[part 15 of 23: packages /Cluster to /NmConfig]
AUTOSAR XML (schema 4-3-0)
package /Cluster  (continued)
  7 x lin cluster, all with baudrate=19200, protocol-name=LIN, protocol-version=2.0:  (continued)
    Klima_LIN5
      lin physical channel CHNL: comm-connectors=CN_Klima_LIN5
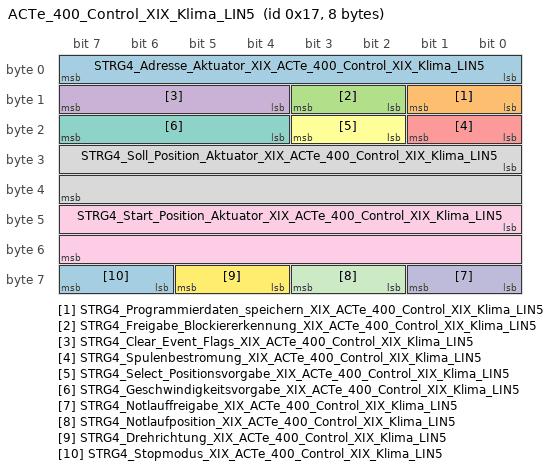
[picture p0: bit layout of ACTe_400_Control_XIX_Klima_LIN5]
        frame ACTe_400_Control_XIX_Klima_LIN5: id 0x17, from Klima, frame-length=8, lin-checksum=ENHANCED
          pdu ACTe_400_Control_XIX_Klima_LIN5: length=8, unused-bit-pattern=0
            signal STRG4_Adresse_Aktuator_XIX_ACTe_400_Control_XIX_Klima_LIN5: start 0, 8 bit, little-endian, data-type-policy=OVERRIDE, i-signal-type=PRIMITIVE, base-type=BT_STRG4_Adresse_Aktuator, invalid-value=Invalid_STRG4_Adresse_Aktuator_XIX_ACTe_400_Control_XIX_Klima_LIN5:255, compu {phys=raw for raw 0..254, 127=Cx7f_Broadcast (CM_STRG4_Adresse_Aktuator_Cx7f_Broadcast), 255=Cxff_Fehler (CM_STRG4_Adresse_Aktuator_Cxff_Fehler); unit Unit_None}, range phys 0..254 Unit_None, raw 0..255, unit=Unit_None, transfer-property=PENDING  # Zielempfängerauswahl, Steuerungsbotschaft für Aktuatoren
            signal STRG4_Programmierdaten_speichern_XIX_ACTe_400_Control_XIX_Klima_LIN5: start 8, 2 bit, little-endian, data-type-policy=OVERRIDE, i-signal-type=PRIMITIVE, init-value=0, base-type=BT_STRG4_Programmierdaten_speichern, invalid-value=Invalid_STRG4_Programmierdaten_speichern_XIX_ACTe_400_Control_XIX_Klima_LIN5:3, compu {0=Cx0_Programmierdaten_nicht_speichern (CM_STRG4_Programmierdaten_speichern_Cx0_Programmierdaten_nicht_speichern), 1=Cx1_Programmierdaten_speichern (CM_STRG4_Programmierdaten_speichern_Cx1_Programmierdaten_speichern), 2=Cx2_reserviert (CM_STRG4_Programmierdaten_speichern_Cx2_reserviert), 3=Cx3_Fehler (CM_STRG4_Programmierdaten_speichern_Cx3_Fehler)}, range raw 0..3, transfer-property=PENDING  # Speicherung der Programmierdaten
            signal STRG4_Freigabe_Blockiererkennung_XIX_ACTe_400_Control_XIX_Klima_LIN5: start 10, 2 bit, little-endian, data-type-policy=OVERRIDE, i-signal-type=PRIMITIVE, base-type=BT_STRG4_Freigabe_Blockiererkennung, invalid-value=Invalid_STRG4_Freigabe_Blockiererkennung_XIX_ACTe_400_Control_XIX_Klima_LIN5:3, compu {0=Cx0_Blockiererkennung_aus (CM_STRG4_Freigabe_Blockiererkennung_Cx0_Blockiererkennung_aus), 1=Cx1_Blockiererkennung_ein (CM_STRG4_Freigabe_Blockiererkennung_Cx1_Blockiererkennung_ein), 2=Cx2_reserviert (CM_STRG4_Freigabe_Blockiererkennung_Cx2_reserviert), 3=Cx3_Fehler (CM_STRG4_Freigabe_Blockiererkennung_Cx3_Fehler)}, range raw 0..3, transfer-property=PENDING  # Das Master-SG gibt eine aktive oder inaktive Blockiererkennung vor
            signal STRG4_Clear_Event_Flags_XIX_ACTe_400_Control_XIX_Klima_LIN5: start 12, 4 bit, little-endian, data-type-policy=OVERRIDE, i-signal-type=PRIMITIVE, init-value=0, base-type=BT_STRG4_Clear_Event_Flags, invalid-value=Invalid_STRG4_Clear_Event_Flags_XIX_ACTe_400_Control_XIX_Klima_LIN5:15, compu {0=Cx0_Event_Flags_nicht_zuruecksetzen (CM_STRG4_Clear_Event_Flags_Cx0_Event_Flags_nicht_zuruecksetzen), 2=Cx2_Clear_Notlauf_aufgetreten (CM_STRG4_Clear_Event_Flags_Cx2_Clear_Notlauf_aufgetreten), 4=Cx4_Clear_Blockierung_aufgetreten (CM_STRG4_Clear_Event_Flags_Cx4_Clear_Blockierung_aufgetreten), 6=Cx6_Clear_Notlauf_und_Blockierung (CM_STRG4_Clear_Event_Flags_Cx6_Clear_Notlauf_und_Blockierung), 8=Cx8_Clear_Reset (CM_STRG4_Clear_Event_Flags_Cx8_Clear_Reset), 10=Cxa_Clear_Notlauf_und_Reset (CM_STRG4_Clear_Event_Flags_Cxa_Clear_Notlauf_und_Reset), 12=Cxc_Clear_Blockierung_und_Reset (CM_STRG4_Clear_Event_Flags_Cxc_Clear_Blockierung_und_Reset), 14=Cxe_Clear_Notlauf_und_Block_u_Reset (CM_STRG4_Clear_Event_Flags_Cxe_Clear_Notlauf_und_Block_u_Reset), 15=Cxf_Fehler (CM_STRG4_Clear_Event_Flags_Cxf_Fehler)}, range raw 0..15, transfer-property=PENDING  # Das Steuergerät löscht die Event-Flags
            signal STRG4_Spulenbestromung_XIX_ACTe_400_Control_XIX_Klima_LIN5: start 16, 2 bit, little-endian, data-type-policy=OVERRIDE, i-signal-type=PRIMITIVE, base-type=BT_STRG4_Spulenbestromung, invalid-value=Invalid_STRG4_Spulenbestromung_XIX_ACTe_400_Control_XIX_Klima_LIN5:3, compu {0=Cx0_Motorspulen_unbestromt (CM_STRG4_Spulenbestromung_Cx0_Motorspulen_unbestromt), 1=Cx1_Motorspulen_bestromt (CM_STRG4_Spulenbestromung_Cx1_Motorspulen_bestromt), 2=Cx2_reserviert (CM_STRG4_Spulenbestromung_Cx2_reserviert), 3=Cx3_Fehler (CM_STRG4_Spulenbestromung_Cx3_Fehler)}, range raw 0..3, transfer-property=PENDING  # Spulenbestromungszustandsvorgabe, Steuerungsbotschaft für Aktuatoren
            signal STRG4_Select_Positionsvorgabe_XIX_ACTe_400_Control_XIX_Klima_LIN5: start 18, 2 bit, little-endian, data-type-policy=OVERRIDE, i-signal-type=PRIMITIVE, init-value=2, base-type=BT_STRG4_Select_Positionsvorgabe, invalid-value=Invalid_STRG4_Select_Positionsvorgabe_XIX_ACTe_400_Control_XIX_Klima_LIN5:3, compu {0=Cx0_Soll_Position_gueltig (CM_STRG4_Select_Positionsvorgabe_Cx0_Soll_Position_gueltig), 1=Cx1_Start_Position_gueltig (CM_STRG4_Select_Positionsvorgabe_Cx1_Start_Position_gueltig), 2=Cx2_keine_Positionsvorgabe_gueltig (CM_STRG4_Select_Positionsvorgabe_Cx2_keine_Positionsvorgabe_gueltig), 3=Cx3_Fehler (CM_STRG4_Select_Positionsvorgabe_Cx3_Fehler)}, range raw 0..3, transfer-property=PENDING  # Vorgabe der Gültigkeit der Positionsvorgaben, Steuerungsbotschaft für Aktuatoren
            signal STRG4_Geschwindigkeitsvorgabe_XIX_ACTe_400_Control_XIX_Klima_LIN5: start 20, 4 bit, little-endian, data-type-policy=OVERRIDE, i-signal-type=PRIMITIVE, base-type=BT_STRG4_Geschwindigkeitsvorgabe, invalid-value=Invalid_STRG4_Geschwindigkeitsvorgabe_XIX_ACTe_400_Control_XIX_Klima_LIN5:15, compu {0=Cx0_reserviert (CM_STRG4_Geschwindigkeitsvorgabe_Cx0_reserviert), 1=Cx1_Geschwindigkeitsstufe_1 (CM_STRG4_Geschwindigkeitsvorgabe_Cx1_Geschwindigkeitsstufe_1), 2=Cx2_Geschwindigkeitsstufe_2 (CM_STRG4_Geschwindigkeitsvorgabe_Cx2_Geschwindigkeitsstufe_2), 3=Cx3_Geschwindigkeitsstufe_3 (CM_STRG4_Geschwindigkeitsvorgabe_Cx3_Geschwindigkeitsstufe_3), 4=Cx4_Geschwindigkeitsstufe_4 (CM_STRG4_Geschwindigkeitsvorgabe_Cx4_Geschwindigkeitsstufe_4), 5=Cx5_Autospeed (CM_STRG4_Geschwindigkeitsvorgabe_Cx5_Autospeed), 15=Cxf_Fehler (CM_STRG4_Geschwindigkeitsvorgabe_Cxf_Fehler)}, range raw 0..15, transfer-property=PENDING  # Vorgabe der Geschwindigkeit, Steuerungsbotschaft für Aktuatoren
            signal STRG4_Soll_Position_Aktuator_XIX_ACTe_400_Control_XIX_Klima_LIN5: start 24, 16 bit, little-endian, data-type-policy=OVERRIDE, i-signal-type=PRIMITIVE, base-type=BT_STRG4_Soll_Position_Aktuator, invalid-value=Invalid_STRG4_Soll_Position_Aktuator_XIX_ACTe_400_Control_XIX_Klima_LIN5:65535, compu {phys=raw for raw 0..65534, 65535=Cxffff_Fehler (CM_STRG4_Soll_Position_Aktuator_Cxffff_Fehler); unit Unit_None}, range phys 0..65534 Unit_None, raw 0..65535, unit=Unit_None, transfer-property=PENDING  # Vorgabe der Sollposition, Steuerungsbotschaft für die Aktuatoren
            signal STRG4_Start_Position_Aktuator_XIX_ACTe_400_Control_XIX_Klima_LIN5: start 40, 16 bit, little-endian, data-type-policy=OVERRIDE, i-signal-type=PRIMITIVE, base-type=BT_STRG4_Start_Position_Aktuator, invalid-value=Invalid_STRG4_Start_Position_Aktuator_XIX_ACTe_400_Control_XIX_Klima_LIN5:65535, compu {phys=raw for raw 0..65534, 65535=Cxffff_Fehler (CM_STRG4_Start_Position_Aktuator_Cxffff_Fehler); unit Unit_None}, range phys 0..65534 Unit_None, raw 0..65535, unit=Unit_None, transfer-property=PENDING  # Vorgabe der Startposition
            signal STRG4_Notlauffreigabe_XIX_ACTe_400_Control_XIX_Klima_LIN5: start 56, 2 bit, little-endian, data-type-policy=OVERRIDE, i-signal-type=PRIMITIVE, base-type=BT_STRG4_Notlauffreigabe, invalid-value=Invalid_STRG4_Notlauffreigabe_XIX_ACTe_400_Control_XIX_Klima_LIN5:3, compu {0=Cx0_Notlauf_aus (CM_STRG4_Notlauffreigabe_Cx0_Notlauf_aus), 1=Cx1_Notlauf_ein (CM_STRG4_Notlauffreigabe_Cx1_Notlauf_ein), 2=Cx2_reserviert (CM_STRG4_Notlauffreigabe_Cx2_reserviert), 3=Cx3_Fehler (CM_STRG4_Notlauffreigabe_Cx3_Fehler)}, range raw 0..3, transfer-property=PENDING  # Freigabe der Notlaufeigenschaft, Steuerungsbotschaft für Aktuatoren
            signal STRG4_Notlaufposition_XIX_ACTe_400_Control_XIX_Klima_LIN5: start 58, 2 bit, little-endian, data-type-policy=OVERRIDE, i-signal-type=PRIMITIVE, base-type=BT_STRG4_Notlaufposition, invalid-value=Invalid_STRG4_Notlaufposition_XIX_ACTe_400_Control_XIX_Klima_LIN5:3, compu {0=Cx0_unterer_Anschlag (CM_STRG4_Notlaufposition_Cx0_unterer_Anschlag), 1=Cx1_oberer_Anschlag (CM_STRG4_Notlaufposition_Cx1_oberer_Anschlag), 2=Cx2_reserviert (CM_STRG4_Notlaufposition_Cx2_reserviert), 3=Cx3_Fehler (CM_STRG4_Notlaufposition_Cx3_Fehler)}, range raw 0..3, transfer-property=PENDING  # Positionsvorgabe, welche bei aktiven Notlauf angelaufen wird
            signal STRG4_Drehrichtung_XIX_ACTe_400_Control_XIX_Klima_LIN5: start 60, 2 bit, little-endian, data-type-policy=OVERRIDE, i-signal-type=PRIMITIVE, base-type=BT_STRG4_Drehrichtung, invalid-value=Invalid_STRG4_Drehrichtung_XIX_ACTe_400_Control_XIX_Klima_LIN5:3, compu {0=Cx0_Bewegung_in_Richtung_CW (CM_STRG4_Drehrichtung_Cx0_Bewegung_in_Richtung_CW), 1=Cx1_Bewegung_in_Richtung_CCW (CM_STRG4_Drehrichtung_Cx1_Bewegung_in_Richtung_CCW), 2=Cx2_reserviert (CM_STRG4_Drehrichtung_Cx2_reserviert), 3=Cx3_Fehler (CM_STRG4_Drehrichtung_Cx3_Fehler)}, range raw 0..3, transfer-property=PENDING  # Vorgabe der Drehrichtung
            signal STRG4_Stopmodus_XIX_ACTe_400_Control_XIX_Klima_LIN5: start 62, 2 bit, little-endian, data-type-policy=OVERRIDE, i-signal-type=PRIMITIVE, base-type=BT_STRG4_Stopmodus, invalid-value=Invalid_STRG4_Stopmodus_XIX_ACTe_400_Control_XIX_Klima_LIN5:3, compu {0=Cx0_normal_mode (CM_STRG4_Stopmodus_Cx0_normal_mode), 1=Cx1_stop_mode (CM_STRG4_Stopmodus_Cx1_stop_mode), 2=Cx2_reserviert (CM_STRG4_Stopmodus_Cx2_reserviert), 3=Cx3_Fehler (CM_STRG4_Stopmodus_Cx3_Fehler)}, range raw 0..3, transfer-property=PENDING  # Vorgabe des StopModus
        frame ACTs_401_Status_XIX_Klima_LIN5: id 0x18, to Klima, frame-length=8, lin-checksum=ENHANCED
          pdu ACTs_401_Status_XIX_Klima_LIN5: length=8, unused-bit-pattern=0
            signal ACT401_ResponseError_XIX_ACTs_401_Status_XIX_Klima_LIN5: start 0, 1 bit, little-endian, data-type-policy=OVERRIDE, i-signal-type=PRIMITIVE, init-value=0, base-type=BT_ACT401_ResponseError, invalid-value=Invalid_ACT401_ResponseError_XIX_ACTs_401_Status_XIX_Klima_LIN5:1, compu {0=Cx0_normal (CM_ACT401_ResponseError_Cx0_normal), 1=Cx1_Fehler (CM_ACT401_ResponseError_Cx1_Fehler)}, range raw 0..1, transfer-property=PENDING, to Klima(timeout 3.5 s)  # siehe LIN2.0-Specification (Darf nicht über ein Fehlergueltigkeitsbit abgesichtert werden!)
            signal ACT401_Uebertemperatur_XIX_ACTs_401_Status_XIX_Klima_LIN5: start 2, 2 bit, little-endian, data-type-policy=OVERRIDE, i-signal-type=PRIMITIVE, init-value=0, base-type=BT_ACT401_Uebertemperatur, invalid-value=Invalid_ACT401_Uebertemperatur_XIX_ACTs_401_Status_XIX_Klima_LIN5:3, compu {0=Cx0_keine_Uebertemperatur (CM_ACT401_Uebertemperatur_Cx0_keine_Uebertemperatur), 1=Cx1_Uebertemperatur (CM_ACT401_Uebertemperatur_Cx1_Uebertemperatur), 2=Cx2_reserviert (CM_ACT401_Uebertemperatur_Cx2_reserviert), 3=Cx3_Fehler (CM_ACT401_Uebertemperatur_Cx3_Fehler)}, range raw 0..3, transfer-property=PENDING, to Klima(timeout 3.5 s)  # Anzeige einer Übertemperatur im Stellmotoren-ASIC
            signal ACT401_Elektr_Defekt_XIX_ACTs_401_Status_XIX_Klima_LIN5: start 4, 2 bit, little-endian, data-type-policy=OVERRIDE, i-signal-type=PRIMITIVE, init-value=0, base-type=BT_ACT401_Elektr_Defekt, invalid-value=Invalid_ACT401_Elektr_Defekt_XIX_ACTs_401_Status_XIX_Klima_LIN5:3, compu {0=Cx0_kein_Fehler (CM_ACT401_Elektr_Defekt_Cx0_kein_Fehler), 1=Cx1_Elektrischer_Fehler_vorhanden (CM_ACT401_Elektr_Defekt_Cx1_Elektrischer_Fehler_vorhanden), 2=Cx2_Permanent_elekt_Fehler_vorhanden (CM_ACT401_Elektr_Defekt_Cx2_Permanent_elekt_Fehler_vorhanden), 3=Cx3_Fehler (CM_ACT401_Elektr_Defekt_Cx3_Fehler)}, range raw 0..3, transfer-property=PENDING, to Klima(timeout 3.5 s)  # Anzeige für einen elektrischen Fehler oder einen permanent el. Fehler im Stellmotor
            signal ACT401_Versorgungsspannung_XIX_ACTs_401_Status_XIX_Klima_LIN5: start 6, 2 bit, little-endian, data-type-policy=OVERRIDE, i-signal-type=PRIMITIVE, init-value=0, base-type=BT_ACT401_Versorgungsspannung, invalid-value=Invalid_ACT401_Versorgungsspannung_XIX_ACTs_401_Status_XIX_Klima_LIN5:3, compu {0=Cx0_Spannung_im_zulaessigen_Bereich (CM_ACT401_Versorgungsspannung_Cx0_Spannung_im_zulaessigen_Bereich), 1=Cx1_Unterspannung (CM_ACT401_Versorgungsspannung_Cx1_Unterspannung), 2=Cx2_Ueberspanung (CM_ACT401_Versorgungsspannung_Cx2_Ueberspanung), 3=Cx3_Fehler (CM_ACT401_Versorgungsspannung_Cx3_Fehler)}, range raw 0..3, transfer-property=PENDING, to Klima(timeout 3.5 s)  # Versorgungsspannung des Aktuators
            signal ACT401_Notlauf_aufgetreten_XIX_ACTs_401_Status_XIX_Klima_LIN5: start 8, 2 bit, little-endian, data-type-policy=OVERRIDE, i-signal-type=PRIMITIVE, init-value=0, base-type=BT_ACT401_Notlauf_aufgetreten, invalid-value=Invalid_ACT401_Notlauf_aufgetreten_XIX_ACTs_401_Status_XIX_Klima_LIN5:3, compu {0=Cx0_kein_Notlauf_aufgetreten (CM_ACT401_Notlauf_aufgetreten_Cx0_kein_Notlauf_aufgetreten), 1=Cx1_Notlauf_aufgetreten (CM_ACT401_Notlauf_aufgetreten_Cx1_Notlauf_aufgetreten), 2=Cx2_reserviert (CM_ACT401_Notlauf_aufgetreten_Cx2_reserviert), 3=Cx3_Fehler (CM_ACT401_Notlauf_aufgetreten_Cx3_Fehler)}, range raw 0..3, transfer-property=PENDING, to Klima(timeout 3.5 s)  # Anzeige eines aufgetretenen Notlaufs seit dem letzten Reset oder "Clear Notlauf aufgetreten"
            signal ACT401_Freigabe_Blockiererkennung_XIX_ACTs_401_Status_XIX_Klima_LIN5: start 10, 2 bit, little-endian, data-type-policy=OVERRIDE, i-signal-type=PRIMITIVE, init-value=0, base-type=BT_ACT401_Freigabe_Blockiererkennung, invalid-value=Invalid_ACT401_Freigabe_Blockiererkennung_XIX_ACTs_401_Status_XIX_Klima_LIN5:3, compu {0=Cx0_Blockiererkennung_aus (CM_ACT401_Freigabe_Blockiererkennung_Cx0_Blockiererkennung_aus), 1=Cx1_Blockiererkennung_ein (CM_ACT401_Freigabe_Blockiererkennung_Cx1_Blockiererkennung_ein), 2=Cx2_reserviert (CM_ACT401_Freigabe_Blockiererkennung_Cx2_reserviert), 3=Cx3_Fehler (CM_ACT401_Freigabe_Blockiererkennung_Cx3_Fehler)}, range raw 0..3, transfer-property=PENDING, to Klima(timeout 3.5 s)  # Aktivierung der Blockiererkennung im Aktuator
            signal ACT401_Blockierung_aufgetreten_XIX_ACTs_401_Status_XIX_Klima_LIN5: start 12, 2 bit, little-endian, data-type-policy=OVERRIDE, i-signal-type=PRIMITIVE, init-value=0, base-type=BT_ACT401_Blockierung_aufgetreten, invalid-value=Invalid_ACT401_Blockierung_aufgetreten_XIX_ACTs_401_Status_XIX_Klima_LIN5:3, compu {0=Cx0_keine_Blockierung (CM_ACT401_Blockierung_aufgetreten_Cx0_keine_Blockierung), 1=Cx1_Blockierung_erkannt (CM_ACT401_Blockierung_aufgetreten_Cx1_Blockierung_erkannt), 2=Cx2_reserviert (CM_ACT401_Blockierung_aufgetreten_Cx2_reserviert), 3=Cx3_Fehler (CM_ACT401_Blockierung_aufgetreten_Cx3_Fehler)}, range raw 0..3, transfer-property=PENDING, to Klima(timeout 3.5 s)  # Anzeige einer aufgetretenen Blockierung seit dem letzten Reset oder "Clear Blockierung aufgetreten"
            signal ACT401_Reset_XIX_ACTs_401_Status_XIX_Klima_LIN5: start 14, 2 bit, little-endian, data-type-policy=OVERRIDE, i-signal-type=PRIMITIVE, init-value=0, base-type=BT_ACT401_Reset, invalid-value=Invalid_ACT401_Reset_XIX_ACTs_401_Status_XIX_Klima_LIN5:3, compu {0=Cx0_kein_Reset (CM_ACT401_Reset_Cx0_kein_Reset), 1=Cx1_Reset_durchgefuehrt (CM_ACT401_Reset_Cx1_Reset_durchgefuehrt), 2=Cx2_reserviert (CM_ACT401_Reset_Cx2_reserviert), 3=Cx3_Fehler (CM_ACT401_Reset_Cx3_Fehler)}, range raw 0..3, transfer-property=PENDING, to Klima(timeout 3.5 s)  # Anzeige eines aufgetretenen Reset seit dem letzten ¿Clear Reset"
            signal ACT401_Spulenbestromung_XIX_ACTs_401_Status_XIX_Klima_LIN5: start 16, 2 bit, little-endian, data-type-policy=OVERRIDE, i-signal-type=PRIMITIVE, init-value=0, base-type=BT_ACT401_Spulenbestromung, invalid-value=Invalid_ACT401_Spulenbestromung_XIX_ACTs_401_Status_XIX_Klima_LIN5:3, compu {0=Cx0_Motorspulen_unbestromt (CM_ACT401_Spulenbestromung_Cx0_Motorspulen_unbestromt), 1=Cx1_Motorspulen_bestromt (CM_ACT401_Spulenbestromung_Cx1_Motorspulen_bestromt), 2=Cx2_reserviert (CM_ACT401_Spulenbestromung_Cx2_reserviert), 3=Cx3_Fehler (CM_ACT401_Spulenbestromung_Cx3_Fehler)}, range raw 0..3, transfer-property=PENDING, to Klima(timeout 3.5 s)  # Spulenbestromung im Haltezustand des Aktuators
            signal ACT401_Positionsvorgabe_Status_XIX_ACTs_401_Status_XIX_Klima_LIN5: start 18, 2 bit, little-endian, data-type-policy=OVERRIDE, i-signal-type=PRIMITIVE, init-value=0, base-type=BT_ACT401_Positionsvorgabe_Status, invalid-value=Invalid_ACT401_Positionsvorgabe_Status_XIX_ACTs_401_Status_XIX_Klima_LIN5:3, compu {0=Cx0_Soll_Position_gueltig (CM_ACT401_Positionsvorgabe_Status_Cx0_Soll_Position_gueltig), 1=Cx1_Start_Position_gueltig (CM_ACT401_Positionsvorgabe_Status_Cx1_Start_Position_gueltig), 2=Cx2_keine_Positionsvorgabe_gueltig (CM_ACT401_Positionsvorgabe_Status_Cx2_keine_Positionsvorgabe_gueltig), 3=Cx3_Fehler (CM_ACT401_Positionsvorgabe_Status_Cx3_Fehler)}, range raw 0..3, transfer-property=PENDING, to Klima(timeout 3.5 s)  # Position des Aktuators
            signal ACT401_Geschwindigkeitsstatus_XIX_ACTs_401_Status_XIX_Klima_LIN5: start 20, 4 bit, little-endian, data-type-policy=OVERRIDE, i-signal-type=PRIMITIVE, init-value=0, base-type=BT_ACT401_Geschwindigkeitsstatus, invalid-value=Invalid_ACT401_Geschwindigkeitsstatus_XIX_ACTs_401_Status_XIX_Klima_LIN5:15, compu {0=Cx0_Motor_steht (CM_ACT401_Geschwindigkeitsstatus_Cx0_Motor_steht), 1=Cx1_Geschwindigkeitsstufe_1 (CM_ACT401_Geschwindigkeitsstatus_Cx1_Geschwindigkeitsstufe_1), 2=Cx2_Geschwindigkeitsstufe_2 (CM_ACT401_Geschwindigkeitsstatus_Cx2_Geschwindigkeitsstufe_2), 3=Cx3_Geschwindigkeitsstufe_3 (CM_ACT401_Geschwindigkeitsstatus_Cx3_Geschwindigkeitsstufe_3), 4=Cx4_Geschwindigkeitsstufe_4 (CM_ACT401_Geschwindigkeitsstatus_Cx4_Geschwindigkeitsstufe_4), 5=Cx5_Autospeed (CM_ACT401_Geschwindigkeitsstatus_Cx5_Autospeed), 15=Cxf_Fehler (CM_ACT401_Geschwindigkeitsstatus_Cxf_Fehler)}, range raw 0..15, transfer-property=PENDING, to Klima(timeout 3.5 s)  # Geschwindigkeitsstufe mit der die aktuelle Verfahrbewegung durchgeführt wird
            signal ACT401_Ist_Position_Aktuator_XIX_ACTs_401_Status_XIX_Klima_LIN5: start 24, 16 bit, little-endian, data-type-policy=OVERRIDE, i-signal-type=PRIMITIVE, init-value=32767, base-type=BT_ACT401_Ist_Position_Aktuator, invalid-value=Invalid_ACT401_Ist_Position_Aktuator_XIX_ACTs_401_Status_XIX_Klima_LIN5:65535, compu {phys=raw for raw 0..65534, 32767=Cx7fff_Init (CM_ACT401_Ist_Position_Aktuator_Cx7fff_Init), 65535=Cxffff_Fehler (CM_ACT401_Ist_Position_Aktuator_Cxffff_Fehler); unit Unit_None}, range phys 0..65534 Unit_None, raw 0..65535, unit=Unit_None, transfer-property=PENDING, to Klima(timeout 3.5 s)  # IST-Position des Aktuators
            signal ACT401_Verfahrrichtung_XIX_ACTs_401_Status_XIX_Klima_LIN5: start 40, 2 bit, little-endian, data-type-policy=OVERRIDE, i-signal-type=PRIMITIVE, init-value=2, base-type=BT_ACT401_Verfahrrichtung, invalid-value=Invalid_ACT401_Verfahrrichtung_XIX_ACTs_401_Status_XIX_Klima_LIN5:3, compu {0=Cx0_Richtung_kl_Schrittpositionen (CM_ACT401_Verfahrrichtung_Cx0_Richtung_kl_Schrittpositionen), 1=Cx1_Richtung_gr_Schrittpositionen (CM_ACT401_Verfahrrichtung_Cx1_Richtung_gr_Schrittpositionen), 2=Cx2_Init (CM_ACT401_Verfahrrichtung_Cx2_Init), 3=Cx3_Fehler (CM_ACT401_Verfahrrichtung_Cx3_Fehler)}, range raw 0..3, transfer-property=PENDING, to Klima(timeout 3.5 s)  # Verfahrrichtung der aktuellen oder zuletzt stattgefundenen Bewegung des Aktuators
            signal ACT401_Selbsthaltemoment_XIX_ACTs_401_Status_XIX_Klima_LIN5: start 42, 2 bit, little-endian, data-type-policy=OVERRIDE, i-signal-type=PRIMITIVE, init-value=0, base-type=BT_ACT401_Selbsthaltemoment, invalid-value=Invalid_ACT401_Selbsthaltemoment_XIX_ACTs_401_Status_XIX_Klima_LIN5:3, compu {0=Cx0_ohne_Selbsthaltemoment (CM_ACT401_Selbsthaltemoment_Cx0_ohne_Selbsthaltemoment), 1=Cx1_mit_Selbsthaltemoment (CM_ACT401_Selbsthaltemoment_Cx1_mit_Selbsthaltemoment), 2=Cx2_reserviert (CM_ACT401_Selbsthaltemoment_Cx2_reserviert), 3=Cx3_Fehler (CM_ACT401_Selbsthaltemoment_Cx3_Fehler)}, range raw 0..3, transfer-property=PENDING, to Klima(timeout 3.5 s)  # Das Signal gibt an ob ein selbsthemmendes Getriebe verbaut ist oder die SHB eingeschaltet ist
            signal ACT401_Sonderfunktionen_XIX_ACTs_401_Status_XIX_Klima_LIN5: start 44, 2 bit, little-endian, data-type-policy=OVERRIDE, i-signal-type=PRIMITIVE, init-value=0, base-type=BT_ACT401_Sonderfunktionen, invalid-value=Invalid_ACT401_Sonderfunktionen_XIX_ACTs_401_Status_XIX_Klima_LIN5:3, compu {0=Cx0_Keine_Sonderfunktion_aktiv (CM_ACT401_Sonderfunktionen_Cx0_Keine_Sonderfunktion_aktiv), 1=Cx1_Sonderfunktion1_aktiv (CM_ACT401_Sonderfunktionen_Cx1_Sonderfunktion1_aktiv), 2=Cx2_Sonderfunktion2_aktiv (CM_ACT401_Sonderfunktionen_Cx2_Sonderfunktion2_aktiv), 3=Cx3_Fehler (CM_ACT401_Sonderfunktionen_Cx3_Fehler)}, range raw 0..3, transfer-property=PENDING, to Klima(timeout 3.5 s)  # Funktionen des Aktuators
            signal ACT401_Variante_XIX_ACTs_401_Status_XIX_Klima_LIN5: start 46, 2 bit, little-endian, data-type-policy=OVERRIDE, i-signal-type=PRIMITIVE, init-value=0, base-type=BT_ACT401_Variante, compu {0=Cx0_Variante_1 (CM_ACT401_Variante_Cx0_Variante_1), 1=Cx1_Variante_2 (CM_ACT401_Variante_Cx1_Variante_2), 2=Cx2_Variante_3 (CM_ACT401_Variante_Cx2_Variante_3), 3=Cx3_Fehler_oder_nicht_umgesetzt (CM_ACT401_Variante_Cx3_Fehler_oder_nicht_umgesetzt)}, range raw 0..3, transfer-property=PENDING, to Klima(timeout 3.5 s)  # Das Signal gibt an welche Variante des Stellmotors verbaut ist
            signal ACT401_Adresse_Aktuator_XIX_ACTs_401_Status_XIX_Klima_LIN5: start 48, 8 bit, little-endian, data-type-policy=OVERRIDE, i-signal-type=PRIMITIVE, init-value=255, base-type=BT_ACT401_Adresse_Aktuator, compu {255=Cxff_Init (CM_ACT401_Adresse_Aktuator_Cxff_Init)}, range raw 255, transfer-property=PENDING, to Klima(timeout 3.5 s)  # Adresse Aktuator
            signal ACT401_Notlauffreigabe_XIX_ACTs_401_Status_XIX_Klima_LIN5: start 56, 2 bit, little-endian, data-type-policy=OVERRIDE, i-signal-type=PRIMITIVE, init-value=0, base-type=BT_ACT401_Notlauffreigabe, invalid-value=Invalid_ACT401_Notlauffreigabe_XIX_ACTs_401_Status_XIX_Klima_LIN5:3, compu {0=Cx0_Notlauf_aus (CM_ACT401_Notlauffreigabe_Cx0_Notlauf_aus), 1=Cx1_Notlauf_ein (CM_ACT401_Notlauffreigabe_Cx1_Notlauf_ein), 2=Cx2_reserviert (CM_ACT401_Notlauffreigabe_Cx2_reserviert), 3=Cx3_Fehler (CM_ACT401_Notlauffreigabe_Cx3_Fehler)}, range raw 0..3, transfer-property=PENDING, to Klima(timeout 3.5 s)  # Freigabe der Notlauffunktion des Aktuators
            signal ACT401_Notlaufposition_XIX_ACTs_401_Status_XIX_Klima_LIN5: start 58, 2 bit, little-endian, data-type-policy=OVERRIDE, i-signal-type=PRIMITIVE, init-value=0, base-type=BT_ACT401_Notlaufposition, invalid-value=Invalid_ACT401_Notlaufposition_XIX_ACTs_401_Status_XIX_Klima_LIN5:3, compu {0=Cx0_unterer_Anschlag (CM_ACT401_Notlaufposition_Cx0_unterer_Anschlag), 1=Cx1_oberer_Anschlag (CM_ACT401_Notlaufposition_Cx1_oberer_Anschlag), 2=Cx2_reserviert (CM_ACT401_Notlaufposition_Cx2_reserviert), 3=Cx3_Fehler (CM_ACT401_Notlaufposition_Cx3_Fehler)}, range raw 0..3, transfer-property=PENDING, to Klima(timeout 3.5 s)  # Positionsvorgabe des Aktuators
            signal ACT401_Drehrichtung_XIX_ACTs_401_Status_XIX_Klima_LIN5: start 60, 2 bit, little-endian, data-type-policy=OVERRIDE, i-signal-type=PRIMITIVE, init-value=0, base-type=BT_ACT401_Drehrichtung, invalid-value=Invalid_ACT401_Drehrichtung_XIX_ACTs_401_Status_XIX_Klima_LIN5:3, compu {0=Cx0_Bewegung_in_Richtung_CW (CM_ACT401_Drehrichtung_Cx0_Bewegung_in_Richtung_CW), 1=Cx1_Bewegung_in_Richtung_CCW (CM_ACT401_Drehrichtung_Cx1_Bewegung_in_Richtung_CCW), 2=Cx2_reserviert (CM_ACT401_Drehrichtung_Cx2_reserviert), 3=Cx3_Fehler (CM_ACT401_Drehrichtung_Cx3_Fehler)}, range raw 0..3, transfer-property=PENDING, to Klima(timeout 3.5 s)  # Drehrichtung des Aktuators
            signal ACT401_Stopmodus_XIX_ACTs_401_Status_XIX_Klima_LIN5: start 62, 2 bit, little-endian, data-type-policy=OVERRIDE, i-signal-type=PRIMITIVE, init-value=0, base-type=BT_ACT401_Stopmodus, invalid-value=Invalid_ACT401_Stopmodus_XIX_ACTs_401_Status_XIX_Klima_LIN5:3, compu {0=Cx0_Normal_Mode (CM_ACT401_Stopmodus_Cx0_Normal_Mode), 1=Cx1_Stop_Mode (CM_ACT401_Stopmodus_Cx1_Stop_Mode), 2=Cx2_reserviert (CM_ACT401_Stopmodus_Cx2_reserviert), 3=Cx3_Fehler (CM_ACT401_Stopmodus_Cx3_Fehler)}, range raw 0..3, transfer-property=PENDING, to Klima(timeout 3.5 s)  # Modus des Aktuators
        frame ACTs_402_Status_XIX_Klima_LIN5: id 0x19, to Klima, frame-length=8, lin-checksum=ENHANCED
          pdu ACTs_402_Status_XIX_Klima_LIN5: length=8, unused-bit-pattern=0
            signal ACT402_ResponseError_XIX_ACTs_402_Status_XIX_Klima_LIN5: start 0, 1 bit, little-endian, data-type-policy=OVERRIDE, i-signal-type=PRIMITIVE, init-value=0, base-type=BT_ACT402_ResponseError, invalid-value=Invalid_ACT402_ResponseError_XIX_ACTs_402_Status_XIX_Klima_LIN5:1, compu {0=Cx0_normal (CM_ACT402_ResponseError_Cx0_normal), 1=Cx1_Fehler (CM_ACT402_ResponseError_Cx1_Fehler)}, range raw 0..1, transfer-property=PENDING, to Klima(timeout 3.5 s)  # siehe LIN2.0-Specification (Darf nicht über ein Fehlergueltigkeitsbit abgesichtert werden!)
            signal ACT402_Uebertemperatur_XIX_ACTs_402_Status_XIX_Klima_LIN5: start 2, 2 bit, little-endian, data-type-policy=OVERRIDE, i-signal-type=PRIMITIVE, init-value=0, base-type=BT_ACT402_Uebertemperatur, invalid-value=Invalid_ACT402_Uebertemperatur_XIX_ACTs_402_Status_XIX_Klima_LIN5:3, compu {0=Cx0_keine_Uebertemperatur (CM_ACT402_Uebertemperatur_Cx0_keine_Uebertemperatur), 1=Cx1_Uebertemperatur (CM_ACT402_Uebertemperatur_Cx1_Uebertemperatur), 2=Cx2_reserviert (CM_ACT402_Uebertemperatur_Cx2_reserviert), 3=Cx3_Fehler (CM_ACT402_Uebertemperatur_Cx3_Fehler)}, range raw 0..3, transfer-property=PENDING, to Klima(timeout 3.5 s)  # Anzeige einer Übertemperatur im Stellmotoren-ASIC
            signal ACT402_Elektr_Defekt_XIX_ACTs_402_Status_XIX_Klima_LIN5: start 4, 2 bit, little-endian, data-type-policy=OVERRIDE, i-signal-type=PRIMITIVE, init-value=0, base-type=BT_ACT402_Elektr_Defekt, invalid-value=Invalid_ACT402_Elektr_Defekt_XIX_ACTs_402_Status_XIX_Klima_LIN5:3, compu {0=Cx0_kein_Fehler (CM_ACT402_Elektr_Defekt_Cx0_kein_Fehler), 1=Cx1_Elektrischer_Fehler_vorhanden (CM_ACT402_Elektr_Defekt_Cx1_Elektrischer_Fehler_vorhanden), 2=Cx2_Permanent_elekt_Fehler_vorhanden (CM_ACT402_Elektr_Defekt_Cx2_Permanent_elekt_Fehler_vorhanden), 3=Cx3_Fehler (CM_ACT402_Elektr_Defekt_Cx3_Fehler)}, range raw 0..3, transfer-property=PENDING, to Klima(timeout 3.5 s)  # Anzeige für einen elektrischen Fehler oder einen permanent el. Fehler im Stellmotor
            signal ACT402_Versorgungsspannung_XIX_ACTs_402_Status_XIX_Klima_LIN5: start 6, 2 bit, little-endian, data-type-policy=OVERRIDE, i-signal-type=PRIMITIVE, init-value=0, base-type=BT_ACT402_Versorgungsspannung, invalid-value=Invalid_ACT402_Versorgungsspannung_XIX_ACTs_402_Status_XIX_Klima_LIN5:3, compu {0=Cx0_Spannung_im_zulaessigen_Bereich (CM_ACT402_Versorgungsspannung_Cx0_Spannung_im_zulaessigen_Bereich), 1=Cx1_Unterspannung (CM_ACT402_Versorgungsspannung_Cx1_Unterspannung), 2=Cx2_Ueberspanung (CM_ACT402_Versorgungsspannung_Cx2_Ueberspanung), 3=Cx3_Fehler (CM_ACT402_Versorgungsspannung_Cx3_Fehler)}, range raw 0..3, transfer-property=PENDING, to Klima(timeout 3.5 s)  # Versorgungsspannung des Aktuators
            signal ACT402_Notlauf_aufgetreten_XIX_ACTs_402_Status_XIX_Klima_LIN5: start 8, 2 bit, little-endian, data-type-policy=OVERRIDE, i-signal-type=PRIMITIVE, init-value=0, base-type=BT_ACT402_Notlauf_aufgetreten, invalid-value=Invalid_ACT402_Notlauf_aufgetreten_XIX_ACTs_402_Status_XIX_Klima_LIN5:3, compu {0=Cx0_kein_Notlauf_aufgetreten (CM_ACT402_Notlauf_aufgetreten_Cx0_kein_Notlauf_aufgetreten), 1=Cx1_Notlauf_aufgetreten (CM_ACT402_Notlauf_aufgetreten_Cx1_Notlauf_aufgetreten), 2=Cx2_reserviert (CM_ACT402_Notlauf_aufgetreten_Cx2_reserviert), 3=Cx3_Fehler (CM_ACT402_Notlauf_aufgetreten_Cx3_Fehler)}, range raw 0..3, transfer-property=PENDING, to Klima(timeout 3.5 s)  # Anzeige eines aufgetretenen Notlaufs seit dem letzten Reset oder "Clear Notlauf aufgetreten"
            signal ACT402_Freigabe_Blockiererkennung_XIX_ACTs_402_Status_XIX_Klima_LIN5: start 10, 2 bit, little-endian, data-type-policy=OVERRIDE, i-signal-type=PRIMITIVE, init-value=0, base-type=BT_ACT402_Freigabe_Blockiererkennung, invalid-value=Invalid_ACT402_Freigabe_Blockiererkennung_XIX_ACTs_402_Status_XIX_Klima_LIN5:3, compu {0=Cx0_Blockiererkennung_aus (CM_ACT402_Freigabe_Blockiererkennung_Cx0_Blockiererkennung_aus), 1=Cx1_Blockiererkennung_ein (CM_ACT402_Freigabe_Blockiererkennung_Cx1_Blockiererkennung_ein), 2=Cx2_reserviert (CM_ACT402_Freigabe_Blockiererkennung_Cx2_reserviert), 3=Cx3_Fehler (CM_ACT402_Freigabe_Blockiererkennung_Cx3_Fehler)}, range raw 0..3, transfer-property=PENDING, to Klima(timeout 3.5 s)  # Aktivierung der Blockiererkennung im Aktuator
            signal ACT402_Blockierung_aufgetreten_XIX_ACTs_402_Status_XIX_Klima_LIN5: start 12, 2 bit, little-endian, data-type-policy=OVERRIDE, i-signal-type=PRIMITIVE, init-value=0, base-type=BT_ACT402_Blockierung_aufgetreten, invalid-value=Invalid_ACT402_Blockierung_aufgetreten_XIX_ACTs_402_Status_XIX_Klima_LIN5:3, compu {0=Cx0_keine_Blockierung (CM_ACT402_Blockierung_aufgetreten_Cx0_keine_Blockierung), 1=Cx1_Blockierung_erkannt (CM_ACT402_Blockierung_aufgetreten_Cx1_Blockierung_erkannt), 2=Cx2_reserviert (CM_ACT402_Blockierung_aufgetreten_Cx2_reserviert), 3=Cx3_Fehler (CM_ACT402_Blockierung_aufgetreten_Cx3_Fehler)}, range raw 0..3, transfer-property=PENDING, to Klima(timeout 3.5 s)  # Anzeige einer aufgetretenen Blockierung seit dem letzten Reset oder "Clear Blockierung aufgetreten"
            signal ACT402_Reset_XIX_ACTs_402_Status_XIX_Klima_LIN5: start 14, 2 bit, little-endian, data-type-policy=OVERRIDE, i-signal-type=PRIMITIVE, init-value=0, base-type=BT_ACT402_Reset, invalid-value=Invalid_ACT402_Reset_XIX_ACTs_402_Status_XIX_Klima_LIN5:3, compu {0=Cx0_kein_Reset (CM_ACT402_Reset_Cx0_kein_Reset), 1=Cx1_Reset_durchgefuehrt (CM_ACT402_Reset_Cx1_Reset_durchgefuehrt), 2=Cx2_reserviert (CM_ACT402_Reset_Cx2_reserviert), 3=Cx3_Fehler (CM_ACT402_Reset_Cx3_Fehler)}, range raw 0..3, transfer-property=PENDING, to Klima(timeout 3.5 s)  # Anzeige eines aufgetretenen Reset seit dem letzten ¿Clear Reset"
            signal ACT402_Spulenbestromung_XIX_ACTs_402_Status_XIX_Klima_LIN5: start 16, 2 bit, little-endian, data-type-policy=OVERRIDE, i-signal-type=PRIMITIVE, init-value=0, base-type=BT_ACT402_Spulenbestromung, invalid-value=Invalid_ACT402_Spulenbestromung_XIX_ACTs_402_Status_XIX_Klima_LIN5:3, compu {0=Cx0_Motorspulen_unbestromt (CM_ACT402_Spulenbestromung_Cx0_Motorspulen_unbestromt), 1=Cx1_Motorspulen_bestromt (CM_ACT402_Spulenbestromung_Cx1_Motorspulen_bestromt), 2=Cx2_reserviert (CM_ACT402_Spulenbestromung_Cx2_reserviert), 3=Cx3_Fehler (CM_ACT402_Spulenbestromung_Cx3_Fehler)}, range raw 0..3, transfer-property=PENDING, to Klima(timeout 3.5 s)  # Spulenbestromung im Haltezustand des Aktuators
            signal ACT402_Positionsvorgabe_Status_XIX_ACTs_402_Status_XIX_Klima_LIN5: start 18, 2 bit, little-endian, data-type-policy=OVERRIDE, i-signal-type=PRIMITIVE, init-value=0, base-type=BT_ACT402_Positionsvorgabe_Status, invalid-value=Invalid_ACT402_Positionsvorgabe_Status_XIX_ACTs_402_Status_XIX_Klima_LIN5:3, compu {0=Cx0_Soll_Position_gueltig (CM_ACT402_Positionsvorgabe_Status_Cx0_Soll_Position_gueltig), 1=Cx1_Start_Position_gueltig (CM_ACT402_Positionsvorgabe_Status_Cx1_Start_Position_gueltig), 2=Cx2_keine_Positionsvorgabe_gueltig (CM_ACT402_Positionsvorgabe_Status_Cx2_keine_Positionsvorgabe_gueltig), 3=Cx3_Fehler (CM_ACT402_Positionsvorgabe_Status_Cx3_Fehler)}, range raw 0..3, transfer-property=PENDING, to Klima(timeout 3.5 s)  # Position des Aktuators
            signal ACT402_Geschwindigkeitsstatus_XIX_ACTs_402_Status_XIX_Klima_LIN5: start 20, 4 bit, little-endian, data-type-policy=OVERRIDE, i-signal-type=PRIMITIVE, init-value=0, base-type=BT_ACT402_Geschwindigkeitsstatus, invalid-value=Invalid_ACT402_Geschwindigkeitsstatus_XIX_ACTs_402_Status_XIX_Klima_LIN5:15, compu {0=Cx0_Motor_steht (CM_ACT402_Geschwindigkeitsstatus_Cx0_Motor_steht), 1=Cx1_Geschwindigkeitsstufe_1 (CM_ACT402_Geschwindigkeitsstatus_Cx1_Geschwindigkeitsstufe_1), 2=Cx2_Geschwindigkeitsstufe_2 (CM_ACT402_Geschwindigkeitsstatus_Cx2_Geschwindigkeitsstufe_2), 3=Cx3_Geschwindigkeitsstufe_3 (CM_ACT402_Geschwindigkeitsstatus_Cx3_Geschwindigkeitsstufe_3), 4=Cx4_Geschwindigkeitsstufe_4 (CM_ACT402_Geschwindigkeitsstatus_Cx4_Geschwindigkeitsstufe_4), 5=Cx5_Autospeed (CM_ACT402_Geschwindigkeitsstatus_Cx5_Autospeed), 15=Cxf_Fehler (CM_ACT402_Geschwindigkeitsstatus_Cxf_Fehler)}, range raw 0..15, transfer-property=PENDING, to Klima(timeout 3.5 s)  # Geschwindigkeitsstufe mit der die aktuelle Verfahrbewegung durchgeführt wird
            signal ACT402_Ist_Position_Aktuator_XIX_ACTs_402_Status_XIX_Klima_LIN5: start 24, 16 bit, little-endian, data-type-policy=OVERRIDE, i-signal-type=PRIMITIVE, init-value=32767, base-type=BT_ACT402_Ist_Position_Aktuator, invalid-value=Invalid_ACT402_Ist_Position_Aktuator_XIX_ACTs_402_Status_XIX_Klima_LIN5:65535, compu {phys=raw for raw 0..65534, 32767=Cx7fff_Init (CM_ACT402_Ist_Position_Aktuator_Cx7fff_Init), 65535=Cxffff_Fehler (CM_ACT402_Ist_Position_Aktuator_Cxffff_Fehler); unit Unit_None}, range phys 0..65534 Unit_None, raw 0..65535, unit=Unit_None, transfer-property=PENDING, to Klima(timeout 3.5 s)  # IST-Position des Aktuators
            signal ACT402_Verfahrrichtung_XIX_ACTs_402_Status_XIX_Klima_LIN5: start 40, 2 bit, little-endian, data-type-policy=OVERRIDE, i-signal-type=PRIMITIVE, init-value=2, base-type=BT_ACT402_Verfahrrichtung, invalid-value=Invalid_ACT402_Verfahrrichtung_XIX_ACTs_402_Status_XIX_Klima_LIN5:3, compu {0=Cx0_Richtung_kl_Schrittpositionen (CM_ACT402_Verfahrrichtung_Cx0_Richtung_kl_Schrittpositionen), 1=Cx1_Richtung_gr_Schrittpositionen (CM_ACT402_Verfahrrichtung_Cx1_Richtung_gr_Schrittpositionen), 2=Cx2_Init (CM_ACT402_Verfahrrichtung_Cx2_Init), 3=Cx3_Fehler (CM_ACT402_Verfahrrichtung_Cx3_Fehler)}, range raw 0..3, transfer-property=PENDING, to Klima(timeout 3.5 s)  # Verfahrrichtung der aktuellen oder zuletzt stattgefundenen Bewegung des Aktuators
            signal ACT402_Selbsthaltemoment_XIX_ACTs_402_Status_XIX_Klima_LIN5: start 42, 2 bit, little-endian, data-type-policy=OVERRIDE, i-signal-type=PRIMITIVE, init-value=0, base-type=BT_ACT402_Selbsthaltemoment, invalid-value=Invalid_ACT402_Selbsthaltemoment_XIX_ACTs_402_Status_XIX_Klima_LIN5:3, compu {0=Cx0_ohne_Selbsthaltemoment (CM_ACT402_Selbsthaltemoment_Cx0_ohne_Selbsthaltemoment), 1=Cx1_mit_Selbsthaltemoment (CM_ACT402_Selbsthaltemoment_Cx1_mit_Selbsthaltemoment), 2=Cx2_reserviert (CM_ACT402_Selbsthaltemoment_Cx2_reserviert), 3=Cx3_Fehler (CM_ACT402_Selbsthaltemoment_Cx3_Fehler)}, range raw 0..3, transfer-property=PENDING, to Klima(timeout 3.5 s)  # Das Signal gibt an ob ein selbsthemmendes Getriebe verbaut ist oder die SHB eingeschaltet ist
            signal ACT402_Sonderfunktionen_XIX_ACTs_402_Status_XIX_Klima_LIN5: start 44, 2 bit, little-endian, data-type-policy=OVERRIDE, i-signal-type=PRIMITIVE, init-value=0, base-type=BT_ACT402_Sonderfunktionen, invalid-value=Invalid_ACT402_Sonderfunktionen_XIX_ACTs_402_Status_XIX_Klima_LIN5:3, compu {0=Cx0_Keine_Sonderfunktion_aktiv (CM_ACT402_Sonderfunktionen_Cx0_Keine_Sonderfunktion_aktiv), 1=Cx1_Sonderfunktion1_aktiv (CM_ACT402_Sonderfunktionen_Cx1_Sonderfunktion1_aktiv), 2=Cx2_Sonderfunktion2_aktiv (CM_ACT402_Sonderfunktionen_Cx2_Sonderfunktion2_aktiv), 3=Cx3_Fehler (CM_ACT402_Sonderfunktionen_Cx3_Fehler)}, range raw 0..3, transfer-property=PENDING, to Klima(timeout 3.5 s)  # Funktionen des Aktuators
            signal ACT402_Variante_XIX_ACTs_402_Status_XIX_Klima_LIN5: start 46, 2 bit, little-endian, data-type-policy=OVERRIDE, i-signal-type=PRIMITIVE, init-value=0, base-type=BT_ACT402_Variante, compu {0=Cx0_Variante_1 (CM_ACT402_Variante_Cx0_Variante_1), 1=Cx1_Variante_2 (CM_ACT402_Variante_Cx1_Variante_2), 2=Cx2_Variante_3 (CM_ACT402_Variante_Cx2_Variante_3), 3=Cx3_Fehler_oder_nicht_umgesetzt (CM_ACT402_Variante_Cx3_Fehler_oder_nicht_umgesetzt)}, range raw 0..3, transfer-property=PENDING, to Klima(timeout 3.5 s)  # Das Signal gibt an welche Variante des Stellmotors verbaut ist
            signal ACT402_Adresse_Aktuator_XIX_ACTs_402_Status_XIX_Klima_LIN5: start 48, 8 bit, little-endian, data-type-policy=OVERRIDE, i-signal-type=PRIMITIVE, init-value=255, base-type=BT_ACT402_Adresse_Aktuator, compu {255=Cxff_Init (CM_ACT402_Adresse_Aktuator_Cxff_Init)}, range raw 255, transfer-property=PENDING, to Klima(timeout 3.5 s)  # Adresse Aktuator
            signal ACT402_Notlauffreigabe_XIX_ACTs_402_Status_XIX_Klima_LIN5: start 56, 2 bit, little-endian, data-type-policy=OVERRIDE, i-signal-type=PRIMITIVE, init-value=0, base-type=BT_ACT402_Notlauffreigabe, invalid-value=Invalid_ACT402_Notlauffreigabe_XIX_ACTs_402_Status_XIX_Klima_LIN5:3, compu {0=Cx0_Notlauf_aus (CM_ACT402_Notlauffreigabe_Cx0_Notlauf_aus), 1=Cx1_Notlauf_ein (CM_ACT402_Notlauffreigabe_Cx1_Notlauf_ein), 2=Cx2_reserviert (CM_ACT402_Notlauffreigabe_Cx2_reserviert), 3=Cx3_Fehler (CM_ACT402_Notlauffreigabe_Cx3_Fehler)}, range raw 0..3, transfer-property=PENDING, to Klima(timeout 3.5 s)  # Freigabe der Notlauffunktion des Aktuators
            signal ACT402_Notlaufposition_XIX_ACTs_402_Status_XIX_Klima_LIN5: start 58, 2 bit, little-endian, data-type-policy=OVERRIDE, i-signal-type=PRIMITIVE, init-value=0, base-type=BT_ACT402_Notlaufposition, invalid-value=Invalid_ACT402_Notlaufposition_XIX_ACTs_402_Status_XIX_Klima_LIN5:3, compu {0=Cx0_unterer_Anschlag (CM_ACT402_Notlaufposition_Cx0_unterer_Anschlag), 1=Cx1_oberer_Anschlag (CM_ACT402_Notlaufposition_Cx1_oberer_Anschlag), 2=Cx2_reserviert (CM_ACT402_Notlaufposition_Cx2_reserviert), 3=Cx3_Fehler (CM_ACT402_Notlaufposition_Cx3_Fehler)}, range raw 0..3, transfer-property=PENDING, to Klima(timeout 3.5 s)  # Positionsvorgabe des Aktuators
            signal ACT402_Drehrichtung_XIX_ACTs_402_Status_XIX_Klima_LIN5: start 60, 2 bit, little-endian, data-type-policy=OVERRIDE, i-signal-type=PRIMITIVE, init-value=0, base-type=BT_ACT402_Drehrichtung, invalid-value=Invalid_ACT402_Drehrichtung_XIX_ACTs_402_Status_XIX_Klima_LIN5:3, compu {0=Cx0_Bewegung_in_Richtung_CW (CM_ACT402_Drehrichtung_Cx0_Bewegung_in_Richtung_CW), 1=Cx1_Bewegung_in_Richtung_CCW (CM_ACT402_Drehrichtung_Cx1_Bewegung_in_Richtung_CCW), 2=Cx2_reserviert (CM_ACT402_Drehrichtung_Cx2_reserviert), 3=Cx3_Fehler (CM_ACT402_Drehrichtung_Cx3_Fehler)}, range raw 0..3, transfer-property=PENDING, to Klima(timeout 3.5 s)  # Drehrichtung des Aktuators
            signal ACT402_Stopmodus_XIX_ACTs_402_Status_XIX_Klima_LIN5: start 62, 2 bit, little-endian, data-type-policy=OVERRIDE, i-signal-type=PRIMITIVE, init-value=0, base-type=BT_ACT402_Stopmodus, invalid-value=Invalid_ACT402_Stopmodus_XIX_ACTs_402_Status_XIX_Klima_LIN5:3, compu {0=Cx0_Normal_Mode (CM_ACT402_Stopmodus_Cx0_Normal_Mode), 1=Cx1_Stop_Mode (CM_ACT402_Stopmodus_Cx1_Stop_Mode), 2=Cx2_reserviert (CM_ACT402_Stopmodus_Cx2_reserviert), 3=Cx3_Fehler (CM_ACT402_Stopmodus_Cx3_Fehler)}, range raw 0..3, transfer-property=PENDING, to Klima(timeout 3.5 s)  # Modus des Aktuators
        frame ACTs_403_Status_XIX_Klima_LIN5: id 0x1A, to Klima, frame-length=8, lin-checksum=ENHANCED
          pdu ACTs_403_Status_XIX_Klima_LIN5: length=8, unused-bit-pattern=0
            signal ACT403_ResponseError_XIX_ACTs_403_Status_XIX_Klima_LIN5: start 0, 1 bit, little-endian, data-type-policy=OVERRIDE, i-signal-type=PRIMITIVE, init-value=0, base-type=BT_ACT403_ResponseError, invalid-value=Invalid_ACT403_ResponseError_XIX_ACTs_403_Status_XIX_Klima_LIN5:1, compu {0=Cx0_normal (CM_ACT403_ResponseError_Cx0_normal), 1=Cx1_Fehler (CM_ACT403_ResponseError_Cx1_Fehler)}, range raw 0..1, transfer-property=PENDING, to Klima(timeout 3.5 s)  # siehe LIN2.0-Specification (Darf nicht über ein Fehlergueltigkeitsbit abgesichtert werden!)
            signal ACT403_Uebertemperatur_XIX_ACTs_403_Status_XIX_Klima_LIN5: start 2, 2 bit, little-endian, data-type-policy=OVERRIDE, i-signal-type=PRIMITIVE, init-value=0, base-type=BT_ACT403_Uebertemperatur, invalid-value=Invalid_ACT403_Uebertemperatur_XIX_ACTs_403_Status_XIX_Klima_LIN5:3, compu {0=Cx0_keine_Uebertemperatur (CM_ACT403_Uebertemperatur_Cx0_keine_Uebertemperatur), 1=Cx1_Uebertemperatur (CM_ACT403_Uebertemperatur_Cx1_Uebertemperatur), 2=Cx2_reserviert (CM_ACT403_Uebertemperatur_Cx2_reserviert), 3=Cx3_Fehler (CM_ACT403_Uebertemperatur_Cx3_Fehler)}, range raw 0..3, transfer-property=PENDING, to Klima(timeout 3.5 s)  # Anzeige einer Übertemperatur im Stellmotoren-ASIC
            signal ACT403_Elektr_Defekt_XIX_ACTs_403_Status_XIX_Klima_LIN5: start 4, 2 bit, little-endian, data-type-policy=OVERRIDE, i-signal-type=PRIMITIVE, init-value=0, base-type=BT_ACT403_Elektr_Defekt, invalid-value=Invalid_ACT403_Elektr_Defekt_XIX_ACTs_403_Status_XIX_Klima_LIN5:3, compu {0=Cx0_kein_Fehler (CM_ACT403_Elektr_Defekt_Cx0_kein_Fehler), 1=Cx1_Elektrischer_Fehler_vorhanden (CM_ACT403_Elektr_Defekt_Cx1_Elektrischer_Fehler_vorhanden), 2=Cx2_Permanent_elekt_Fehler_vorhanden (CM_ACT403_Elektr_Defekt_Cx2_Permanent_elekt_Fehler_vorhanden), 3=Cx3_Fehler (CM_ACT403_Elektr_Defekt_Cx3_Fehler)}, range raw 0..3, transfer-property=PENDING, to Klima(timeout 3.5 s)  # Anzeige für einen elektrischen Fehler oder einen permanent el. Fehler im Stellmotor
            signal ACT403_Versorgungsspannung_XIX_ACTs_403_Status_XIX_Klima_LIN5: start 6, 2 bit, little-endian, data-type-policy=OVERRIDE, i-signal-type=PRIMITIVE, init-value=0, base-type=BT_ACT403_Versorgungsspannung, invalid-value=Invalid_ACT403_Versorgungsspannung_XIX_ACTs_403_Status_XIX_Klima_LIN5:3, compu {0=Cx0_Spannung_im_zulaessigen_Bereich (CM_ACT403_Versorgungsspannung_Cx0_Spannung_im_zulaessigen_Bereich), 1=Cx1_Unterspannung (CM_ACT403_Versorgungsspannung_Cx1_Unterspannung), 2=Cx2_Ueberspanung (CM_ACT403_Versorgungsspannung_Cx2_Ueberspanung), 3=Cx3_Fehler (CM_ACT403_Versorgungsspannung_Cx3_Fehler)}, range raw 0..3, transfer-property=PENDING, to Klima(timeout 3.5 s)  # Versorgungsspannung des Aktuators
            signal ACT403_Notlauf_aufgetreten_XIX_ACTs_403_Status_XIX_Klima_LIN5: start 8, 2 bit, little-endian, data-type-policy=OVERRIDE, i-signal-type=PRIMITIVE, init-value=0, base-type=BT_ACT403_Notlauf_aufgetreten, invalid-value=Invalid_ACT403_Notlauf_aufgetreten_XIX_ACTs_403_Status_XIX_Klima_LIN5:3, compu {0=Cx0_kein_Notlauf_aufgetreten (CM_ACT403_Notlauf_aufgetreten_Cx0_kein_Notlauf_aufgetreten), 1=Cx1_Notlauf_aufgetreten (CM_ACT403_Notlauf_aufgetreten_Cx1_Notlauf_aufgetreten), 2=Cx2_reserviert (CM_ACT403_Notlauf_aufgetreten_Cx2_reserviert), 3=Cx3_Fehler (CM_ACT403_Notlauf_aufgetreten_Cx3_Fehler)}, range raw 0..3, transfer-property=PENDING, to Klima(timeout 3.5 s)  # Anzeige eines aufgetretenen Notlaufs seit dem letzten Reset oder "Clear Notlauf aufgetreten"
            signal ACT403_Freigabe_Blockiererkennung_XIX_ACTs_403_Status_XIX_Klima_LIN5: start 10, 2 bit, little-endian, data-type-policy=OVERRIDE, i-signal-type=PRIMITIVE, init-value=0, base-type=BT_ACT403_Freigabe_Blockiererkennung, invalid-value=Invalid_ACT403_Freigabe_Blockiererkennung_XIX_ACTs_403_Status_XIX_Klima_LIN5:3, compu {0=Cx0_Blockiererkennung_aus (CM_ACT403_Freigabe_Blockiererkennung_Cx0_Blockiererkennung_aus), 1=Cx1_Blockiererkennung_ein (CM_ACT403_Freigabe_Blockiererkennung_Cx1_Blockiererkennung_ein), 2=Cx2_reserviert (CM_ACT403_Freigabe_Blockiererkennung_Cx2_reserviert), 3=Cx3_Fehler (CM_ACT403_Freigabe_Blockiererkennung_Cx3_Fehler)}, range raw 0..3, transfer-property=PENDING, to Klima(timeout 3.5 s)  # Aktivierung der Blockiererkennung im Aktuator
            signal ACT403_Blockierung_aufgetreten_XIX_ACTs_403_Status_XIX_Klima_LIN5: start 12, 2 bit, little-endian, data-type-policy=OVERRIDE, i-signal-type=PRIMITIVE, init-value=0, base-type=BT_ACT403_Blockierung_aufgetreten, invalid-value=Invalid_ACT403_Blockierung_aufgetreten_XIX_ACTs_403_Status_XIX_Klima_LIN5:3, compu {0=Cx0_keine_Blockierung (CM_ACT403_Blockierung_aufgetreten_Cx0_keine_Blockierung), 1=Cx1_Blockierung_erkannt (CM_ACT403_Blockierung_aufgetreten_Cx1_Blockierung_erkannt), 2=Cx2_reserviert (CM_ACT403_Blockierung_aufgetreten_Cx2_reserviert), 3=Cx3_Fehler (CM_ACT403_Blockierung_aufgetreten_Cx3_Fehler)}, range raw 0..3, transfer-property=PENDING, to Klima(timeout 3.5 s)  # Anzeige einer aufgetretenen Blockierung seit dem letzten Reset oder "Clear Blockierung aufgetreten"
            signal ACT403_Reset_XIX_ACTs_403_Status_XIX_Klima_LIN5: start 14, 2 bit, little-endian, data-type-policy=OVERRIDE, i-signal-type=PRIMITIVE, init-value=0, base-type=BT_ACT403_Reset, invalid-value=Invalid_ACT403_Reset_XIX_ACTs_403_Status_XIX_Klima_LIN5:3, compu {0=Cx0_kein_Reset (CM_ACT403_Reset_Cx0_kein_Reset), 1=Cx1_Reset_durchgefuehrt (CM_ACT403_Reset_Cx1_Reset_durchgefuehrt), 2=Cx2_reserviert (CM_ACT403_Reset_Cx2_reserviert), 3=Cx3_Fehler (CM_ACT403_Reset_Cx3_Fehler)}, range raw 0..3, transfer-property=PENDING, to Klima(timeout 3.5 s)  # Anzeige eines aufgetretenen Reset seit dem letzten ¿Clear Reset"
            signal ACT403_Spulenbestromung_XIX_ACTs_403_Status_XIX_Klima_LIN5: start 16, 2 bit, little-endian, data-type-policy=OVERRIDE, i-signal-type=PRIMITIVE, init-value=0, base-type=BT_ACT403_Spulenbestromung, invalid-value=Invalid_ACT403_Spulenbestromung_XIX_ACTs_403_Status_XIX_Klima_LIN5:3, compu {0=Cx0_Motorspulen_unbestromt (CM_ACT403_Spulenbestromung_Cx0_Motorspulen_unbestromt), 1=Cx1_Motorspulen_bestromt (CM_ACT403_Spulenbestromung_Cx1_Motorspulen_bestromt), 2=Cx2_reserviert (CM_ACT403_Spulenbestromung_Cx2_reserviert), 3=Cx3_Fehler (CM_ACT403_Spulenbestromung_Cx3_Fehler)}, range raw 0..3, transfer-property=PENDING, to Klima(timeout 3.5 s)  # Spulenbestromung im Haltezustand des Aktuators
            signal ACT403_Positionsvorgabe_Status_XIX_ACTs_403_Status_XIX_Klima_LIN5: start 18, 2 bit, little-endian, data-type-policy=OVERRIDE, i-signal-type=PRIMITIVE, init-value=0, base-type=BT_ACT403_Positionsvorgabe_Status, invalid-value=Invalid_ACT403_Positionsvorgabe_Status_XIX_ACTs_403_Status_XIX_Klima_LIN5:3, compu {0=Cx0_Soll_Position_gueltig (CM_ACT403_Positionsvorgabe_Status_Cx0_Soll_Position_gueltig), 1=Cx1_Start_Position_gueltig (CM_ACT403_Positionsvorgabe_Status_Cx1_Start_Position_gueltig), 2=Cx2_keine_Positionsvorgabe_gueltig (CM_ACT403_Positionsvorgabe_Status_Cx2_keine_Positionsvorgabe_gueltig), 3=Cx3_Fehler (CM_ACT403_Positionsvorgabe_Status_Cx3_Fehler)}, range raw 0..3, transfer-property=PENDING, to Klima(timeout 3.5 s)  # Position des Aktuators
            signal ACT403_Geschwindigkeitsstatus_XIX_ACTs_403_Status_XIX_Klima_LIN5: start 20, 4 bit, little-endian, data-type-policy=OVERRIDE, i-signal-type=PRIMITIVE, init-value=0, base-type=BT_ACT403_Geschwindigkeitsstatus, invalid-value=Invalid_ACT403_Geschwindigkeitsstatus_XIX_ACTs_403_Status_XIX_Klima_LIN5:15, compu {0=Cx0_Motor_steht (CM_ACT403_Geschwindigkeitsstatus_Cx0_Motor_steht), 1=Cx1_Geschwindigkeitsstufe_1 (CM_ACT403_Geschwindigkeitsstatus_Cx1_Geschwindigkeitsstufe_1), 2=Cx2_Geschwindigkeitsstufe_2 (CM_ACT403_Geschwindigkeitsstatus_Cx2_Geschwindigkeitsstufe_2), 3=Cx3_Geschwindigkeitsstufe_3 (CM_ACT403_Geschwindigkeitsstatus_Cx3_Geschwindigkeitsstufe_3), 4=Cx4_Geschwindigkeitsstufe_4 (CM_ACT403_Geschwindigkeitsstatus_Cx4_Geschwindigkeitsstufe_4), 5=Cx5_Autospeed (CM_ACT403_Geschwindigkeitsstatus_Cx5_Autospeed), 15=Cxf_Fehler (CM_ACT403_Geschwindigkeitsstatus_Cxf_Fehler)}, range raw 0..15, transfer-property=PENDING, to Klima(timeout 3.5 s)  # Geschwindigkeitsstufe mit der die aktuelle Verfahrbewegung durchgeführt wird
            signal ACT403_Ist_Position_Aktuator_XIX_ACTs_403_Status_XIX_Klima_LIN5: start 24, 16 bit, little-endian, data-type-policy=OVERRIDE, i-signal-type=PRIMITIVE, init-value=32767, base-type=BT_ACT403_Ist_Position_Aktuator, invalid-value=Invalid_ACT403_Ist_Position_Aktuator_XIX_ACTs_403_Status_XIX_Klima_LIN5:65535, compu {phys=raw for raw 0..65534, 32767=Cx7fff_Init (CM_ACT403_Ist_Position_Aktuator_Cx7fff_Init), 65535=Cxffff_Fehler (CM_ACT403_Ist_Position_Aktuator_Cxffff_Fehler); unit Unit_None}, range phys 0..65534 Unit_None, raw 0..65535, unit=Unit_None, transfer-property=PENDING, to Klima(timeout 3.5 s)  # IST-Position des Aktuators
            signal ACT403_Verfahrrichtung_XIX_ACTs_403_Status_XIX_Klima_LIN5: start 40, 2 bit, little-endian, data-type-policy=OVERRIDE, i-signal-type=PRIMITIVE, init-value=2, base-type=BT_ACT403_Verfahrrichtung, invalid-value=Invalid_ACT403_Verfahrrichtung_XIX_ACTs_403_Status_XIX_Klima_LIN5:3, compu {0=Cx0_Richtung_kl_Schrittpositionen (CM_ACT403_Verfahrrichtung_Cx0_Richtung_kl_Schrittpositionen), 1=Cx1_Richtung_gr_Schrittpositionen (CM_ACT403_Verfahrrichtung_Cx1_Richtung_gr_Schrittpositionen), 2=Cx2_Init (CM_ACT403_Verfahrrichtung_Cx2_Init), 3=Cx3_Fehler (CM_ACT403_Verfahrrichtung_Cx3_Fehler)}, range raw 0..3, transfer-property=PENDING, to Klima(timeout 3.5 s)  # Verfahrrichtung der aktuellen oder zuletzt stattgefundenen Bewegung des Aktuators
            signal ACT403_Selbsthaltemoment_XIX_ACTs_403_Status_XIX_Klima_LIN5: start 42, 2 bit, little-endian, data-type-policy=OVERRIDE, i-signal-type=PRIMITIVE, init-value=0, base-type=BT_ACT403_Selbsthaltemoment, invalid-value=Invalid_ACT403_Selbsthaltemoment_XIX_ACTs_403_Status_XIX_Klima_LIN5:3, compu {0=Cx0_ohne_Selbsthaltemoment (CM_ACT403_Selbsthaltemoment_Cx0_ohne_Selbsthaltemoment), 1=Cx1_mit_Selbsthaltemoment (CM_ACT403_Selbsthaltemoment_Cx1_mit_Selbsthaltemoment), 2=Cx2_reserviert (CM_ACT403_Selbsthaltemoment_Cx2_reserviert), 3=Cx3_Fehler (CM_ACT403_Selbsthaltemoment_Cx3_Fehler)}, range raw 0..3, transfer-property=PENDING, to Klima(timeout 3.5 s)  # Das Signal gibt an ob ein selbsthemmendes Getriebe verbaut ist oder die SHB eingeschaltet ist
            signal ACT403_Sonderfunktionen_XIX_ACTs_403_Status_XIX_Klima_LIN5: start 44, 2 bit, little-endian, data-type-policy=OVERRIDE, i-signal-type=PRIMITIVE, init-value=0, base-type=BT_ACT403_Sonderfunktionen, invalid-value=Invalid_ACT403_Sonderfunktionen_XIX_ACTs_403_Status_XIX_Klima_LIN5:3, compu {0=Cx0_Keine_Sonderfunktion_aktiv (CM_ACT403_Sonderfunktionen_Cx0_Keine_Sonderfunktion_aktiv), 1=Cx1_Sonderfunktion1_aktiv (CM_ACT403_Sonderfunktionen_Cx1_Sonderfunktion1_aktiv), 2=Cx2_Sonderfunktion2_aktiv (CM_ACT403_Sonderfunktionen_Cx2_Sonderfunktion2_aktiv), 3=Cx3_Fehler (CM_ACT403_Sonderfunktionen_Cx3_Fehler)}, range raw 0..3, transfer-property=PENDING, to Klima(timeout 3.5 s)  # Funktionen des Aktuators
            signal ACT403_Variante_XIX_ACTs_403_Status_XIX_Klima_LIN5: start 46, 2 bit, little-endian, data-type-policy=OVERRIDE, i-signal-type=PRIMITIVE, init-value=0, base-type=BT_ACT403_Variante, compu {0=Cx0_Variante_1 (CM_ACT403_Variante_Cx0_Variante_1), 1=Cx1_Variante_2 (CM_ACT403_Variante_Cx1_Variante_2), 2=Cx2_Variante_3 (CM_ACT403_Variante_Cx2_Variante_3), 3=Cx3_Fehler_oder_nicht_umgesetzt (CM_ACT403_Variante_Cx3_Fehler_oder_nicht_umgesetzt)}, range raw 0..3, transfer-property=PENDING, to Klima(timeout 3.5 s)  # Das Signal gibt an welche Variante des Stellmotors verbaut ist
            signal ACT403_Adresse_Aktuator_XIX_ACTs_403_Status_XIX_Klima_LIN5: start 48, 8 bit, little-endian, data-type-policy=OVERRIDE, i-signal-type=PRIMITIVE, init-value=255, base-type=BT_ACT403_Adresse_Aktuator, compu {255=Cxff_Init (CM_ACT403_Adresse_Aktuator_Cxff_Init)}, range raw 255, transfer-property=PENDING, to Klima(timeout 3.5 s)  # Adresse Aktuator
            signal ACT403_Notlauffreigabe_XIX_ACTs_403_Status_XIX_Klima_LIN5: start 56, 2 bit, little-endian, data-type-policy=OVERRIDE, i-signal-type=PRIMITIVE, init-value=0, base-type=BT_ACT403_Notlauffreigabe, invalid-value=Invalid_ACT403_Notlauffreigabe_XIX_ACTs_403_Status_XIX_Klima_LIN5:3, compu {0=Cx0_Notlauf_aus (CM_ACT403_Notlauffreigabe_Cx0_Notlauf_aus), 1=Cx1_Notlauf_ein (CM_ACT403_Notlauffreigabe_Cx1_Notlauf_ein), 2=Cx2_reserviert (CM_ACT403_Notlauffreigabe_Cx2_reserviert), 3=Cx3_Fehler (CM_ACT403_Notlauffreigabe_Cx3_Fehler)}, range raw 0..3, transfer-property=PENDING, to Klima(timeout 3.5 s)  # Freigabe der Notlauffunktion des Aktuators
            signal ACT403_Notlaufposition_XIX_ACTs_403_Status_XIX_Klima_LIN5: start 58, 2 bit, little-endian, data-type-policy=OVERRIDE, i-signal-type=PRIMITIVE, init-value=0, base-type=BT_ACT403_Notlaufposition, invalid-value=Invalid_ACT403_Notlaufposition_XIX_ACTs_403_Status_XIX_Klima_LIN5:3, compu {0=Cx0_unterer_Anschlag (CM_ACT403_Notlaufposition_Cx0_unterer_Anschlag), 1=Cx1_oberer_Anschlag (CM_ACT403_Notlaufposition_Cx1_oberer_Anschlag), 2=Cx2_reserviert (CM_ACT403_Notlaufposition_Cx2_reserviert), 3=Cx3_Fehler (CM_ACT403_Notlaufposition_Cx3_Fehler)}, range raw 0..3, transfer-property=PENDING, to Klima(timeout 3.5 s)  # Positionsvorgabe des Aktuators
            signal ACT403_Drehrichtung_XIX_ACTs_403_Status_XIX_Klima_LIN5: start 60, 2 bit, little-endian, data-type-policy=OVERRIDE, i-signal-type=PRIMITIVE, init-value=0, base-type=BT_ACT403_Drehrichtung, invalid-value=Invalid_ACT403_Drehrichtung_XIX_ACTs_403_Status_XIX_Klima_LIN5:3, compu {0=Cx0_Bewegung_in_Richtung_CW (CM_ACT403_Drehrichtung_Cx0_Bewegung_in_Richtung_CW), 1=Cx1_Bewegung_in_Richtung_CCW (CM_ACT403_Drehrichtung_Cx1_Bewegung_in_Richtung_CCW), 2=Cx2_reserviert (CM_ACT403_Drehrichtung_Cx2_reserviert), 3=Cx3_Fehler (CM_ACT403_Drehrichtung_Cx3_Fehler)}, range raw 0..3, transfer-property=PENDING, to Klima(timeout 3.5 s)  # Drehrichtung des Aktuators
            signal ACT403_Stopmodus_XIX_ACTs_403_Status_XIX_Klima_LIN5: start 62, 2 bit, little-endian, data-type-policy=OVERRIDE, i-signal-type=PRIMITIVE, init-value=0, base-type=BT_ACT403_Stopmodus, invalid-value=Invalid_ACT403_Stopmodus_XIX_ACTs_403_Status_XIX_Klima_LIN5:3, compu {0=Cx0_Normal_Mode (CM_ACT403_Stopmodus_Cx0_Normal_Mode), 1=Cx1_Stop_Mode (CM_ACT403_Stopmodus_Cx1_Stop_Mode), 2=Cx2_reserviert (CM_ACT403_Stopmodus_Cx2_reserviert), 3=Cx3_Fehler (CM_ACT403_Stopmodus_Cx3_Fehler)}, range raw 0..3, transfer-property=PENDING, to Klima(timeout 3.5 s)  # Modus des Aktuators
        frame ACTs_404_Status_XIX_Klima_LIN5: id 0x1B, to Klima, frame-length=8, lin-checksum=ENHANCED
          pdu ACTs_404_Status_XIX_Klima_LIN5: length=8, unused-bit-pattern=0
            signal ACT404_ResponseError_XIX_ACTs_404_Status_XIX_Klima_LIN5: start 0, 1 bit, little-endian, data-type-policy=OVERRIDE, i-signal-type=PRIMITIVE, init-value=0, base-type=BT_ACT404_ResponseError, invalid-value=Invalid_ACT404_ResponseError_XIX_ACTs_404_Status_XIX_Klima_LIN5:1, compu {0=Cx0_normal (CM_ACT404_ResponseError_Cx0_normal), 1=Cx1_Fehler (CM_ACT404_ResponseError_Cx1_Fehler)}, range raw 0..1, transfer-property=PENDING, to Klima(timeout 3.5 s)  # siehe LIN2.0-Specification (Darf nicht über ein Fehlergueltigkeitsbit abgesichtert werden!)
            signal ACT404_Uebertemperatur_XIX_ACTs_404_Status_XIX_Klima_LIN5: start 2, 2 bit, little-endian, data-type-policy=OVERRIDE, i-signal-type=PRIMITIVE, init-value=0, base-type=BT_ACT404_Uebertemperatur, invalid-value=Invalid_ACT404_Uebertemperatur_XIX_ACTs_404_Status_XIX_Klima_LIN5:3, compu {0=Cx0_keine_Uebertemperatur (CM_ACT404_Uebertemperatur_Cx0_keine_Uebertemperatur), 1=Cx1_Uebertemperatur (CM_ACT404_Uebertemperatur_Cx1_Uebertemperatur), 2=Cx2_reserviert (CM_ACT404_Uebertemperatur_Cx2_reserviert), 3=Cx3_Fehler (CM_ACT404_Uebertemperatur_Cx3_Fehler)}, range raw 0..3, transfer-property=PENDING, to Klima(timeout 3.5 s)  # Anzeige einer Übertemperatur im Stellmotoren-ASIC
            signal ACT404_Elektr_Defekt_XIX_ACTs_404_Status_XIX_Klima_LIN5: start 4, 2 bit, little-endian, data-type-policy=OVERRIDE, i-signal-type=PRIMITIVE, init-value=0, base-type=BT_ACT404_Elektr_Defekt, invalid-value=Invalid_ACT404_Elektr_Defekt_XIX_ACTs_404_Status_XIX_Klima_LIN5:3, compu {0=Cx0_kein_Fehler (CM_ACT404_Elektr_Defekt_Cx0_kein_Fehler), 1=Cx1_Elektrischer_Fehler_vorhanden (CM_ACT404_Elektr_Defekt_Cx1_Elektrischer_Fehler_vorhanden), 2=Cx2_Permanent_elekt_Fehler_vorhanden (CM_ACT404_Elektr_Defekt_Cx2_Permanent_elekt_Fehler_vorhanden), 3=Cx3_Fehler (CM_ACT404_Elektr_Defekt_Cx3_Fehler)}, range raw 0..3, transfer-property=PENDING, to Klima(timeout 3.5 s)  # Anzeige für einen elektrischen Fehler oder einen permanent el. Fehler im Stellmotor
            signal ACT404_Versorgungsspannung_XIX_ACTs_404_Status_XIX_Klima_LIN5: start 6, 2 bit, little-endian, data-type-policy=OVERRIDE, i-signal-type=PRIMITIVE, init-value=0, base-type=BT_ACT404_Versorgungsspannung, invalid-value=Invalid_ACT404_Versorgungsspannung_XIX_ACTs_404_Status_XIX_Klima_LIN5:3, compu {0=Cx0_Spannung_im_zulaessigen_Bereich (CM_ACT404_Versorgungsspannung_Cx0_Spannung_im_zulaessigen_Bereich), 1=Cx1_Unterspannung (CM_ACT404_Versorgungsspannung_Cx1_Unterspannung), 2=Cx2_Ueberspanung (CM_ACT404_Versorgungsspannung_Cx2_Ueberspanung), 3=Cx3_Fehler (CM_ACT404_Versorgungsspannung_Cx3_Fehler)}, range raw 0..3, transfer-property=PENDING, to Klima(timeout 3.5 s)  # Versorgungsspannung des Aktuators
            signal ACT404_Notlauf_aufgetreten_XIX_ACTs_404_Status_XIX_Klima_LIN5: start 8, 2 bit, little-endian, data-type-policy=OVERRIDE, i-signal-type=PRIMITIVE, init-value=0, base-type=BT_ACT404_Notlauf_aufgetreten, invalid-value=Invalid_ACT404_Notlauf_aufgetreten_XIX_ACTs_404_Status_XIX_Klima_LIN5:3, compu {0=Cx0_kein_Notlauf_aufgetreten (CM_ACT404_Notlauf_aufgetreten_Cx0_kein_Notlauf_aufgetreten), 1=Cx1_Notlauf_aufgetreten (CM_ACT404_Notlauf_aufgetreten_Cx1_Notlauf_aufgetreten), 2=Cx2_reserviert (CM_ACT404_Notlauf_aufgetreten_Cx2_reserviert), 3=Cx3_Fehler (CM_ACT404_Notlauf_aufgetreten_Cx3_Fehler)}, range raw 0..3, transfer-property=PENDING, to Klima(timeout 3.5 s)  # Anzeige eines aufgetretenen Notlaufs seit dem letzten Reset oder "Clear Notlauf aufgetreten"
            signal ACT404_Freigabe_Blockiererkennung_XIX_ACTs_404_Status_XIX_Klima_LIN5: start 10, 2 bit, little-endian, data-type-policy=OVERRIDE, i-signal-type=PRIMITIVE, init-value=0, base-type=BT_ACT404_Freigabe_Blockiererkennung, invalid-value=Invalid_ACT404_Freigabe_Blockiererkennung_XIX_ACTs_404_Status_XIX_Klima_LIN5:3, compu {0=Cx0_Blockiererkennung_aus (CM_ACT404_Freigabe_Blockiererkennung_Cx0_Blockiererkennung_aus), 1=Cx1_Blockiererkennung_ein (CM_ACT404_Freigabe_Blockiererkennung_Cx1_Blockiererkennung_ein), 2=Cx2_reserviert (CM_ACT404_Freigabe_Blockiererkennung_Cx2_reserviert), 3=Cx3_Fehler (CM_ACT404_Freigabe_Blockiererkennung_Cx3_Fehler)}, range raw 0..3, transfer-property=PENDING, to Klima(timeout 3.5 s)  # Aktivierung der Blockiererkennung im Aktuator
            signal ACT404_Blockierung_aufgetreten_XIX_ACTs_404_Status_XIX_Klima_LIN5: start 12, 2 bit, little-endian, data-type-policy=OVERRIDE, i-signal-type=PRIMITIVE, init-value=0, base-type=BT_ACT404_Blockierung_aufgetreten, invalid-value=Invalid_ACT404_Blockierung_aufgetreten_XIX_ACTs_404_Status_XIX_Klima_LIN5:3, compu {0=Cx0_keine_Blockierung (CM_ACT404_Blockierung_aufgetreten_Cx0_keine_Blockierung), 1=Cx1_Blockierung_erkannt (CM_ACT404_Blockierung_aufgetreten_Cx1_Blockierung_erkannt), 2=Cx2_reserviert (CM_ACT404_Blockierung_aufgetreten_Cx2_reserviert), 3=Cx3_Fehler (CM_ACT404_Blockierung_aufgetreten_Cx3_Fehler)}, range raw 0..3, transfer-property=PENDING, to Klima(timeout 3.5 s)  # Anzeige einer aufgetretenen Blockierung seit dem letzten Reset oder "Clear Blockierung aufgetreten"
            signal ACT404_Reset_XIX_ACTs_404_Status_XIX_Klima_LIN5: start 14, 2 bit, little-endian, data-type-policy=OVERRIDE, i-signal-type=PRIMITIVE, init-value=0, base-type=BT_ACT404_Reset, invalid-value=Invalid_ACT404_Reset_XIX_ACTs_404_Status_XIX_Klima_LIN5:3, compu {0=Cx0_kein_Reset (CM_ACT404_Reset_Cx0_kein_Reset), 1=Cx1_Reset_durchgefuehrt (CM_ACT404_Reset_Cx1_Reset_durchgefuehrt), 2=Cx2_reserviert (CM_ACT404_Reset_Cx2_reserviert), 3=Cx3_Fehler (CM_ACT404_Reset_Cx3_Fehler)}, range raw 0..3, transfer-property=PENDING, to Klima(timeout 3.5 s)  # Anzeige eines aufgetretenen Reset seit dem letzten ¿Clear Reset"
            signal ACT404_Spulenbestromung_XIX_ACTs_404_Status_XIX_Klima_LIN5: start 16, 2 bit, little-endian, data-type-policy=OVERRIDE, i-signal-type=PRIMITIVE, init-value=0, base-type=BT_ACT404_Spulenbestromung, invalid-value=Invalid_ACT404_Spulenbestromung_XIX_ACTs_404_Status_XIX_Klima_LIN5:3, compu {0=Cx0_Motorspulen_unbestromt (CM_ACT404_Spulenbestromung_Cx0_Motorspulen_unbestromt), 1=Cx1_Motorspulen_bestromt (CM_ACT404_Spulenbestromung_Cx1_Motorspulen_bestromt), 2=Cx2_reserviert (CM_ACT404_Spulenbestromung_Cx2_reserviert), 3=Cx3_Fehler (CM_ACT404_Spulenbestromung_Cx3_Fehler)}, range raw 0..3, transfer-property=PENDING, to Klima(timeout 3.5 s)  # Spulenbestromung im Haltezustand des Aktuators
            signal ACT404_Positionsvorgabe_Status_XIX_ACTs_404_Status_XIX_Klima_LIN5: start 18, 2 bit, little-endian, data-type-policy=OVERRIDE, i-signal-type=PRIMITIVE, init-value=0, base-type=BT_ACT404_Positionsvorgabe_Status, invalid-value=Invalid_ACT404_Positionsvorgabe_Status_XIX_ACTs_404_Status_XIX_Klima_LIN5:3, compu {0=Cx0_Soll_Position_gueltig (CM_ACT404_Positionsvorgabe_Status_Cx0_Soll_Position_gueltig), 1=Cx1_Start_Position_gueltig (CM_ACT404_Positionsvorgabe_Status_Cx1_Start_Position_gueltig), 2=Cx2_keine_Positionsvorgabe_gueltig (CM_ACT404_Positionsvorgabe_Status_Cx2_keine_Positionsvorgabe_gueltig), 3=Cx3_Fehler (CM_ACT404_Positionsvorgabe_Status_Cx3_Fehler)}, range raw 0..3, transfer-property=PENDING, to Klima(timeout 3.5 s)  # Position des Aktuators
            signal ACT404_Geschwindigkeitsstatus_XIX_ACTs_404_Status_XIX_Klima_LIN5: start 20, 4 bit, little-endian, data-type-policy=OVERRIDE, i-signal-type=PRIMITIVE, init-value=0, base-type=BT_ACT404_Geschwindigkeitsstatus, invalid-value=Invalid_ACT404_Geschwindigkeitsstatus_XIX_ACTs_404_Status_XIX_Klima_LIN5:15, compu {0=Cx0_Motor_steht (CM_ACT404_Geschwindigkeitsstatus_Cx0_Motor_steht), 1=Cx1_Geschwindigkeitsstufe_1 (CM_ACT404_Geschwindigkeitsstatus_Cx1_Geschwindigkeitsstufe_1), 2=Cx2_Geschwindigkeitsstufe_2 (CM_ACT404_Geschwindigkeitsstatus_Cx2_Geschwindigkeitsstufe_2), 3=Cx3_Geschwindigkeitsstufe_3 (CM_ACT404_Geschwindigkeitsstatus_Cx3_Geschwindigkeitsstufe_3), 4=Cx4_Geschwindigkeitsstufe_4 (CM_ACT404_Geschwindigkeitsstatus_Cx4_Geschwindigkeitsstufe_4), 5=Cx5_Autospeed (CM_ACT404_Geschwindigkeitsstatus_Cx5_Autospeed), 15=Cxf_Fehler (CM_ACT404_Geschwindigkeitsstatus_Cxf_Fehler)}, range raw 0..15, transfer-property=PENDING, to Klima(timeout 3.5 s)  # Geschwindigkeitsstufe mit der die aktuelle Verfahrbewegung durchgeführt wird
            signal ACT404_Ist_Position_Aktuator_XIX_ACTs_404_Status_XIX_Klima_LIN5: start 24, 16 bit, little-endian, data-type-policy=OVERRIDE, i-signal-type=PRIMITIVE, init-value=32767, base-type=BT_ACT404_Ist_Position_Aktuator, invalid-value=Invalid_ACT404_Ist_Position_Aktuator_XIX_ACTs_404_Status_XIX_Klima_LIN5:65535, compu {phys=raw for raw 0..65534, 32767=Cx7fff_Init (CM_ACT404_Ist_Position_Aktuator_Cx7fff_Init), 65535=Cxffff_Fehler (CM_ACT404_Ist_Position_Aktuator_Cxffff_Fehler); unit Unit_None}, range phys 0..65534 Unit_None, raw 0..65535, unit=Unit_None, transfer-property=PENDING, to Klima(timeout 3.5 s)  # IST-Position des Aktuators
            signal ACT404_Verfahrrichtung_XIX_ACTs_404_Status_XIX_Klima_LIN5: start 40, 2 bit, little-endian, data-type-policy=OVERRIDE, i-signal-type=PRIMITIVE, init-value=2, base-type=BT_ACT404_Verfahrrichtung, invalid-value=Invalid_ACT404_Verfahrrichtung_XIX_ACTs_404_Status_XIX_Klima_LIN5:3, compu {0=Cx0_Richtung_kl_Schrittpositionen (CM_ACT404_Verfahrrichtung_Cx0_Richtung_kl_Schrittpositionen), 1=Cx1_Richtung_gr_Schrittpositionen (CM_ACT404_Verfahrrichtung_Cx1_Richtung_gr_Schrittpositionen), 2=Cx2_Init (CM_ACT404_Verfahrrichtung_Cx2_Init), 3=Cx3_Fehler (CM_ACT404_Verfahrrichtung_Cx3_Fehler)}, range raw 0..3, transfer-property=PENDING, to Klima(timeout 3.5 s)  # Verfahrrichtung der aktuellen oder zuletzt stattgefundenen Bewegung des Aktuators
            signal ACT404_Selbsthaltemoment_XIX_ACTs_404_Status_XIX_Klima_LIN5: start 42, 2 bit, little-endian, data-type-policy=OVERRIDE, i-signal-type=PRIMITIVE, init-value=0, base-type=BT_ACT404_Selbsthaltemoment, invalid-value=Invalid_ACT404_Selbsthaltemoment_XIX_ACTs_404_Status_XIX_Klima_LIN5:3, compu {0=Cx0_ohne_Selbsthaltemoment (CM_ACT404_Selbsthaltemoment_Cx0_ohne_Selbsthaltemoment), 1=Cx1_mit_Selbsthaltemoment (CM_ACT404_Selbsthaltemoment_Cx1_mit_Selbsthaltemoment), 2=Cx2_reserviert (CM_ACT404_Selbsthaltemoment_Cx2_reserviert), 3=Cx3_Fehler (CM_ACT404_Selbsthaltemoment_Cx3_Fehler)}, range raw 0..3, transfer-property=PENDING, to Klima(timeout 3.5 s)  # Das Signal gibt an ob ein selbsthemmendes Getriebe verbaut ist oder die SHB eingeschaltet ist
            signal ACT404_Sonderfunktionen_XIX_ACTs_404_Status_XIX_Klima_LIN5: start 44, 2 bit, little-endian, data-type-policy=OVERRIDE, i-signal-type=PRIMITIVE, init-value=0, base-type=BT_ACT404_Sonderfunktionen, invalid-value=Invalid_ACT404_Sonderfunktionen_XIX_ACTs_404_Status_XIX_Klima_LIN5:3, compu {0=Cx0_Keine_Sonderfunktion_aktiv (CM_ACT404_Sonderfunktionen_Cx0_Keine_Sonderfunktion_aktiv), 1=Cx1_Sonderfunktion1_aktiv (CM_ACT404_Sonderfunktionen_Cx1_Sonderfunktion1_aktiv), 2=Cx2_Sonderfunktion2_aktiv (CM_ACT404_Sonderfunktionen_Cx2_Sonderfunktion2_aktiv), 3=Cx3_Fehler (CM_ACT404_Sonderfunktionen_Cx3_Fehler)}, range raw 0..3, transfer-property=PENDING, to Klima(timeout 3.5 s)  # Funktionen des Aktuators
            signal ACT404_Variante_XIX_ACTs_404_Status_XIX_Klima_LIN5: start 46, 2 bit, little-endian, data-type-policy=OVERRIDE, i-signal-type=PRIMITIVE, init-value=0, base-type=BT_ACT404_Variante, compu {0=Cx0_Variante_1 (CM_ACT404_Variante_Cx0_Variante_1), 1=Cx1_Variante_2 (CM_ACT404_Variante_Cx1_Variante_2), 2=Cx2_Variante_3 (CM_ACT404_Variante_Cx2_Variante_3), 3=Cx3_Fehler_oder_nicht_umgesetzt (CM_ACT404_Variante_Cx3_Fehler_oder_nicht_umgesetzt)}, range raw 0..3, transfer-property=PENDING, to Klima(timeout 3.5 s)  # Das Signal gibt an welche Variante des Stellmotors verbaut ist
            signal ACT404_Adresse_Aktuator_XIX_ACTs_404_Status_XIX_Klima_LIN5: start 48, 8 bit, little-endian, data-type-policy=OVERRIDE, i-signal-type=PRIMITIVE, init-value=255, base-type=BT_ACT404_Adresse_Aktuator, compu {255=Cxff_Init (CM_ACT404_Adresse_Aktuator_Cxff_Init)}, range raw 255, transfer-property=PENDING, to Klima(timeout 3.5 s)  # Adresse Aktuator
            signal ACT404_Notlauffreigabe_XIX_ACTs_404_Status_XIX_Klima_LIN5: start 56, 2 bit, little-endian, data-type-policy=OVERRIDE, i-signal-type=PRIMITIVE, init-value=0, base-type=BT_ACT404_Notlauffreigabe, invalid-value=Invalid_ACT404_Notlauffreigabe_XIX_ACTs_404_Status_XIX_Klima_LIN5:3, compu {0=Cx0_Notlauf_aus (CM_ACT404_Notlauffreigabe_Cx0_Notlauf_aus), 1=Cx1_Notlauf_ein (CM_ACT404_Notlauffreigabe_Cx1_Notlauf_ein), 2=Cx2_reserviert (CM_ACT404_Notlauffreigabe_Cx2_reserviert), 3=Cx3_Fehler (CM_ACT404_Notlauffreigabe_Cx3_Fehler)}, range raw 0..3, transfer-property=PENDING, to Klima(timeout 3.5 s)  # Freigabe der Notlauffunktion des Aktuators
            signal ACT404_Notlaufposition_XIX_ACTs_404_Status_XIX_Klima_LIN5: start 58, 2 bit, little-endian, data-type-policy=OVERRIDE, i-signal-type=PRIMITIVE, init-value=0, base-type=BT_ACT404_Notlaufposition, invalid-value=Invalid_ACT404_Notlaufposition_XIX_ACTs_404_Status_XIX_Klima_LIN5:3, compu {0=Cx0_unterer_Anschlag (CM_ACT404_Notlaufposition_Cx0_unterer_Anschlag), 1=Cx1_oberer_Anschlag (CM_ACT404_Notlaufposition_Cx1_oberer_Anschlag), 2=Cx2_reserviert (CM_ACT404_Notlaufposition_Cx2_reserviert), 3=Cx3_Fehler (CM_ACT404_Notlaufposition_Cx3_Fehler)}, range raw 0..3, transfer-property=PENDING, to Klima(timeout 3.5 s)  # Positionsvorgabe des Aktuators
            signal ACT404_Drehrichtung_XIX_ACTs_404_Status_XIX_Klima_LIN5: start 60, 2 bit, little-endian, data-type-policy=OVERRIDE, i-signal-type=PRIMITIVE, init-value=0, base-type=BT_ACT404_Drehrichtung, invalid-value=Invalid_ACT404_Drehrichtung_XIX_ACTs_404_Status_XIX_Klima_LIN5:3, compu {0=Cx0_Bewegung_in_Richtung_CW (CM_ACT404_Drehrichtung_Cx0_Bewegung_in_Richtung_CW), 1=Cx1_Bewegung_in_Richtung_CCW (CM_ACT404_Drehrichtung_Cx1_Bewegung_in_Richtung_CCW), 2=Cx2_reserviert (CM_ACT404_Drehrichtung_Cx2_reserviert), 3=Cx3_Fehler (CM_ACT404_Drehrichtung_Cx3_Fehler)}, range raw 0..3, transfer-property=PENDING, to Klima(timeout 3.5 s)  # Drehrichtung des Aktuators
            signal ACT404_Stopmodus_XIX_ACTs_404_Status_XIX_Klima_LIN5: start 62, 2 bit, little-endian, data-type-policy=OVERRIDE, i-signal-type=PRIMITIVE, init-value=0, base-type=BT_ACT404_Stopmodus, invalid-value=Invalid_ACT404_Stopmodus_XIX_ACTs_404_Status_XIX_Klima_LIN5:3, compu {0=Cx0_Normal_Mode (CM_ACT404_Stopmodus_Cx0_Normal_Mode), 1=Cx1_Stop_Mode (CM_ACT404_Stopmodus_Cx1_Stop_Mode), 2=Cx2_reserviert (CM_ACT404_Stopmodus_Cx2_reserviert), 3=Cx3_Fehler (CM_ACT404_Stopmodus_Cx3_Fehler)}, range raw 0..3, transfer-property=PENDING, to Klima(timeout 3.5 s)  # Modus des Aktuators
        frame ACTs_405_Status_XIX_Klima_LIN5: id 0x20, to Klima, frame-length=8, lin-checksum=ENHANCED
          pdu ACTs_405_Status_XIX_Klima_LIN5: length=8, unused-bit-pattern=0
            signal ACT405_ResponseError_XIX_ACTs_405_Status_XIX_Klima_LIN5: start 0, 1 bit, little-endian, data-type-policy=OVERRIDE, i-signal-type=PRIMITIVE, init-value=0, base-type=BT_ACT405_ResponseError, invalid-value=Invalid_ACT405_ResponseError_XIX_ACTs_405_Status_XIX_Klima_LIN5:1, compu {0=Cx0_normal (CM_ACT405_ResponseError_Cx0_normal), 1=Cx1_Fehler (CM_ACT405_ResponseError_Cx1_Fehler)}, range raw 0..1, transfer-property=PENDING, to Klima(timeout 3.5 s)  # siehe LIN2.0-Specification (Darf nicht über ein Fehlergueltigkeitsbit abgesichtert werden!)
            signal ACT405_Uebertemperatur_XIX_ACTs_405_Status_XIX_Klima_LIN5: start 2, 2 bit, little-endian, data-type-policy=OVERRIDE, i-signal-type=PRIMITIVE, init-value=0, base-type=BT_ACT405_Uebertemperatur, invalid-value=Invalid_ACT405_Uebertemperatur_XIX_ACTs_405_Status_XIX_Klima_LIN5:3, compu {0=Cx0_keine_Uebertemperatur (CM_ACT405_Uebertemperatur_Cx0_keine_Uebertemperatur), 1=Cx1_Uebertemperatur (CM_ACT405_Uebertemperatur_Cx1_Uebertemperatur), 2=Cx2_reserviert (CM_ACT405_Uebertemperatur_Cx2_reserviert), 3=Cx3_Fehler (CM_ACT405_Uebertemperatur_Cx3_Fehler)}, range raw 0..3, transfer-property=PENDING, to Klima(timeout 3.5 s)  # Anzeige einer Übertemperatur im Stellmotoren-ASIC
            signal ACT405_Elektr_Defekt_XIX_ACTs_405_Status_XIX_Klima_LIN5: start 4, 2 bit, little-endian, data-type-policy=OVERRIDE, i-signal-type=PRIMITIVE, init-value=0, base-type=BT_ACT405_Elektr_Defekt, invalid-value=Invalid_ACT405_Elektr_Defekt_XIX_ACTs_405_Status_XIX_Klima_LIN5:3, compu {0=Cx0_kein_Fehler (CM_ACT405_Elektr_Defekt_Cx0_kein_Fehler), 1=Cx1_Elektrischer_Fehler_vorhanden (CM_ACT405_Elektr_Defekt_Cx1_Elektrischer_Fehler_vorhanden), 2=Cx2_Permanent_elekt_Fehler_vorhanden (CM_ACT405_Elektr_Defekt_Cx2_Permanent_elekt_Fehler_vorhanden), 3=Cx3_Fehler (CM_ACT405_Elektr_Defekt_Cx3_Fehler)}, range raw 0..3, transfer-property=PENDING, to Klima(timeout 3.5 s)  # Anzeige für einen elektrischen Fehler oder einen permanent el. Fehler im Stellmotor
            signal ACT405_Versorgungsspannung_XIX_ACTs_405_Status_XIX_Klima_LIN5: start 6, 2 bit, little-endian, data-type-policy=OVERRIDE, i-signal-type=PRIMITIVE, init-value=0, base-type=BT_ACT405_Versorgungsspannung, invalid-value=Invalid_ACT405_Versorgungsspannung_XIX_ACTs_405_Status_XIX_Klima_LIN5:3, compu {0=Cx0_Spannung_im_zulaessigen_Bereich (CM_ACT405_Versorgungsspannung_Cx0_Spannung_im_zulaessigen_Bereich), 1=Cx1_Unterspannung (CM_ACT405_Versorgungsspannung_Cx1_Unterspannung), 2=Cx2_Ueberspanung (CM_ACT405_Versorgungsspannung_Cx2_Ueberspanung), 3=Cx3_Fehler (CM_ACT405_Versorgungsspannung_Cx3_Fehler)}, range raw 0..3, transfer-property=PENDING, to Klima(timeout 3.5 s)  # Versorgungsspannung des Aktuators
            signal ACT405_Notlauf_aufgetreten_XIX_ACTs_405_Status_XIX_Klima_LIN5: start 8, 2 bit, little-endian, data-type-policy=OVERRIDE, i-signal-type=PRIMITIVE, init-value=0, base-type=BT_ACT405_Notlauf_aufgetreten, invalid-value=Invalid_ACT405_Notlauf_aufgetreten_XIX_ACTs_405_Status_XIX_Klima_LIN5:3, compu {0=Cx0_kein_Notlauf_aufgetreten (CM_ACT405_Notlauf_aufgetreten_Cx0_kein_Notlauf_aufgetreten), 1=Cx1_Notlauf_aufgetreten (CM_ACT405_Notlauf_aufgetreten_Cx1_Notlauf_aufgetreten), 2=Cx2_reserviert (CM_ACT405_Notlauf_aufgetreten_Cx2_reserviert), 3=Cx3_Fehler (CM_ACT405_Notlauf_aufgetreten_Cx3_Fehler)}, range raw 0..3, transfer-property=PENDING, to Klima(timeout 3.5 s)  # Anzeige eines aufgetretenen Notlaufs seit dem letzten Reset oder "Clear Notlauf aufgetreten"
            signal ACT405_Freigabe_Blockiererkennung_XIX_ACTs_405_Status_XIX_Klima_LIN5: start 10, 2 bit, little-endian, data-type-policy=OVERRIDE, i-signal-type=PRIMITIVE, init-value=0, base-type=BT_ACT405_Freigabe_Blockiererkennung, invalid-value=Invalid_ACT405_Freigabe_Blockiererkennung_XIX_ACTs_405_Status_XIX_Klima_LIN5:3, compu {0=Cx0_Blockiererkennung_aus (CM_ACT405_Freigabe_Blockiererkennung_Cx0_Blockiererkennung_aus), 1=Cx1_Blockiererkennung_ein (CM_ACT405_Freigabe_Blockiererkennung_Cx1_Blockiererkennung_ein), 2=Cx2_reserviert (CM_ACT405_Freigabe_Blockiererkennung_Cx2_reserviert), 3=Cx3_Fehler (CM_ACT405_Freigabe_Blockiererkennung_Cx3_Fehler)}, range raw 0..3, transfer-property=PENDING, to Klima(timeout 3.5 s)  # Aktivierung der Blockiererkennung im Aktuator
            signal ACT405_Blockierung_aufgetreten_XIX_ACTs_405_Status_XIX_Klima_LIN5: start 12, 2 bit, little-endian, data-type-policy=OVERRIDE, i-signal-type=PRIMITIVE, init-value=0, base-type=BT_ACT405_Blockierung_aufgetreten, invalid-value=Invalid_ACT405_Blockierung_aufgetreten_XIX_ACTs_405_Status_XIX_Klima_LIN5:3, compu {0=Cx0_keine_Blockierung (CM_ACT405_Blockierung_aufgetreten_Cx0_keine_Blockierung), 1=Cx1_Blockierung_erkannt (CM_ACT405_Blockierung_aufgetreten_Cx1_Blockierung_erkannt), 2=Cx2_reserviert (CM_ACT405_Blockierung_aufgetreten_Cx2_reserviert), 3=Cx3_Fehler (CM_ACT405_Blockierung_aufgetreten_Cx3_Fehler)}, range raw 0..3, transfer-property=PENDING, to Klima(timeout 3.5 s)  # Anzeige einer aufgetretenen Blockierung seit dem letzten Reset oder "Clear Blockierung aufgetreten"
            signal ACT405_Reset_XIX_ACTs_405_Status_XIX_Klima_LIN5: start 14, 2 bit, little-endian, data-type-policy=OVERRIDE, i-signal-type=PRIMITIVE, init-value=0, base-type=BT_ACT405_Reset, invalid-value=Invalid_ACT405_Reset_XIX_ACTs_405_Status_XIX_Klima_LIN5:3, compu {0=Cx0_kein_Reset (CM_ACT405_Reset_Cx0_kein_Reset), 1=Cx1_Reset_durchgefuehrt (CM_ACT405_Reset_Cx1_Reset_durchgefuehrt), 2=Cx2_reserviert (CM_ACT405_Reset_Cx2_reserviert), 3=Cx3_Fehler (CM_ACT405_Reset_Cx3_Fehler)}, range raw 0..3, transfer-property=PENDING, to Klima(timeout 3.5 s)  # Anzeige eines aufgetretenen Reset seit dem letzten ¿Clear Reset"
            signal ACT405_Spulenbestromung_XIX_ACTs_405_Status_XIX_Klima_LIN5: start 16, 2 bit, little-endian, data-type-policy=OVERRIDE, i-signal-type=PRIMITIVE, init-value=0, base-type=BT_ACT405_Spulenbestromung, invalid-value=Invalid_ACT405_Spulenbestromung_XIX_ACTs_405_Status_XIX_Klima_LIN5:3, compu {0=Cx0_Motorspulen_unbestromt (CM_ACT405_Spulenbestromung_Cx0_Motorspulen_unbestromt), 1=Cx1_Motorspulen_bestromt (CM_ACT405_Spulenbestromung_Cx1_Motorspulen_bestromt), 2=Cx2_reserviert (CM_ACT405_Spulenbestromung_Cx2_reserviert), 3=Cx3_Fehler (CM_ACT405_Spulenbestromung_Cx3_Fehler)}, range raw 0..3, transfer-property=PENDING, to Klima(timeout 3.5 s)  # Spulenbestromung im Haltezustand des Aktuators
            signal ACT405_Positionsvorgabe_Status_XIX_ACTs_405_Status_XIX_Klima_LIN5: start 18, 2 bit, little-endian, data-type-policy=OVERRIDE, i-signal-type=PRIMITIVE, init-value=0, base-type=BT_ACT405_Positionsvorgabe_Status, invalid-value=Invalid_ACT405_Positionsvorgabe_Status_XIX_ACTs_405_Status_XIX_Klima_LIN5:3, compu {0=Cx0_Soll_Position_gueltig (CM_ACT405_Positionsvorgabe_Status_Cx0_Soll_Position_gueltig), 1=Cx1_Start_Position_gueltig (CM_ACT405_Positionsvorgabe_Status_Cx1_Start_Position_gueltig), 2=Cx2_keine_Positionsvorgabe_gueltig (CM_ACT405_Positionsvorgabe_Status_Cx2_keine_Positionsvorgabe_gueltig), 3=Cx3_Fehler (CM_ACT405_Positionsvorgabe_Status_Cx3_Fehler)}, range raw 0..3, transfer-property=PENDING, to Klima(timeout 3.5 s)  # Position des Aktuators
            signal ACT405_Geschwindigkeitsstatus_XIX_ACTs_405_Status_XIX_Klima_LIN5: start 20, 4 bit, little-endian, data-type-policy=OVERRIDE, i-signal-type=PRIMITIVE, init-value=0, base-type=BT_ACT405_Geschwindigkeitsstatus, invalid-value=Invalid_ACT405_Geschwindigkeitsstatus_XIX_ACTs_405_Status_XIX_Klima_LIN5:15, compu {0=Cx0_Motor_steht (CM_ACT405_Geschwindigkeitsstatus_Cx0_Motor_steht), 1=Cx1_Geschwindigkeitsstufe_1 (CM_ACT405_Geschwindigkeitsstatus_Cx1_Geschwindigkeitsstufe_1), 2=Cx2_Geschwindigkeitsstufe_2 (CM_ACT405_Geschwindigkeitsstatus_Cx2_Geschwindigkeitsstufe_2), 3=Cx3_Geschwindigkeitsstufe_3 (CM_ACT405_Geschwindigkeitsstatus_Cx3_Geschwindigkeitsstufe_3), 4=Cx4_Geschwindigkeitsstufe_4 (CM_ACT405_Geschwindigkeitsstatus_Cx4_Geschwindigkeitsstufe_4), 5=Cx5_Autospeed (CM_ACT405_Geschwindigkeitsstatus_Cx5_Autospeed), 15=Cxf_Fehler (CM_ACT405_Geschwindigkeitsstatus_Cxf_Fehler)}, range raw 0..15, transfer-property=PENDING, to Klima(timeout 3.5 s)  # Geschwindigkeitsstufe mit der die aktuelle Verfahrbewegung durchgeführt wird
            signal ACT405_Ist_Position_Aktuator_XIX_ACTs_405_Status_XIX_Klima_LIN5: start 24, 16 bit, little-endian, data-type-policy=OVERRIDE, i-signal-type=PRIMITIVE, init-value=32767, base-type=BT_ACT405_Ist_Position_Aktuator, invalid-value=Invalid_ACT405_Ist_Position_Aktuator_XIX_ACTs_405_Status_XIX_Klima_LIN5:65535, compu {phys=raw for raw 0..65534, 32767=Cx7fff_Init (CM_ACT405_Ist_Position_Aktuator_Cx7fff_Init), 65535=Cxffff_Fehler (CM_ACT405_Ist_Position_Aktuator_Cxffff_Fehler); unit Unit_None}, range phys 0..65534 Unit_None, raw 0..65535, unit=Unit_None, transfer-property=PENDING, to Klima(timeout 3.5 s)  # IST-Position des Aktuators
            signal ACT405_Verfahrrichtung_XIX_ACTs_405_Status_XIX_Klima_LIN5: start 40, 2 bit, little-endian, data-type-policy=OVERRIDE, i-signal-type=PRIMITIVE, init-value=2, base-type=BT_ACT405_Verfahrrichtung, invalid-value=Invalid_ACT405_Verfahrrichtung_XIX_ACTs_405_Status_XIX_Klima_LIN5:3, compu {0=Cx0_Richtung_kl_Schrittpositionen (CM_ACT405_Verfahrrichtung_Cx0_Richtung_kl_Schrittpositionen), 1=Cx1_Richtung_gr_Schrittpositionen (CM_ACT405_Verfahrrichtung_Cx1_Richtung_gr_Schrittpositionen), 2=Cx2_Init (CM_ACT405_Verfahrrichtung_Cx2_Init), 3=Cx3_Fehler (CM_ACT405_Verfahrrichtung_Cx3_Fehler)}, range raw 0..3, transfer-property=PENDING, to Klima(timeout 3.5 s)  # Verfahrrichtung der aktuellen oder zuletzt stattgefundenen Bewegung des Aktuators
            signal ACT405_Selbsthaltemoment_XIX_ACTs_405_Status_XIX_Klima_LIN5: start 42, 2 bit, little-endian, data-type-policy=OVERRIDE, i-signal-type=PRIMITIVE, init-value=0, base-type=BT_ACT405_Selbsthaltemoment, invalid-value=Invalid_ACT405_Selbsthaltemoment_XIX_ACTs_405_Status_XIX_Klima_LIN5:3, compu {0=Cx0_ohne_Selbsthaltemoment (CM_ACT405_Selbsthaltemoment_Cx0_ohne_Selbsthaltemoment), 1=Cx1_mit_Selbsthaltemoment (CM_ACT405_Selbsthaltemoment_Cx1_mit_Selbsthaltemoment), 2=Cx2_reserviert (CM_ACT405_Selbsthaltemoment_Cx2_reserviert), 3=Cx3_Fehler (CM_ACT405_Selbsthaltemoment_Cx3_Fehler)}, range raw 0..3, transfer-property=PENDING, to Klima(timeout 3.5 s)  # Das Signal gibt an ob ein selbsthemmendes Getriebe verbaut ist oder die SHB eingeschaltet ist
            signal ACT405_Sonderfunktionen_XIX_ACTs_405_Status_XIX_Klima_LIN5: start 44, 2 bit, little-endian, data-type-policy=OVERRIDE, i-signal-type=PRIMITIVE, init-value=0, base-type=BT_ACT405_Sonderfunktionen, invalid-value=Invalid_ACT405_Sonderfunktionen_XIX_ACTs_405_Status_XIX_Klima_LIN5:3, compu {0=Cx0_Keine_Sonderfunktion_aktiv (CM_ACT405_Sonderfunktionen_Cx0_Keine_Sonderfunktion_aktiv), 1=Cx1_Sonderfunktion1_aktiv (CM_ACT405_Sonderfunktionen_Cx1_Sonderfunktion1_aktiv), 2=Cx2_Sonderfunktion2_aktiv (CM_ACT405_Sonderfunktionen_Cx2_Sonderfunktion2_aktiv), 3=Cx3_Fehler (CM_ACT405_Sonderfunktionen_Cx3_Fehler)}, range raw 0..3, transfer-property=PENDING, to Klima(timeout 3.5 s)  # Funktionen des Aktuators
            signal ACT405_Variante_XIX_ACTs_405_Status_XIX_Klima_LIN5: start 46, 2 bit, little-endian, data-type-policy=OVERRIDE, i-signal-type=PRIMITIVE, init-value=0, base-type=BT_ACT405_Variante, compu {0=Cx0_Variante_1 (CM_ACT405_Variante_Cx0_Variante_1), 1=Cx1_Variante_2 (CM_ACT405_Variante_Cx1_Variante_2), 2=Cx2_Variante_3 (CM_ACT405_Variante_Cx2_Variante_3), 3=Cx3_Fehler_oder_nicht_umgesetzt (CM_ACT405_Variante_Cx3_Fehler_oder_nicht_umgesetzt)}, range raw 0..3, transfer-property=PENDING, to Klima(timeout 3.5 s)  # Das Signal gibt an welche Variante des Stellmotors verbaut ist
            signal ACT405_Adresse_Aktuator_XIX_ACTs_405_Status_XIX_Klima_LIN5: start 48, 8 bit, little-endian, data-type-policy=OVERRIDE, i-signal-type=PRIMITIVE, init-value=255, base-type=BT_ACT405_Adresse_Aktuator, compu {255=Cxff_Init (CM_ACT405_Adresse_Aktuator_Cxff_Init)}, range raw 255, transfer-property=PENDING, to Klima(timeout 3.5 s)  # Adresse Aktuator
            signal ACT405_Notlauffreigabe_XIX_ACTs_405_Status_XIX_Klima_LIN5: start 56, 2 bit, little-endian, data-type-policy=OVERRIDE, i-signal-type=PRIMITIVE, init-value=0, base-type=BT_ACT405_Notlauffreigabe, invalid-value=Invalid_ACT405_Notlauffreigabe_XIX_ACTs_405_Status_XIX_Klima_LIN5:3, compu {0=Cx0_Notlauf_aus (CM_ACT405_Notlauffreigabe_Cx0_Notlauf_aus), 1=Cx1_Notlauf_ein (CM_ACT405_Notlauffreigabe_Cx1_Notlauf_ein), 2=Cx2_reserviert (CM_ACT405_Notlauffreigabe_Cx2_reserviert), 3=Cx3_Fehler (CM_ACT405_Notlauffreigabe_Cx3_Fehler)}, range raw 0..3, transfer-property=PENDING, to Klima(timeout 3.5 s)  # Freigabe der Notlauffunktion des Aktuators
            signal ACT405_Notlaufposition_XIX_ACTs_405_Status_XIX_Klima_LIN5: start 58, 2 bit, little-endian, data-type-policy=OVERRIDE, i-signal-type=PRIMITIVE, init-value=0, base-type=BT_ACT405_Notlaufposition, invalid-value=Invalid_ACT405_Notlaufposition_XIX_ACTs_405_Status_XIX_Klima_LIN5:3, compu {0=Cx0_unterer_Anschlag (CM_ACT405_Notlaufposition_Cx0_unterer_Anschlag), 1=Cx1_oberer_Anschlag (CM_ACT405_Notlaufposition_Cx1_oberer_Anschlag), 2=Cx2_reserviert (CM_ACT405_Notlaufposition_Cx2_reserviert), 3=Cx3_Fehler (CM_ACT405_Notlaufposition_Cx3_Fehler)}, range raw 0..3, transfer-property=PENDING, to Klima(timeout 3.5 s)  # Positionsvorgabe des Aktuators
            signal ACT405_Drehrichtung_XIX_ACTs_405_Status_XIX_Klima_LIN5: start 60, 2 bit, little-endian, data-type-policy=OVERRIDE, i-signal-type=PRIMITIVE, init-value=0, base-type=BT_ACT405_Drehrichtung, invalid-value=Invalid_ACT405_Drehrichtung_XIX_ACTs_405_Status_XIX_Klima_LIN5:3, compu {0=Cx0_Bewegung_in_Richtung_CW (CM_ACT405_Drehrichtung_Cx0_Bewegung_in_Richtung_CW), 1=Cx1_Bewegung_in_Richtung_CCW (CM_ACT405_Drehrichtung_Cx1_Bewegung_in_Richtung_CCW), 2=Cx2_reserviert (CM_ACT405_Drehrichtung_Cx2_reserviert), 3=Cx3_Fehler (CM_ACT405_Drehrichtung_Cx3_Fehler)}, range raw 0..3, transfer-property=PENDING, to Klima(timeout 3.5 s)  # Drehrichtung des Aktuators
            signal ACT405_Stopmodus_XIX_ACTs_405_Status_XIX_Klima_LIN5: start 62, 2 bit, little-endian, data-type-policy=OVERRIDE, i-signal-type=PRIMITIVE, init-value=0, base-type=BT_ACT405_Stopmodus, invalid-value=Invalid_ACT405_Stopmodus_XIX_ACTs_405_Status_XIX_Klima_LIN5:3, compu {0=Cx0_Normal_Mode (CM_ACT405_Stopmodus_Cx0_Normal_Mode), 1=Cx1_Stop_Mode (CM_ACT405_Stopmodus_Cx1_Stop_Mode), 2=Cx2_reserviert (CM_ACT405_Stopmodus_Cx2_reserviert), 3=Cx3_Fehler (CM_ACT405_Stopmodus_Cx3_Fehler)}, range raw 0..3, transfer-property=PENDING, to Klima(timeout 3.5 s)  # Modus des Aktuators
        frame ACTs_406_Status_XIX_Klima_LIN5: id 0x21, to Klima, frame-length=8, lin-checksum=ENHANCED
          pdu ACTs_406_Status_XIX_Klima_LIN5: length=8, unused-bit-pattern=0
            signal ACT406_ResponseError_XIX_ACTs_406_Status_XIX_Klima_LIN5: start 0, 1 bit, little-endian, data-type-policy=OVERRIDE, i-signal-type=PRIMITIVE, init-value=0, base-type=BT_ACT406_ResponseError, invalid-value=Invalid_ACT406_ResponseError_XIX_ACTs_406_Status_XIX_Klima_LIN5:1, compu {0=Cx0_normal (CM_ACT406_ResponseError_Cx0_normal), 1=Cx1_Fehler (CM_ACT406_ResponseError_Cx1_Fehler)}, range raw 0..1, transfer-property=PENDING, to Klima(timeout 3.5 s)  # siehe LIN2.0-Specification (Darf nicht über ein Fehlergueltigkeitsbit abgesichtert werden!)
            signal ACT406_Uebertemperatur_XIX_ACTs_406_Status_XIX_Klima_LIN5: start 2, 2 bit, little-endian, data-type-policy=OVERRIDE, i-signal-type=PRIMITIVE, init-value=0, base-type=BT_ACT406_Uebertemperatur, invalid-value=Invalid_ACT406_Uebertemperatur_XIX_ACTs_406_Status_XIX_Klima_LIN5:3, compu {0=Cx0_keine_Uebertemperatur (CM_ACT406_Uebertemperatur_Cx0_keine_Uebertemperatur), 1=Cx1_Uebertemperatur (CM_ACT406_Uebertemperatur_Cx1_Uebertemperatur), 2=Cx2_reserviert (CM_ACT406_Uebertemperatur_Cx2_reserviert), 3=Cx3_Fehler (CM_ACT406_Uebertemperatur_Cx3_Fehler)}, range raw 0..3, transfer-property=PENDING, to Klima(timeout 3.5 s)  # Anzeige einer Übertemperatur im Stellmotoren-ASIC
            signal ACT406_Elektr_Defekt_XIX_ACTs_406_Status_XIX_Klima_LIN5: start 4, 2 bit, little-endian, data-type-policy=OVERRIDE, i-signal-type=PRIMITIVE, init-value=0, base-type=BT_ACT406_Elektr_Defekt, invalid-value=Invalid_ACT406_Elektr_Defekt_XIX_ACTs_406_Status_XIX_Klima_LIN5:3, compu {0=Cx0_kein_Fehler (CM_ACT406_Elektr_Defekt_Cx0_kein_Fehler), 1=Cx1_Elektrischer_Fehler_vorhanden (CM_ACT406_Elektr_Defekt_Cx1_Elektrischer_Fehler_vorhanden), 2=Cx2_Permanent_elekt_Fehler_vorhanden (CM_ACT406_Elektr_Defekt_Cx2_Permanent_elekt_Fehler_vorhanden), 3=Cx3_Fehler (CM_ACT406_Elektr_Defekt_Cx3_Fehler)}, range raw 0..3, transfer-property=PENDING, to Klima(timeout 3.5 s)  # Anzeige für einen elektrischen Fehler oder einen permanent el. Fehler im Stellmotor
            signal ACT406_Versorgungsspannung_XIX_ACTs_406_Status_XIX_Klima_LIN5: start 6, 2 bit, little-endian, data-type-policy=OVERRIDE, i-signal-type=PRIMITIVE, init-value=0, base-type=BT_ACT406_Versorgungsspannung, invalid-value=Invalid_ACT406_Versorgungsspannung_XIX_ACTs_406_Status_XIX_Klima_LIN5:3, compu {0=Cx0_Spannung_im_zulaessigen_Bereich (CM_ACT406_Versorgungsspannung_Cx0_Spannung_im_zulaessigen_Bereich), 1=Cx1_Unterspannung (CM_ACT406_Versorgungsspannung_Cx1_Unterspannung), 2=Cx2_Ueberspanung (CM_ACT406_Versorgungsspannung_Cx2_Ueberspanung), 3=Cx3_Fehler (CM_ACT406_Versorgungsspannung_Cx3_Fehler)}, range raw 0..3, transfer-property=PENDING, to Klima(timeout 3.5 s)  # Versorgungsspannung des Aktuators
            signal ACT406_Notlauf_aufgetreten_XIX_ACTs_406_Status_XIX_Klima_LIN5: start 8, 2 bit, little-endian, data-type-policy=OVERRIDE, i-signal-type=PRIMITIVE, init-value=0, base-type=BT_ACT406_Notlauf_aufgetreten, invalid-value=Invalid_ACT406_Notlauf_aufgetreten_XIX_ACTs_406_Status_XIX_Klima_LIN5:3, compu {0=Cx0_kein_Notlauf_aufgetreten (CM_ACT406_Notlauf_aufgetreten_Cx0_kein_Notlauf_aufgetreten), 1=Cx1_Notlauf_aufgetreten (CM_ACT406_Notlauf_aufgetreten_Cx1_Notlauf_aufgetreten), 2=Cx2_reserviert (CM_ACT406_Notlauf_aufgetreten_Cx2_reserviert), 3=Cx3_Fehler (CM_ACT406_Notlauf_aufgetreten_Cx3_Fehler)}, range raw 0..3, transfer-property=PENDING, to Klima(timeout 3.5 s)  # Anzeige eines aufgetretenen Notlaufs seit dem letzten Reset oder "Clear Notlauf aufgetreten"
            signal ACT406_Freigabe_Blockiererkennung_XIX_ACTs_406_Status_XIX_Klima_LIN5: start 10, 2 bit, little-endian, data-type-policy=OVERRIDE, i-signal-type=PRIMITIVE, init-value=0, base-type=BT_ACT406_Freigabe_Blockiererkennung, invalid-value=Invalid_ACT406_Freigabe_Blockiererkennung_XIX_ACTs_406_Status_XIX_Klima_LIN5:3, compu {0=Cx0_Blockiererkennung_aus (CM_ACT406_Freigabe_Blockiererkennung_Cx0_Blockiererkennung_aus), 1=Cx1_Blockiererkennung_ein (CM_ACT406_Freigabe_Blockiererkennung_Cx1_Blockiererkennung_ein), 2=Cx2_reserviert (CM_ACT406_Freigabe_Blockiererkennung_Cx2_reserviert), 3=Cx3_Fehler (CM_ACT406_Freigabe_Blockiererkennung_Cx3_Fehler)}, range raw 0..3, transfer-property=PENDING, to Klima(timeout 3.5 s)  # Aktivierung der Blockiererkennung im Aktuator
            signal ACT406_Blockierung_aufgetreten_XIX_ACTs_406_Status_XIX_Klima_LIN5: start 12, 2 bit, little-endian, data-type-policy=OVERRIDE, i-signal-type=PRIMITIVE, init-value=0, base-type=BT_ACT406_Blockierung_aufgetreten, invalid-value=Invalid_ACT406_Blockierung_aufgetreten_XIX_ACTs_406_Status_XIX_Klima_LIN5:3, compu {0=Cx0_keine_Blockierung (CM_ACT406_Blockierung_aufgetreten_Cx0_keine_Blockierung), 1=Cx1_Blockierung_erkannt (CM_ACT406_Blockierung_aufgetreten_Cx1_Blockierung_erkannt), 2=Cx2_reserviert (CM_ACT406_Blockierung_aufgetreten_Cx2_reserviert), 3=Cx3_Fehler (CM_ACT406_Blockierung_aufgetreten_Cx3_Fehler)}, range raw 0..3, transfer-property=PENDING, to Klima(timeout 3.5 s)  # Anzeige einer aufgetretenen Blockierung seit dem letzten Reset oder "Clear Blockierung aufgetreten"
            signal ACT406_Reset_XIX_ACTs_406_Status_XIX_Klima_LIN5: start 14, 2 bit, little-endian, data-type-policy=OVERRIDE, i-signal-type=PRIMITIVE, init-value=0, base-type=BT_ACT406_Reset, invalid-value=Invalid_ACT406_Reset_XIX_ACTs_406_Status_XIX_Klima_LIN5:3, compu {0=Cx0_kein_Reset (CM_ACT406_Reset_Cx0_kein_Reset), 1=Cx1_Reset_durchgefuehrt (CM_ACT406_Reset_Cx1_Reset_durchgefuehrt), 2=Cx2_reserviert (CM_ACT406_Reset_Cx2_reserviert), 3=Cx3_Fehler (CM_ACT406_Reset_Cx3_Fehler)}, range raw 0..3, transfer-property=PENDING, to Klima(timeout 3.5 s)  # Anzeige eines aufgetretenen Reset seit dem letzten ¿Clear Reset"
            signal ACT406_Spulenbestromung_XIX_ACTs_406_Status_XIX_Klima_LIN5: start 16, 2 bit, little-endian, data-type-policy=OVERRIDE, i-signal-type=PRIMITIVE, init-value=0, base-type=BT_ACT406_Spulenbestromung, invalid-value=Invalid_ACT406_Spulenbestromung_XIX_ACTs_406_Status_XIX_Klima_LIN5:3, compu {0=Cx0_Motorspulen_unbestromt (CM_ACT406_Spulenbestromung_Cx0_Motorspulen_unbestromt), 1=Cx1_Motorspulen_bestromt (CM_ACT406_Spulenbestromung_Cx1_Motorspulen_bestromt), 2=Cx2_reserviert (CM_ACT406_Spulenbestromung_Cx2_reserviert), 3=Cx3_Fehler (CM_ACT406_Spulenbestromung_Cx3_Fehler)}, range raw 0..3, transfer-property=PENDING, to Klima(timeout 3.5 s)  # Spulenbestromung im Haltezustand des Aktuators
            signal ACT406_Positionsvorgabe_Status_XIX_ACTs_406_Status_XIX_Klima_LIN5: start 18, 2 bit, little-endian, data-type-policy=OVERRIDE, i-signal-type=PRIMITIVE, init-value=0, base-type=BT_ACT406_Positionsvorgabe_Status, invalid-value=Invalid_ACT406_Positionsvorgabe_Status_XIX_ACTs_406_Status_XIX_Klima_LIN5:3, compu {0=Cx0_Soll_Position_gueltig (CM_ACT406_Positionsvorgabe_Status_Cx0_Soll_Position_gueltig), 1=Cx1_Start_Position_gueltig (CM_ACT406_Positionsvorgabe_Status_Cx1_Start_Position_gueltig), 2=Cx2_keine_Positionsvorgabe_gueltig (CM_ACT406_Positionsvorgabe_Status_Cx2_keine_Positionsvorgabe_gueltig), 3=Cx3_Fehler (CM_ACT406_Positionsvorgabe_Status_Cx3_Fehler)}, range raw 0..3, transfer-property=PENDING, to Klima(timeout 3.5 s)  # Position des Aktuators
            signal ACT406_Geschwindigkeitsstatus_XIX_ACTs_406_Status_XIX_Klima_LIN5: start 20, 4 bit, little-endian, data-type-policy=OVERRIDE, i-signal-type=PRIMITIVE, init-value=0, base-type=BT_ACT406_Geschwindigkeitsstatus, invalid-value=Invalid_ACT406_Geschwindigkeitsstatus_XIX_ACTs_406_Status_XIX_Klima_LIN5:15, compu {0=Cx0_Motor_steht (CM_ACT406_Geschwindigkeitsstatus_Cx0_Motor_steht), 1=Cx1_Geschwindigkeitsstufe_1 (CM_ACT406_Geschwindigkeitsstatus_Cx1_Geschwindigkeitsstufe_1), 2=Cx2_Geschwindigkeitsstufe_2 (CM_ACT406_Geschwindigkeitsstatus_Cx2_Geschwindigkeitsstufe_2), 3=Cx3_Geschwindigkeitsstufe_3 (CM_ACT406_Geschwindigkeitsstatus_Cx3_Geschwindigkeitsstufe_3), 4=Cx4_Geschwindigkeitsstufe_4 (CM_ACT406_Geschwindigkeitsstatus_Cx4_Geschwindigkeitsstufe_4), 5=Cx5_Autospeed (CM_ACT406_Geschwindigkeitsstatus_Cx5_Autospeed), 15=Cxf_Fehler (CM_ACT406_Geschwindigkeitsstatus_Cxf_Fehler)}, range raw 0..15, transfer-property=PENDING, to Klima(timeout 3.5 s)  # Geschwindigkeitsstufe mit der die aktuelle Verfahrbewegung durchgeführt wird
            signal ACT406_Ist_Position_Aktuator_XIX_ACTs_406_Status_XIX_Klima_LIN5: start 24, 16 bit, little-endian, data-type-policy=OVERRIDE, i-signal-type=PRIMITIVE, init-value=32767, base-type=BT_ACT406_Ist_Position_Aktuator, invalid-value=Invalid_ACT406_Ist_Position_Aktuator_XIX_ACTs_406_Status_XIX_Klima_LIN5:65535, compu {phys=raw for raw 0..65534, 32767=Cx7fff_Init (CM_ACT406_Ist_Position_Aktuator_Cx7fff_Init), 65535=Cxffff_Fehler (CM_ACT406_Ist_Position_Aktuator_Cxffff_Fehler); unit Unit_None}, range phys 0..65534 Unit_None, raw 0..65535, unit=Unit_None, transfer-property=PENDING, to Klima(timeout 3.5 s)  # IST-Position des Aktuators
            signal ACT406_Verfahrrichtung_XIX_ACTs_406_Status_XIX_Klima_LIN5: start 40, 2 bit, little-endian, data-type-policy=OVERRIDE, i-signal-type=PRIMITIVE, init-value=2, base-type=BT_ACT406_Verfahrrichtung, invalid-value=Invalid_ACT406_Verfahrrichtung_XIX_ACTs_406_Status_XIX_Klima_LIN5:3, compu {0=Cx0_Richtung_kl_Schrittpositionen (CM_ACT406_Verfahrrichtung_Cx0_Richtung_kl_Schrittpositionen), 1=Cx1_Richtung_gr_Schrittpositionen (CM_ACT406_Verfahrrichtung_Cx1_Richtung_gr_Schrittpositionen), 2=Cx2_Init (CM_ACT406_Verfahrrichtung_Cx2_Init), 3=Cx3_Fehler (CM_ACT406_Verfahrrichtung_Cx3_Fehler)}, range raw 0..3, transfer-property=PENDING, to Klima(timeout 3.5 s)  # Verfahrrichtung der aktuellen oder zuletzt stattgefundenen Bewegung des Aktuators
            signal ACT406_Selbsthaltemoment_XIX_ACTs_406_Status_XIX_Klima_LIN5: start 42, 2 bit, little-endian, data-type-policy=OVERRIDE, i-signal-type=PRIMITIVE, init-value=0, base-type=BT_ACT406_Selbsthaltemoment, invalid-value=Invalid_ACT406_Selbsthaltemoment_XIX_ACTs_406_Status_XIX_Klima_LIN5:3, compu {0=Cx0_ohne_Selbsthaltemoment (CM_ACT406_Selbsthaltemoment_Cx0_ohne_Selbsthaltemoment), 1=Cx1_mit_Selbsthaltemoment (CM_ACT406_Selbsthaltemoment_Cx1_mit_Selbsthaltemoment), 2=Cx2_reserviert (CM_ACT406_Selbsthaltemoment_Cx2_reserviert), 3=Cx3_Fehler (CM_ACT406_Selbsthaltemoment_Cx3_Fehler)}, range raw 0..3, transfer-property=PENDING, to Klima(timeout 3.5 s)  # Das Signal gibt an ob ein selbsthemmendes Getriebe verbaut ist oder die SHB eingeschaltet ist
            signal ACT406_Sonderfunktionen_XIX_ACTs_406_Status_XIX_Klima_LIN5: start 44, 2 bit, little-endian, data-type-policy=OVERRIDE, i-signal-type=PRIMITIVE, init-value=0, base-type=BT_ACT406_Sonderfunktionen, invalid-value=Invalid_ACT406_Sonderfunktionen_XIX_ACTs_406_Status_XIX_Klima_LIN5:3, compu {0=Cx0_Keine_Sonderfunktion_aktiv (CM_ACT406_Sonderfunktionen_Cx0_Keine_Sonderfunktion_aktiv), 1=Cx1_Sonderfunktion1_aktiv (CM_ACT406_Sonderfunktionen_Cx1_Sonderfunktion1_aktiv), 2=Cx2_Sonderfunktion2_aktiv (CM_ACT406_Sonderfunktionen_Cx2_Sonderfunktion2_aktiv), 3=Cx3_Fehler (CM_ACT406_Sonderfunktionen_Cx3_Fehler)}, range raw 0..3, transfer-property=PENDING, to Klima(timeout 3.5 s)  # Funktionen des Aktuators
            signal ACT406_Variante_XIX_ACTs_406_Status_XIX_Klima_LIN5: start 46, 2 bit, little-endian, data-type-policy=OVERRIDE, i-signal-type=PRIMITIVE, init-value=0, base-type=BT_ACT406_Variante, compu {0=Cx0_Variante_1 (CM_ACT406_Variante_Cx0_Variante_1), 1=Cx1_Variante_2 (CM_ACT406_Variante_Cx1_Variante_2), 2=Cx2_Variante_3 (CM_ACT406_Variante_Cx2_Variante_3), 3=Cx3_Fehler_oder_nicht_umgesetzt (CM_ACT406_Variante_Cx3_Fehler_oder_nicht_umgesetzt)}, range raw 0..3, transfer-property=PENDING, to Klima(timeout 3.5 s)  # Das Signal gibt an welche Variante des Stellmotors verbaut ist
            signal ACT406_Adresse_Aktuator_XIX_ACTs_406_Status_XIX_Klima_LIN5: start 48, 8 bit, little-endian, data-type-policy=OVERRIDE, i-signal-type=PRIMITIVE, init-value=255, base-type=BT_ACT406_Adresse_Aktuator, compu {255=Cxff_Init (CM_ACT406_Adresse_Aktuator_Cxff_Init)}, range raw 255, transfer-property=PENDING, to Klima(timeout 3.5 s)  # Adresse Aktuator
            signal ACT406_Notlauffreigabe_XIX_ACTs_406_Status_XIX_Klima_LIN5: start 56, 2 bit, little-endian, data-type-policy=OVERRIDE, i-signal-type=PRIMITIVE, init-value=0, base-type=BT_ACT406_Notlauffreigabe, invalid-value=Invalid_ACT406_Notlauffreigabe_XIX_ACTs_406_Status_XIX_Klima_LIN5:3, compu {0=Cx0_Notlauf_aus (CM_ACT406_Notlauffreigabe_Cx0_Notlauf_aus), 1=Cx1_Notlauf_ein (CM_ACT406_Notlauffreigabe_Cx1_Notlauf_ein), 2=Cx2_reserviert (CM_ACT406_Notlauffreigabe_Cx2_reserviert), 3=Cx3_Fehler (CM_ACT406_Notlauffreigabe_Cx3_Fehler)}, range raw 0..3, transfer-property=PENDING, to Klima(timeout 3.5 s)  # Freigabe der Notlauffunktion des Aktuators
            signal ACT406_Notlaufposition_XIX_ACTs_406_Status_XIX_Klima_LIN5: start 58, 2 bit, little-endian, data-type-policy=OVERRIDE, i-signal-type=PRIMITIVE, init-value=0, base-type=BT_ACT406_Notlaufposition, invalid-value=Invalid_ACT406_Notlaufposition_XIX_ACTs_406_Status_XIX_Klima_LIN5:3, compu {0=Cx0_unterer_Anschlag (CM_ACT406_Notlaufposition_Cx0_unterer_Anschlag), 1=Cx1_oberer_Anschlag (CM_ACT406_Notlaufposition_Cx1_oberer_Anschlag), 2=Cx2_reserviert (CM_ACT406_Notlaufposition_Cx2_reserviert), 3=Cx3_Fehler (CM_ACT406_Notlaufposition_Cx3_Fehler)}, range raw 0..3, transfer-property=PENDING, to Klima(timeout 3.5 s)  # Positionsvorgabe des Aktuators
            signal ACT406_Drehrichtung_XIX_ACTs_406_Status_XIX_Klima_LIN5: start 60, 2 bit, little-endian, data-type-policy=OVERRIDE, i-signal-type=PRIMITIVE, init-value=0, base-type=BT_ACT406_Drehrichtung, invalid-value=Invalid_ACT406_Drehrichtung_XIX_ACTs_406_Status_XIX_Klima_LIN5:3, compu {0=Cx0_Bewegung_in_Richtung_CW (CM_ACT406_Drehrichtung_Cx0_Bewegung_in_Richtung_CW), 1=Cx1_Bewegung_in_Richtung_CCW (CM_ACT406_Drehrichtung_Cx1_Bewegung_in_Richtung_CCW), 2=Cx2_reserviert (CM_ACT406_Drehrichtung_Cx2_reserviert), 3=Cx3_Fehler (CM_ACT406_Drehrichtung_Cx3_Fehler)}, range raw 0..3, transfer-property=PENDING, to Klima(timeout 3.5 s)  # Drehrichtung des Aktuators
            signal ACT406_Stopmodus_XIX_ACTs_406_Status_XIX_Klima_LIN5: start 62, 2 bit, little-endian, data-type-policy=OVERRIDE, i-signal-type=PRIMITIVE, init-value=0, base-type=BT_ACT406_Stopmodus, invalid-value=Invalid_ACT406_Stopmodus_XIX_ACTs_406_Status_XIX_Klima_LIN5:3, compu {0=Cx0_Normal_Mode (CM_ACT406_Stopmodus_Cx0_Normal_Mode), 1=Cx1_Stop_Mode (CM_ACT406_Stopmodus_Cx1_Stop_Mode), 2=Cx2_reserviert (CM_ACT406_Stopmodus_Cx2_reserviert), 3=Cx3_Fehler (CM_ACT406_Stopmodus_Cx3_Fehler)}, range raw 0..3, transfer-property=PENDING, to Klima(timeout 3.5 s)  # Modus des Aktuators
        frame ACTs_407_Status_XIX_Klima_LIN5: id 0x22, to Klima, frame-length=8, lin-checksum=ENHANCED
          pdu ACTs_407_Status_XIX_Klima_LIN5: length=8, unused-bit-pattern=0
            signal ACT407_ResponseError_XIX_ACTs_407_Status_XIX_Klima_LIN5: start 0, 1 bit, little-endian, data-type-policy=OVERRIDE, i-signal-type=PRIMITIVE, init-value=0, base-type=BT_ACT407_ResponseError, invalid-value=Invalid_ACT407_ResponseError_XIX_ACTs_407_Status_XIX_Klima_LIN5:1, compu {0=Cx0_normal (CM_ACT407_ResponseError_Cx0_normal), 1=Cx1_Fehler (CM_ACT407_ResponseError_Cx1_Fehler)}, range raw 0..1, transfer-property=PENDING, to Klima(timeout 3.5 s)  # siehe LIN2.0-Specification (Darf nicht über ein Fehlergueltigkeitsbit abgesichtert werden!)
            signal ACT407_Uebertemperatur_XIX_ACTs_407_Status_XIX_Klima_LIN5: start 2, 2 bit, little-endian, data-type-policy=OVERRIDE, i-signal-type=PRIMITIVE, init-value=0, base-type=BT_ACT407_Uebertemperatur, invalid-value=Invalid_ACT407_Uebertemperatur_XIX_ACTs_407_Status_XIX_Klima_LIN5:3, compu {0=Cx0_keine_Uebertemperatur (CM_ACT407_Uebertemperatur_Cx0_keine_Uebertemperatur), 1=Cx1_Uebertemperatur (CM_ACT407_Uebertemperatur_Cx1_Uebertemperatur), 2=Cx2_reserviert (CM_ACT407_Uebertemperatur_Cx2_reserviert), 3=Cx3_Fehler (CM_ACT407_Uebertemperatur_Cx3_Fehler)}, range raw 0..3, transfer-property=PENDING, to Klima(timeout 3.5 s)  # Anzeige einer Übertemperatur im Stellmotoren-ASIC
            signal ACT407_Elektr_Defekt_XIX_ACTs_407_Status_XIX_Klima_LIN5: start 4, 2 bit, little-endian, data-type-policy=OVERRIDE, i-signal-type=PRIMITIVE, init-value=0, base-type=BT_ACT407_Elektr_Defekt, invalid-value=Invalid_ACT407_Elektr_Defekt_XIX_ACTs_407_Status_XIX_Klima_LIN5:3, compu {0=Cx0_kein_Fehler (CM_ACT407_Elektr_Defekt_Cx0_kein_Fehler), 1=Cx1_Elektrischer_Fehler_vorhanden (CM_ACT407_Elektr_Defekt_Cx1_Elektrischer_Fehler_vorhanden), 2=Cx2_Permanent_elekt_Fehler_vorhanden (CM_ACT407_Elektr_Defekt_Cx2_Permanent_elekt_Fehler_vorhanden), 3=Cx3_Fehler (CM_ACT407_Elektr_Defekt_Cx3_Fehler)}, range raw 0..3, transfer-property=PENDING, to Klima(timeout 3.5 s)  # Anzeige für einen elektrischen Fehler oder einen permanent el. Fehler im Stellmotor
            signal ACT407_Versorgungsspannung_XIX_ACTs_407_Status_XIX_Klima_LIN5: start 6, 2 bit, little-endian, data-type-policy=OVERRIDE, i-signal-type=PRIMITIVE, init-value=0, base-type=BT_ACT407_Versorgungsspannung, invalid-value=Invalid_ACT407_Versorgungsspannung_XIX_ACTs_407_Status_XIX_Klima_LIN5:3, compu {0=Cx0_Spannung_im_zulaessigen_Bereich (CM_ACT407_Versorgungsspannung_Cx0_Spannung_im_zulaessigen_Bereich), 1=Cx1_Unterspannung (CM_ACT407_Versorgungsspannung_Cx1_Unterspannung), 2=Cx2_Ueberspanung (CM_ACT407_Versorgungsspannung_Cx2_Ueberspanung), 3=Cx3_Fehler (CM_ACT407_Versorgungsspannung_Cx3_Fehler)}, range raw 0..3, transfer-property=PENDING, to Klima(timeout 3.5 s)  # Versorgungsspannung des Aktuators
            signal ACT407_Notlauf_aufgetreten_XIX_ACTs_407_Status_XIX_Klima_LIN5: start 8, 2 bit, little-endian, data-type-policy=OVERRIDE, i-signal-type=PRIMITIVE, init-value=0, base-type=BT_ACT407_Notlauf_aufgetreten, invalid-value=Invalid_ACT407_Notlauf_aufgetreten_XIX_ACTs_407_Status_XIX_Klima_LIN5:3, compu {0=Cx0_kein_Notlauf_aufgetreten (CM_ACT407_Notlauf_aufgetreten_Cx0_kein_Notlauf_aufgetreten), 1=Cx1_Notlauf_aufgetreten (CM_ACT407_Notlauf_aufgetreten_Cx1_Notlauf_aufgetreten), 2=Cx2_reserviert (CM_ACT407_Notlauf_aufgetreten_Cx2_reserviert), 3=Cx3_Fehler (CM_ACT407_Notlauf_aufgetreten_Cx3_Fehler)}, range raw 0..3, transfer-property=PENDING, to Klima(timeout 3.5 s)  # Anzeige eines aufgetretenen Notlaufs seit dem letzten Reset oder "Clear Notlauf aufgetreten"
            signal ACT407_Freigabe_Blockiererkennung_XIX_ACTs_407_Status_XIX_Klima_LIN5: start 10, 2 bit, little-endian, data-type-policy=OVERRIDE, i-signal-type=PRIMITIVE, init-value=0, base-type=BT_ACT407_Freigabe_Blockiererkennung, invalid-value=Invalid_ACT407_Freigabe_Blockiererkennung_XIX_ACTs_407_Status_XIX_Klima_LIN5:3, compu {0=Cx0_Blockiererkennung_aus (CM_ACT407_Freigabe_Blockiererkennung_Cx0_Blockiererkennung_aus), 1=Cx1_Blockiererkennung_ein (CM_ACT407_Freigabe_Blockiererkennung_Cx1_Blockiererkennung_ein), 2=Cx2_reserviert (CM_ACT407_Freigabe_Blockiererkennung_Cx2_reserviert), 3=Cx3_Fehler (CM_ACT407_Freigabe_Blockiererkennung_Cx3_Fehler)}, range raw 0..3, transfer-property=PENDING, to Klima(timeout 3.5 s)  # Aktivierung der Blockiererkennung im Aktuator
            signal ACT407_Blockierung_aufgetreten_XIX_ACTs_407_Status_XIX_Klima_LIN5: start 12, 2 bit, little-endian, data-type-policy=OVERRIDE, i-signal-type=PRIMITIVE, init-value=0, base-type=BT_ACT407_Blockierung_aufgetreten, invalid-value=Invalid_ACT407_Blockierung_aufgetreten_XIX_ACTs_407_Status_XIX_Klima_LIN5:3, compu {0=Cx0_keine_Blockierung (CM_ACT407_Blockierung_aufgetreten_Cx0_keine_Blockierung), 1=Cx1_Blockierung_erkannt (CM_ACT407_Blockierung_aufgetreten_Cx1_Blockierung_erkannt), 2=Cx2_reserviert (CM_ACT407_Blockierung_aufgetreten_Cx2_reserviert), 3=Cx3_Fehler (CM_ACT407_Blockierung_aufgetreten_Cx3_Fehler)}, range raw 0..3, transfer-property=PENDING, to Klima(timeout 3.5 s)  # Anzeige einer aufgetretenen Blockierung seit dem letzten Reset oder "Clear Blockierung aufgetreten"
            signal ACT407_Reset_XIX_ACTs_407_Status_XIX_Klima_LIN5: start 14, 2 bit, little-endian, data-type-policy=OVERRIDE, i-signal-type=PRIMITIVE, init-value=0, base-type=BT_ACT407_Reset, invalid-value=Invalid_ACT407_Reset_XIX_ACTs_407_Status_XIX_Klima_LIN5:3, compu {0=Cx0_kein_Reset (CM_ACT407_Reset_Cx0_kein_Reset), 1=Cx1_Reset_durchgefuehrt (CM_ACT407_Reset_Cx1_Reset_durchgefuehrt), 2=Cx2_reserviert (CM_ACT407_Reset_Cx2_reserviert), 3=Cx3_Fehler (CM_ACT407_Reset_Cx3_Fehler)}, range raw 0..3, transfer-property=PENDING, to Klima(timeout 3.5 s)  # Anzeige eines aufgetretenen Reset seit dem letzten ¿Clear Reset"
            signal ACT407_Spulenbestromung_XIX_ACTs_407_Status_XIX_Klima_LIN5: start 16, 2 bit, little-endian, data-type-policy=OVERRIDE, i-signal-type=PRIMITIVE, init-value=0, base-type=BT_ACT407_Spulenbestromung, invalid-value=Invalid_ACT407_Spulenbestromung_XIX_ACTs_407_Status_XIX_Klima_LIN5:3, compu {0=Cx0_Motorspulen_unbestromt (CM_ACT407_Spulenbestromung_Cx0_Motorspulen_unbestromt), 1=Cx1_Motorspulen_bestromt (CM_ACT407_Spulenbestromung_Cx1_Motorspulen_bestromt), 2=Cx2_reserviert (CM_ACT407_Spulenbestromung_Cx2_reserviert), 3=Cx3_Fehler (CM_ACT407_Spulenbestromung_Cx3_Fehler)}, range raw 0..3, transfer-property=PENDING, to Klima(timeout 3.5 s)  # Spulenbestromung im Haltezustand des Aktuators
            signal ACT407_Positionsvorgabe_Status_XIX_ACTs_407_Status_XIX_Klima_LIN5: start 18, 2 bit, little-endian, data-type-policy=OVERRIDE, i-signal-type=PRIMITIVE, init-value=0, base-type=BT_ACT407_Positionsvorgabe_Status, invalid-value=Invalid_ACT407_Positionsvorgabe_Status_XIX_ACTs_407_Status_XIX_Klima_LIN5:3, compu {0=Cx0_Soll_Position_gueltig (CM_ACT407_Positionsvorgabe_Status_Cx0_Soll_Position_gueltig), 1=Cx1_Start_Position_gueltig (CM_ACT407_Positionsvorgabe_Status_Cx1_Start_Position_gueltig), 2=Cx2_keine_Positionsvorgabe_gueltig (CM_ACT407_Positionsvorgabe_Status_Cx2_keine_Positionsvorgabe_gueltig), 3=Cx3_Fehler (CM_ACT407_Positionsvorgabe_Status_Cx3_Fehler)}, range raw 0..3, transfer-property=PENDING, to Klima(timeout 3.5 s)  # Position des Aktuators
            signal ACT407_Geschwindigkeitsstatus_XIX_ACTs_407_Status_XIX_Klima_LIN5: start 20, 4 bit, little-endian, data-type-policy=OVERRIDE, i-signal-type=PRIMITIVE, init-value=0, base-type=BT_ACT407_Geschwindigkeitsstatus, invalid-value=Invalid_ACT407_Geschwindigkeitsstatus_XIX_ACTs_407_Status_XIX_Klima_LIN5:15, compu {0=Cx0_Motor_steht (CM_ACT407_Geschwindigkeitsstatus_Cx0_Motor_steht), 1=Cx1_Geschwindigkeitsstufe_1 (CM_ACT407_Geschwindigkeitsstatus_Cx1_Geschwindigkeitsstufe_1), 2=Cx2_Geschwindigkeitsstufe_2 (CM_ACT407_Geschwindigkeitsstatus_Cx2_Geschwindigkeitsstufe_2), 3=Cx3_Geschwindigkeitsstufe_3 (CM_ACT407_Geschwindigkeitsstatus_Cx3_Geschwindigkeitsstufe_3), 4=Cx4_Geschwindigkeitsstufe_4 (CM_ACT407_Geschwindigkeitsstatus_Cx4_Geschwindigkeitsstufe_4), 5=Cx5_Autospeed (CM_ACT407_Geschwindigkeitsstatus_Cx5_Autospeed), 15=Cxf_Fehler (CM_ACT407_Geschwindigkeitsstatus_Cxf_Fehler)}, range raw 0..15, transfer-property=PENDING, to Klima(timeout 3.5 s)  # Geschwindigkeitsstufe mit der die aktuelle Verfahrbewegung durchgeführt wird
            signal ACT407_Ist_Position_Aktuator_XIX_ACTs_407_Status_XIX_Klima_LIN5: start 24, 16 bit, little-endian, data-type-policy=OVERRIDE, i-signal-type=PRIMITIVE, init-value=32767, base-type=BT_ACT407_Ist_Position_Aktuator, invalid-value=Invalid_ACT407_Ist_Position_Aktuator_XIX_ACTs_407_Status_XIX_Klima_LIN5:65535, compu {phys=raw for raw 0..65534, 32767=Cx7fff_Init (CM_ACT407_Ist_Position_Aktuator_Cx7fff_Init), 65535=Cxffff_Fehler (CM_ACT407_Ist_Position_Aktuator_Cxffff_Fehler); unit Unit_None}, range phys 0..65534 Unit_None, raw 0..65535, unit=Unit_None, transfer-property=PENDING, to Klima(timeout 3.5 s)  # IST-Position des Aktuators
            signal ACT407_Verfahrrichtung_XIX_ACTs_407_Status_XIX_Klima_LIN5: start 40, 2 bit, little-endian, data-type-policy=OVERRIDE, i-signal-type=PRIMITIVE, init-value=2, base-type=BT_ACT407_Verfahrrichtung, invalid-value=Invalid_ACT407_Verfahrrichtung_XIX_ACTs_407_Status_XIX_Klima_LIN5:3, compu {0=Cx0_Richtung_kl_Schrittpositionen (CM_ACT407_Verfahrrichtung_Cx0_Richtung_kl_Schrittpositionen), 1=Cx1_Richtung_gr_Schrittpositionen (CM_ACT407_Verfahrrichtung_Cx1_Richtung_gr_Schrittpositionen), 2=Cx2_Init (CM_ACT407_Verfahrrichtung_Cx2_Init), 3=Cx3_Fehler (CM_ACT407_Verfahrrichtung_Cx3_Fehler)}, range raw 0..3, transfer-property=PENDING, to Klima(timeout 3.5 s)  # Verfahrrichtung der aktuellen oder zuletzt stattgefundenen Bewegung des Aktuators
            signal ACT407_Selbsthaltemoment_XIX_ACTs_407_Status_XIX_Klima_LIN5: start 42, 2 bit, little-endian, data-type-policy=OVERRIDE, i-signal-type=PRIMITIVE, init-value=0, base-type=BT_ACT407_Selbsthaltemoment, invalid-value=Invalid_ACT407_Selbsthaltemoment_XIX_ACTs_407_Status_XIX_Klima_LIN5:3, compu {0=Cx0_ohne_Selbsthaltemoment (CM_ACT407_Selbsthaltemoment_Cx0_ohne_Selbsthaltemoment), 1=Cx1_mit_Selbsthaltemoment (CM_ACT407_Selbsthaltemoment_Cx1_mit_Selbsthaltemoment), 2=Cx2_reserviert (CM_ACT407_Selbsthaltemoment_Cx2_reserviert), 3=Cx3_Fehler (CM_ACT407_Selbsthaltemoment_Cx3_Fehler)}, range raw 0..3, transfer-property=PENDING, to Klima(timeout 3.5 s)  # Das Signal gibt an ob ein selbsthemmendes Getriebe verbaut ist oder die SHB eingeschaltet ist
            signal ACT407_Sonderfunktionen_XIX_ACTs_407_Status_XIX_Klima_LIN5: start 44, 2 bit, little-endian, data-type-policy=OVERRIDE, i-signal-type=PRIMITIVE, init-value=0, base-type=BT_ACT407_Sonderfunktionen, invalid-value=Invalid_ACT407_Sonderfunktionen_XIX_ACTs_407_Status_XIX_Klima_LIN5:3, compu {0=Cx0_Keine_Sonderfunktion_aktiv (CM_ACT407_Sonderfunktionen_Cx0_Keine_Sonderfunktion_aktiv), 1=Cx1_Sonderfunktion1_aktiv (CM_ACT407_Sonderfunktionen_Cx1_Sonderfunktion1_aktiv), 2=Cx2_Sonderfunktion2_aktiv (CM_ACT407_Sonderfunktionen_Cx2_Sonderfunktion2_aktiv), 3=Cx3_Fehler (CM_ACT407_Sonderfunktionen_Cx3_Fehler)}, range raw 0..3, transfer-property=PENDING, to Klima(timeout 3.5 s)  # Funktionen des Aktuators
            signal ACT407_Variante_XIX_ACTs_407_Status_XIX_Klima_LIN5: start 46, 2 bit, little-endian, data-type-policy=OVERRIDE, i-signal-type=PRIMITIVE, init-value=0, base-type=BT_ACT407_Variante, compu {0=Cx0_Variante_1 (CM_ACT407_Variante_Cx0_Variante_1), 1=Cx1_Variante_2 (CM_ACT407_Variante_Cx1_Variante_2), 2=Cx2_Variante_3 (CM_ACT407_Variante_Cx2_Variante_3), 3=Cx3_Fehler_oder_nicht_umgesetzt (CM_ACT407_Variante_Cx3_Fehler_oder_nicht_umgesetzt)}, range raw 0..3, transfer-property=PENDING, to Klima(timeout 3.5 s)  # Das Signal gibt an welche Variante des Stellmotors verbaut ist
            signal ACT407_Adresse_Aktuator_XIX_ACTs_407_Status_XIX_Klima_LIN5: start 48, 8 bit, little-endian, data-type-policy=OVERRIDE, i-signal-type=PRIMITIVE, init-value=255, base-type=BT_ACT407_Adresse_Aktuator, compu {255=Cxff_Init (CM_ACT407_Adresse_Aktuator_Cxff_Init)}, range raw 255, transfer-property=PENDING, to Klima(timeout 3.5 s)  # Adresse Aktuator
            signal ACT407_Notlauffreigabe_XIX_ACTs_407_Status_XIX_Klima_LIN5: start 56, 2 bit, little-endian, data-type-policy=OVERRIDE, i-signal-type=PRIMITIVE, init-value=0, base-type=BT_ACT407_Notlauffreigabe, invalid-value=Invalid_ACT407_Notlauffreigabe_XIX_ACTs_407_Status_XIX_Klima_LIN5:3, compu {0=Cx0_Notlauf_aus (CM_ACT407_Notlauffreigabe_Cx0_Notlauf_aus), 1=Cx1_Notlauf_ein (CM_ACT407_Notlauffreigabe_Cx1_Notlauf_ein), 2=Cx2_reserviert (CM_ACT407_Notlauffreigabe_Cx2_reserviert), 3=Cx3_Fehler (CM_ACT407_Notlauffreigabe_Cx3_Fehler)}, range raw 0..3, transfer-property=PENDING, to Klima(timeout 3.5 s)  # Freigabe der Notlauffunktion des Aktuators
            signal ACT407_Notlaufposition_XIX_ACTs_407_Status_XIX_Klima_LIN5: start 58, 2 bit, little-endian, data-type-policy=OVERRIDE, i-signal-type=PRIMITIVE, init-value=0, base-type=BT_ACT407_Notlaufposition, invalid-value=Invalid_ACT407_Notlaufposition_XIX_ACTs_407_Status_XIX_Klima_LIN5:3, compu {0=Cx0_unterer_Anschlag (CM_ACT407_Notlaufposition_Cx0_unterer_Anschlag), 1=Cx1_oberer_Anschlag (CM_ACT407_Notlaufposition_Cx1_oberer_Anschlag), 2=Cx2_reserviert (CM_ACT407_Notlaufposition_Cx2_reserviert), 3=Cx3_Fehler (CM_ACT407_Notlaufposition_Cx3_Fehler)}, range raw 0..3, transfer-property=PENDING, to Klima(timeout 3.5 s)  # Positionsvorgabe des Aktuators
            signal ACT407_Drehrichtung_XIX_ACTs_407_Status_XIX_Klima_LIN5: start 60, 2 bit, little-endian, data-type-policy=OVERRIDE, i-signal-type=PRIMITIVE, init-value=0, base-type=BT_ACT407_Drehrichtung, invalid-value=Invalid_ACT407_Drehrichtung_XIX_ACTs_407_Status_XIX_Klima_LIN5:3, compu {0=Cx0_Bewegung_in_Richtung_CW (CM_ACT407_Drehrichtung_Cx0_Bewegung_in_Richtung_CW), 1=Cx1_Bewegung_in_Richtung_CCW (CM_ACT407_Drehrichtung_Cx1_Bewegung_in_Richtung_CCW), 2=Cx2_reserviert (CM_ACT407_Drehrichtung_Cx2_reserviert), 3=Cx3_Fehler (CM_ACT407_Drehrichtung_Cx3_Fehler)}, range raw 0..3, transfer-property=PENDING, to Klima(timeout 3.5 s)  # Drehrichtung des Aktuators
            signal ACT407_Stopmodus_XIX_ACTs_407_Status_XIX_Klima_LIN5: start 62, 2 bit, little-endian, data-type-policy=OVERRIDE, i-signal-type=PRIMITIVE, init-value=0, base-type=BT_ACT407_Stopmodus, invalid-value=Invalid_ACT407_Stopmodus_XIX_ACTs_407_Status_XIX_Klima_LIN5:3, compu {0=Cx0_Normal_Mode (CM_ACT407_Stopmodus_Cx0_Normal_Mode), 1=Cx1_Stop_Mode (CM_ACT407_Stopmodus_Cx1_Stop_Mode), 2=Cx2_reserviert (CM_ACT407_Stopmodus_Cx2_reserviert), 3=Cx3_Fehler (CM_ACT407_Stopmodus_Cx3_Fehler)}, range raw 0..3, transfer-property=PENDING, to Klima(timeout 3.5 s)  # Modus des Aktuators
        frame ACTs_408_Status_XIX_Klima_LIN5: id 0x23, to Klima, frame-length=8, lin-checksum=ENHANCED
          pdu ACTs_408_Status_XIX_Klima_LIN5: length=8, unused-bit-pattern=0
            signal ACT408_ResponseError_XIX_ACTs_408_Status_XIX_Klima_LIN5: start 0, 1 bit, little-endian, data-type-policy=OVERRIDE, i-signal-type=PRIMITIVE, init-value=0, base-type=BT_ACT408_ResponseError, invalid-value=Invalid_ACT408_ResponseError_XIX_ACTs_408_Status_XIX_Klima_LIN5:1, compu {0=Cx0_normal (CM_ACT408_ResponseError_Cx0_normal), 1=Cx1_Fehler (CM_ACT408_ResponseError_Cx1_Fehler)}, range raw 0..1, transfer-property=PENDING, to Klima(timeout 3.5 s)  # siehe LIN2.0-Specification (Darf nicht über ein Fehlergueltigkeitsbit abgesichtert werden!)
            signal ACT408_Uebertemperatur_XIX_ACTs_408_Status_XIX_Klima_LIN5: start 2, 2 bit, little-endian, data-type-policy=OVERRIDE, i-signal-type=PRIMITIVE, init-value=0, base-type=BT_ACT408_Uebertemperatur, invalid-value=Invalid_ACT408_Uebertemperatur_XIX_ACTs_408_Status_XIX_Klima_LIN5:3, compu {0=Cx0_keine_Uebertemperatur (CM_ACT408_Uebertemperatur_Cx0_keine_Uebertemperatur), 1=Cx1_Uebertemperatur (CM_ACT408_Uebertemperatur_Cx1_Uebertemperatur), 2=Cx2_reserviert (CM_ACT408_Uebertemperatur_Cx2_reserviert), 3=Cx3_Fehler (CM_ACT408_Uebertemperatur_Cx3_Fehler)}, range raw 0..3, transfer-property=PENDING, to Klima(timeout 3.5 s)  # Anzeige einer Übertemperatur im Stellmotoren-ASIC
            signal ACT408_Elektr_Defekt_XIX_ACTs_408_Status_XIX_Klima_LIN5: start 4, 2 bit, little-endian, data-type-policy=OVERRIDE, i-signal-type=PRIMITIVE, init-value=0, base-type=BT_ACT408_Elektr_Defekt, invalid-value=Invalid_ACT408_Elektr_Defekt_XIX_ACTs_408_Status_XIX_Klima_LIN5:3, compu {0=Cx0_kein_Fehler (CM_ACT408_Elektr_Defekt_Cx0_kein_Fehler), 1=Cx1_Elektrischer_Fehler_vorhanden (CM_ACT408_Elektr_Defekt_Cx1_Elektrischer_Fehler_vorhanden), 2=Cx2_Permanent_elekt_Fehler_vorhanden (CM_ACT408_Elektr_Defekt_Cx2_Permanent_elekt_Fehler_vorhanden), 3=Cx3_Fehler (CM_ACT408_Elektr_Defekt_Cx3_Fehler)}, range raw 0..3, transfer-property=PENDING, to Klima(timeout 3.5 s)  # Anzeige für einen elektrischen Fehler oder einen permanent el. Fehler im Stellmotor
            signal ACT408_Versorgungsspannung_XIX_ACTs_408_Status_XIX_Klima_LIN5: start 6, 2 bit, little-endian, data-type-policy=OVERRIDE, i-signal-type=PRIMITIVE, init-value=0, base-type=BT_ACT408_Versorgungsspannung, invalid-value=Invalid_ACT408_Versorgungsspannung_XIX_ACTs_408_Status_XIX_Klima_LIN5:3, compu {0=Cx0_Spannung_im_zulaessigen_Bereich (CM_ACT408_Versorgungsspannung_Cx0_Spannung_im_zulaessigen_Bereich), 1=Cx1_Unterspannung (CM_ACT408_Versorgungsspannung_Cx1_Unterspannung), 2=Cx2_Ueberspanung (CM_ACT408_Versorgungsspannung_Cx2_Ueberspanung), 3=Cx3_Fehler (CM_ACT408_Versorgungsspannung_Cx3_Fehler)}, range raw 0..3, transfer-property=PENDING, to Klima(timeout 3.5 s)  # Versorgungsspannung des Aktuators
            signal ACT408_Notlauf_aufgetreten_XIX_ACTs_408_Status_XIX_Klima_LIN5: start 8, 2 bit, little-endian, data-type-policy=OVERRIDE, i-signal-type=PRIMITIVE, init-value=0, base-type=BT_ACT408_Notlauf_aufgetreten, invalid-value=Invalid_ACT408_Notlauf_aufgetreten_XIX_ACTs_408_Status_XIX_Klima_LIN5:3, compu {0=Cx0_kein_Notlauf_aufgetreten (CM_ACT408_Notlauf_aufgetreten_Cx0_kein_Notlauf_aufgetreten), 1=Cx1_Notlauf_aufgetreten (CM_ACT408_Notlauf_aufgetreten_Cx1_Notlauf_aufgetreten), 2=Cx2_reserviert (CM_ACT408_Notlauf_aufgetreten_Cx2_reserviert), 3=Cx3_Fehler (CM_ACT408_Notlauf_aufgetreten_Cx3_Fehler)}, range raw 0..3, transfer-property=PENDING, to Klima(timeout 3.5 s)  # Anzeige eines aufgetretenen Notlaufs seit dem letzten Reset oder "Clear Notlauf aufgetreten"
            signal ACT408_Freigabe_Blockiererkennung_XIX_ACTs_408_Status_XIX_Klima_LIN5: start 10, 2 bit, little-endian, data-type-policy=OVERRIDE, i-signal-type=PRIMITIVE, init-value=0, base-type=BT_ACT408_Freigabe_Blockiererkennung, invalid-value=Invalid_ACT408_Freigabe_Blockiererkennung_XIX_ACTs_408_Status_XIX_Klima_LIN5:3, compu {0=Cx0_Blockiererkennung_aus (CM_ACT408_Freigabe_Blockiererkennung_Cx0_Blockiererkennung_aus), 1=Cx1_Blockiererkennung_ein (CM_ACT408_Freigabe_Blockiererkennung_Cx1_Blockiererkennung_ein), 2=Cx2_reserviert (CM_ACT408_Freigabe_Blockiererkennung_Cx2_reserviert), 3=Cx3_Fehler (CM_ACT408_Freigabe_Blockiererkennung_Cx3_Fehler)}, range raw 0..3, transfer-property=PENDING, to Klima(timeout 3.5 s)  # Aktivierung der Blockiererkennung im Aktuator
            signal ACT408_Blockierung_aufgetreten_XIX_ACTs_408_Status_XIX_Klima_LIN5: start 12, 2 bit, little-endian, data-type-policy=OVERRIDE, i-signal-type=PRIMITIVE, init-value=0, base-type=BT_ACT408_Blockierung_aufgetreten, invalid-value=Invalid_ACT408_Blockierung_aufgetreten_XIX_ACTs_408_Status_XIX_Klima_LIN5:3, compu {0=Cx0_keine_Blockierung (CM_ACT408_Blockierung_aufgetreten_Cx0_keine_Blockierung), 1=Cx1_Blockierung_erkannt (CM_ACT408_Blockierung_aufgetreten_Cx1_Blockierung_erkannt), 2=Cx2_reserviert (CM_ACT408_Blockierung_aufgetreten_Cx2_reserviert), 3=Cx3_Fehler (CM_ACT408_Blockierung_aufgetreten_Cx3_Fehler)}, range raw 0..3, transfer-property=PENDING, to Klima(timeout 3.5 s)  # Anzeige einer aufgetretenen Blockierung seit dem letzten Reset oder "Clear Blockierung aufgetreten"
            signal ACT408_Reset_XIX_ACTs_408_Status_XIX_Klima_LIN5: start 14, 2 bit, little-endian, data-type-policy=OVERRIDE, i-signal-type=PRIMITIVE, init-value=0, base-type=BT_ACT408_Reset, invalid-value=Invalid_ACT408_Reset_XIX_ACTs_408_Status_XIX_Klima_LIN5:3, compu {0=Cx0_kein_Reset (CM_ACT408_Reset_Cx0_kein_Reset), 1=Cx1_Reset_durchgefuehrt (CM_ACT408_Reset_Cx1_Reset_durchgefuehrt), 2=Cx2_reserviert (CM_ACT408_Reset_Cx2_reserviert), 3=Cx3_Fehler (CM_ACT408_Reset_Cx3_Fehler)}, range raw 0..3, transfer-property=PENDING, to Klima(timeout 3.5 s)  # Anzeige eines aufgetretenen Reset seit dem letzten ¿Clear Reset"
            signal ACT408_Spulenbestromung_XIX_ACTs_408_Status_XIX_Klima_LIN5: start 16, 2 bit, little-endian, data-type-policy=OVERRIDE, i-signal-type=PRIMITIVE, init-value=0, base-type=BT_ACT408_Spulenbestromung, invalid-value=Invalid_ACT408_Spulenbestromung_XIX_ACTs_408_Status_XIX_Klima_LIN5:3, compu {0=Cx0_Motorspulen_unbestromt (CM_ACT408_Spulenbestromung_Cx0_Motorspulen_unbestromt), 1=Cx1_Motorspulen_bestromt (CM_ACT408_Spulenbestromung_Cx1_Motorspulen_bestromt), 2=Cx2_reserviert (CM_ACT408_Spulenbestromung_Cx2_reserviert), 3=Cx3_Fehler (CM_ACT408_Spulenbestromung_Cx3_Fehler)}, range raw 0..3, transfer-property=PENDING, to Klima(timeout 3.5 s)  # Spulenbestromung im Haltezustand des Aktuators
            signal ACT408_Positionsvorgabe_Status_XIX_ACTs_408_Status_XIX_Klima_LIN5: start 18, 2 bit, little-endian, data-type-policy=OVERRIDE, i-signal-type=PRIMITIVE, init-value=0, base-type=BT_ACT408_Positionsvorgabe_Status, invalid-value=Invalid_ACT408_Positionsvorgabe_Status_XIX_ACTs_408_Status_XIX_Klima_LIN5:3, compu {0=Cx0_Soll_Position_gueltig (CM_ACT408_Positionsvorgabe_Status_Cx0_Soll_Position_gueltig), 1=Cx1_Start_Position_gueltig (CM_ACT408_Positionsvorgabe_Status_Cx1_Start_Position_gueltig), 2=Cx2_keine_Positionsvorgabe_gueltig (CM_ACT408_Positionsvorgabe_Status_Cx2_keine_Positionsvorgabe_gueltig), 3=Cx3_Fehler (CM_ACT408_Positionsvorgabe_Status_Cx3_Fehler)}, range raw 0..3, transfer-property=PENDING, to Klima(timeout 3.5 s)  # Position des Aktuators
            signal ACT408_Geschwindigkeitsstatus_XIX_ACTs_408_Status_XIX_Klima_LIN5: start 20, 4 bit, little-endian, data-type-policy=OVERRIDE, i-signal-type=PRIMITIVE, init-value=0, base-type=BT_ACT408_Geschwindigkeitsstatus, invalid-value=Invalid_ACT408_Geschwindigkeitsstatus_XIX_ACTs_408_Status_XIX_Klima_LIN5:15, compu {0=Cx0_Motor_steht (CM_ACT408_Geschwindigkeitsstatus_Cx0_Motor_steht), 1=Cx1_Geschwindigkeitsstufe_1 (CM_ACT408_Geschwindigkeitsstatus_Cx1_Geschwindigkeitsstufe_1), 2=Cx2_Geschwindigkeitsstufe_2 (CM_ACT408_Geschwindigkeitsstatus_Cx2_Geschwindigkeitsstufe_2), 3=Cx3_Geschwindigkeitsstufe_3 (CM_ACT408_Geschwindigkeitsstatus_Cx3_Geschwindigkeitsstufe_3), 4=Cx4_Geschwindigkeitsstufe_4 (CM_ACT408_Geschwindigkeitsstatus_Cx4_Geschwindigkeitsstufe_4), 5=Cx5_Autospeed (CM_ACT408_Geschwindigkeitsstatus_Cx5_Autospeed), 15=Cxf_Fehler (CM_ACT408_Geschwindigkeitsstatus_Cxf_Fehler)}, range raw 0..15, transfer-property=PENDING, to Klima(timeout 3.5 s)  # Geschwindigkeitsstufe mit der die aktuelle Verfahrbewegung durchgeführt wird
            signal ACT408_Ist_Position_Aktuator_XIX_ACTs_408_Status_XIX_Klima_LIN5: start 24, 16 bit, little-endian, data-type-policy=OVERRIDE, i-signal-type=PRIMITIVE, init-value=32767, base-type=BT_ACT408_Ist_Position_Aktuator, invalid-value=Invalid_ACT408_Ist_Position_Aktuator_XIX_ACTs_408_Status_XIX_Klima_LIN5:65535, compu {phys=raw for raw 0..65534, 32767=Cx7fff_Init (CM_ACT408_Ist_Position_Aktuator_Cx7fff_Init), 65535=Cxffff_Fehler (CM_ACT408_Ist_Position_Aktuator_Cxffff_Fehler); unit Unit_None}, range phys 0..65534 Unit_None, raw 0..65535, unit=Unit_None, transfer-property=PENDING, to Klima(timeout 3.5 s)  # IST-Position des Aktuators
            signal ACT408_Verfahrrichtung_XIX_ACTs_408_Status_XIX_Klima_LIN5: start 40, 2 bit, little-endian, data-type-policy=OVERRIDE, i-signal-type=PRIMITIVE, init-value=2, base-type=BT_ACT408_Verfahrrichtung, invalid-value=Invalid_ACT408_Verfahrrichtung_XIX_ACTs_408_Status_XIX_Klima_LIN5:3, compu {0=Cx0_Richtung_kl_Schrittpositionen (CM_ACT408_Verfahrrichtung_Cx0_Richtung_kl_Schrittpositionen), 1=Cx1_Richtung_gr_Schrittpositionen (CM_ACT408_Verfahrrichtung_Cx1_Richtung_gr_Schrittpositionen), 2=Cx2_Init (CM_ACT408_Verfahrrichtung_Cx2_Init), 3=Cx3_Fehler (CM_ACT408_Verfahrrichtung_Cx3_Fehler)}, range raw 0..3, transfer-property=PENDING, to Klima(timeout 3.5 s)  # Verfahrrichtung der aktuellen oder zuletzt stattgefundenen Bewegung des Aktuators
            signal ACT408_Selbsthaltemoment_XIX_ACTs_408_Status_XIX_Klima_LIN5: start 42, 2 bit, little-endian, data-type-policy=OVERRIDE, i-signal-type=PRIMITIVE, init-value=0, base-type=BT_ACT408_Selbsthaltemoment, invalid-value=Invalid_ACT408_Selbsthaltemoment_XIX_ACTs_408_Status_XIX_Klima_LIN5:3, compu {0=Cx0_ohne_Selbsthaltemoment (CM_ACT408_Selbsthaltemoment_Cx0_ohne_Selbsthaltemoment), 1=Cx1_mit_Selbsthaltemoment (CM_ACT408_Selbsthaltemoment_Cx1_mit_Selbsthaltemoment), 2=Cx2_reserviert (CM_ACT408_Selbsthaltemoment_Cx2_reserviert), 3=Cx3_Fehler (CM_ACT408_Selbsthaltemoment_Cx3_Fehler)}, range raw 0..3, transfer-property=PENDING, to Klima(timeout 3.5 s)  # Das Signal gibt an ob ein selbsthemmendes Getriebe verbaut ist oder die SHB eingeschaltet ist
            signal ACT408_Sonderfunktionen_XIX_ACTs_408_Status_XIX_Klima_LIN5: start 44, 2 bit, little-endian, data-type-policy=OVERRIDE, i-signal-type=PRIMITIVE, init-value=0, base-type=BT_ACT408_Sonderfunktionen, invalid-value=Invalid_ACT408_Sonderfunktionen_XIX_ACTs_408_Status_XIX_Klima_LIN5:3, compu {0=Cx0_Keine_Sonderfunktion_aktiv (CM_ACT408_Sonderfunktionen_Cx0_Keine_Sonderfunktion_aktiv), 1=Cx1_Sonderfunktion1_aktiv (CM_ACT408_Sonderfunktionen_Cx1_Sonderfunktion1_aktiv), 2=Cx2_Sonderfunktion2_aktiv (CM_ACT408_Sonderfunktionen_Cx2_Sonderfunktion2_aktiv), 3=Cx3_Fehler (CM_ACT408_Sonderfunktionen_Cx3_Fehler)}, range raw 0..3, transfer-property=PENDING, to Klima(timeout 3.5 s)  # Funktionen des Aktuators
            signal ACT408_Variante_XIX_ACTs_408_Status_XIX_Klima_LIN5: start 46, 2 bit, little-endian, data-type-policy=OVERRIDE, i-signal-type=PRIMITIVE, init-value=0, base-type=BT_ACT408_Variante, compu {0=Cx0_Variante_1 (CM_ACT408_Variante_Cx0_Variante_1), 1=Cx1_Variante_2 (CM_ACT408_Variante_Cx1_Variante_2), 2=Cx2_Variante_3 (CM_ACT408_Variante_Cx2_Variante_3), 3=Cx3_Fehler_oder_nicht_umgesetzt (CM_ACT408_Variante_Cx3_Fehler_oder_nicht_umgesetzt)}, range raw 0..3, transfer-property=PENDING, to Klima(timeout 3.5 s)  # Das Signal gibt an welche Variante des Stellmotors verbaut ist
            signal ACT408_Adresse_Aktuator_XIX_ACTs_408_Status_XIX_Klima_LIN5: start 48, 8 bit, little-endian, data-type-policy=OVERRIDE, i-signal-type=PRIMITIVE, init-value=255, base-type=BT_ACT408_Adresse_Aktuator, compu {255=Cxff_Init (CM_ACT408_Adresse_Aktuator_Cxff_Init)}, range raw 255, transfer-property=PENDING, to Klima(timeout 3.5 s)  # Adresse Aktuator
            signal ACT408_Notlauffreigabe_XIX_ACTs_408_Status_XIX_Klima_LIN5: start 56, 2 bit, little-endian, data-type-policy=OVERRIDE, i-signal-type=PRIMITIVE, init-value=0, base-type=BT_ACT408_Notlauffreigabe, invalid-value=Invalid_ACT408_Notlauffreigabe_XIX_ACTs_408_Status_XIX_Klima_LIN5:3, compu {0=Cx0_Notlauf_aus (CM_ACT408_Notlauffreigabe_Cx0_Notlauf_aus), 1=Cx1_Notlauf_ein (CM_ACT408_Notlauffreigabe_Cx1_Notlauf_ein), 2=Cx2_reserviert (CM_ACT408_Notlauffreigabe_Cx2_reserviert), 3=Cx3_Fehler (CM_ACT408_Notlauffreigabe_Cx3_Fehler)}, range raw 0..3, transfer-property=PENDING, to Klima(timeout 3.5 s)  # Freigabe der Notlauffunktion des Aktuators
            signal ACT408_Notlaufposition_XIX_ACTs_408_Status_XIX_Klima_LIN5: start 58, 2 bit, little-endian, data-type-policy=OVERRIDE, i-signal-type=PRIMITIVE, init-value=0, base-type=BT_ACT408_Notlaufposition, invalid-value=Invalid_ACT408_Notlaufposition_XIX_ACTs_408_Status_XIX_Klima_LIN5:3, compu {0=Cx0_unterer_Anschlag (CM_ACT408_Notlaufposition_Cx0_unterer_Anschlag), 1=Cx1_oberer_Anschlag (CM_ACT408_Notlaufposition_Cx1_oberer_Anschlag), 2=Cx2_reserviert (CM_ACT408_Notlaufposition_Cx2_reserviert), 3=Cx3_Fehler (CM_ACT408_Notlaufposition_Cx3_Fehler)}, range raw 0..3, transfer-property=PENDING, to Klima(timeout 3.5 s)  # Positionsvorgabe des Aktuators
            signal ACT408_Drehrichtung_XIX_ACTs_408_Status_XIX_Klima_LIN5: start 60, 2 bit, little-endian, data-type-policy=OVERRIDE, i-signal-type=PRIMITIVE, init-value=0, base-type=BT_ACT408_Drehrichtung, invalid-value=Invalid_ACT408_Drehrichtung_XIX_ACTs_408_Status_XIX_Klima_LIN5:3, compu {0=Cx0_Bewegung_in_Richtung_CW (CM_ACT408_Drehrichtung_Cx0_Bewegung_in_Richtung_CW), 1=Cx1_Bewegung_in_Richtung_CCW (CM_ACT408_Drehrichtung_Cx1_Bewegung_in_Richtung_CCW), 2=Cx2_reserviert (CM_ACT408_Drehrichtung_Cx2_reserviert), 3=Cx3_Fehler (CM_ACT408_Drehrichtung_Cx3_Fehler)}, range raw 0..3, transfer-property=PENDING, to Klima(timeout 3.5 s)  # Drehrichtung des Aktuators
            signal ACT408_Stopmodus_XIX_ACTs_408_Status_XIX_Klima_LIN5: start 62, 2 bit, little-endian, data-type-policy=OVERRIDE, i-signal-type=PRIMITIVE, init-value=0, base-type=BT_ACT408_Stopmodus, invalid-value=Invalid_ACT408_Stopmodus_XIX_ACTs_408_Status_XIX_Klima_LIN5:3, compu {0=Cx0_Normal_Mode (CM_ACT408_Stopmodus_Cx0_Normal_Mode), 1=Cx1_Stop_Mode (CM_ACT408_Stopmodus_Cx1_Stop_Mode), 2=Cx2_reserviert (CM_ACT408_Stopmodus_Cx2_reserviert), 3=Cx3_Fehler (CM_ACT408_Stopmodus_Cx3_Fehler)}, range raw 0..3, transfer-property=PENDING, to Klima(timeout 3.5 s)  # Modus des Aktuators
        frame ACTs_409_Status_XIX_Klima_LIN5: id 0x26, to Klima, frame-length=8, lin-checksum=ENHANCED
          pdu ACTs_409_Status_XIX_Klima_LIN5: length=8, unused-bit-pattern=0
            signal ACT409_ResponseError_XIX_ACTs_409_Status_XIX_Klima_LIN5: start 0, 1 bit, little-endian, data-type-policy=OVERRIDE, i-signal-type=PRIMITIVE, init-value=0, base-type=BT_ACT409_ResponseError, invalid-value=Invalid_ACT409_ResponseError_XIX_ACTs_409_Status_XIX_Klima_LIN5:1, compu {0=Cx0_normal (CM_ACT409_ResponseError_Cx0_normal), 1=Cx1_Fehler (CM_ACT409_ResponseError_Cx1_Fehler)}, range raw 0..1, transfer-property=PENDING, to Klima(timeout 3.5 s)  # siehe LIN2.0-Specification (Darf nicht über ein Fehlergueltigkeitsbit abgesichtert werden!)
            signal ACT409_Uebertemperatur_XIX_ACTs_409_Status_XIX_Klima_LIN5: start 2, 2 bit, little-endian, data-type-policy=OVERRIDE, i-signal-type=PRIMITIVE, init-value=0, base-type=BT_ACT409_Uebertemperatur, invalid-value=Invalid_ACT409_Uebertemperatur_XIX_ACTs_409_Status_XIX_Klima_LIN5:3, compu {0=Cx0_keine_Uebertemperatur (CM_ACT409_Uebertemperatur_Cx0_keine_Uebertemperatur), 1=Cx1_Uebertemperatur (CM_ACT409_Uebertemperatur_Cx1_Uebertemperatur), 2=Cx2_reserviert (CM_ACT409_Uebertemperatur_Cx2_reserviert), 3=Cx3_Fehler (CM_ACT409_Uebertemperatur_Cx3_Fehler)}, range raw 0..3, transfer-property=PENDING, to Klima(timeout 3.5 s)  # Anzeige einer Übertemperatur im Stellmotoren-ASIC
            signal ACT409_Elektr_Defekt_XIX_ACTs_409_Status_XIX_Klima_LIN5: start 4, 2 bit, little-endian, data-type-policy=OVERRIDE, i-signal-type=PRIMITIVE, init-value=0, base-type=BT_ACT409_Elektr_Defekt, invalid-value=Invalid_ACT409_Elektr_Defekt_XIX_ACTs_409_Status_XIX_Klima_LIN5:3, compu {0=Cx0_kein_Fehler (CM_ACT409_Elektr_Defekt_Cx0_kein_Fehler), 1=Cx1_Elektrischer_Fehler_vorhanden (CM_ACT409_Elektr_Defekt_Cx1_Elektrischer_Fehler_vorhanden), 2=Cx2_Permanent_elekt_Fehler_vorhanden (CM_ACT409_Elektr_Defekt_Cx2_Permanent_elekt_Fehler_vorhanden), 3=Cx3_Fehler (CM_ACT409_Elektr_Defekt_Cx3_Fehler)}, range raw 0..3, transfer-property=PENDING, to Klima(timeout 3.5 s)  # Anzeige für einen elektrischen Fehler oder einen permanent el. Fehler im Stellmotor
            signal ACT409_Versorgungsspannung_XIX_ACTs_409_Status_XIX_Klima_LIN5: start 6, 2 bit, little-endian, data-type-policy=OVERRIDE, i-signal-type=PRIMITIVE, init-value=0, base-type=BT_ACT409_Versorgungsspannung, invalid-value=Invalid_ACT409_Versorgungsspannung_XIX_ACTs_409_Status_XIX_Klima_LIN5:3, compu {0=Cx0_Spannung_im_zulaessigen_Bereich (CM_ACT409_Versorgungsspannung_Cx0_Spannung_im_zulaessigen_Bereich), 1=Cx1_Unterspannung (CM_ACT409_Versorgungsspannung_Cx1_Unterspannung), 2=Cx2_Ueberspanung (CM_ACT409_Versorgungsspannung_Cx2_Ueberspanung), 3=Cx3_Fehler (CM_ACT409_Versorgungsspannung_Cx3_Fehler)}, range raw 0..3, transfer-property=PENDING, to Klima(timeout 3.5 s)  # Versorgungsspannung des Aktuators
            signal ACT409_Notlauf_aufgetreten_XIX_ACTs_409_Status_XIX_Klima_LIN5: start 8, 2 bit, little-endian, data-type-policy=OVERRIDE, i-signal-type=PRIMITIVE, init-value=0, base-type=BT_ACT409_Notlauf_aufgetreten, invalid-value=Invalid_ACT409_Notlauf_aufgetreten_XIX_ACTs_409_Status_XIX_Klima_LIN5:3, compu {0=Cx0_kein_Notlauf_aufgetreten (CM_ACT409_Notlauf_aufgetreten_Cx0_kein_Notlauf_aufgetreten), 1=Cx1_Notlauf_aufgetreten (CM_ACT409_Notlauf_aufgetreten_Cx1_Notlauf_aufgetreten), 2=Cx2_reserviert (CM_ACT409_Notlauf_aufgetreten_Cx2_reserviert), 3=Cx3_Fehler (CM_ACT409_Notlauf_aufgetreten_Cx3_Fehler)}, range raw 0..3, transfer-property=PENDING, to Klima(timeout 3.5 s)  # Anzeige eines aufgetretenen Notlaufs seit dem letzten Reset oder "Clear Notlauf aufgetreten"
            signal ACT409_Freigabe_Blockiererkennung_XIX_ACTs_409_Status_XIX_Klima_LIN5: start 10, 2 bit, little-endian, data-type-policy=OVERRIDE, i-signal-type=PRIMITIVE, init-value=0, base-type=BT_ACT409_Freigabe_Blockiererkennung, invalid-value=Invalid_ACT409_Freigabe_Blockiererkennung_XIX_ACTs_409_Status_XIX_Klima_LIN5:3, compu {0=Cx0_Blockiererkennung_aus (CM_ACT409_Freigabe_Blockiererkennung_Cx0_Blockiererkennung_aus), 1=Cx1_Blockiererkennung_ein (CM_ACT409_Freigabe_Blockiererkennung_Cx1_Blockiererkennung_ein), 2=Cx2_reserviert (CM_ACT409_Freigabe_Blockiererkennung_Cx2_reserviert), 3=Cx3_Fehler (CM_ACT409_Freigabe_Blockiererkennung_Cx3_Fehler)}, range raw 0..3, transfer-property=PENDING, to Klima(timeout 3.5 s)  # Aktivierung der Blockiererkennung im Aktuator
            signal ACT409_Blockierung_aufgetreten_XIX_ACTs_409_Status_XIX_Klima_LIN5: start 12, 2 bit, little-endian, data-type-policy=OVERRIDE, i-signal-type=PRIMITIVE, init-value=0, base-type=BT_ACT409_Blockierung_aufgetreten, invalid-value=Invalid_ACT409_Blockierung_aufgetreten_XIX_ACTs_409_Status_XIX_Klima_LIN5:3, compu {0=Cx0_keine_Blockierung (CM_ACT409_Blockierung_aufgetreten_Cx0_keine_Blockierung), 1=Cx1_Blockierung_erkannt (CM_ACT409_Blockierung_aufgetreten_Cx1_Blockierung_erkannt), 2=Cx2_reserviert (CM_ACT409_Blockierung_aufgetreten_Cx2_reserviert), 3=Cx3_Fehler (CM_ACT409_Blockierung_aufgetreten_Cx3_Fehler)}, range raw 0..3, transfer-property=PENDING, to Klima(timeout 3.5 s)  # Anzeige einer aufgetretenen Blockierung seit dem letzten Reset oder "Clear Blockierung aufgetreten"
            signal ACT409_Reset_XIX_ACTs_409_Status_XIX_Klima_LIN5: start 14, 2 bit, little-endian, data-type-policy=OVERRIDE, i-signal-type=PRIMITIVE, init-value=0, base-type=BT_ACT409_Reset, invalid-value=Invalid_ACT409_Reset_XIX_ACTs_409_Status_XIX_Klima_LIN5:3, compu {0=Cx0_kein_Reset (CM_ACT409_Reset_Cx0_kein_Reset), 1=Cx1_Reset_durchgefuehrt (CM_ACT409_Reset_Cx1_Reset_durchgefuehrt), 2=Cx2_reserviert (CM_ACT409_Reset_Cx2_reserviert), 3=Cx3_Fehler (CM_ACT409_Reset_Cx3_Fehler)}, range raw 0..3, transfer-property=PENDING, to Klima(timeout 3.5 s)  # Anzeige eines aufgetretenen Reset seit dem letzten ¿Clear Reset"
            signal ACT409_Spulenbestromung_XIX_ACTs_409_Status_XIX_Klima_LIN5: start 16, 2 bit, little-endian, data-type-policy=OVERRIDE, i-signal-type=PRIMITIVE, init-value=0, base-type=BT_ACT409_Spulenbestromung, invalid-value=Invalid_ACT409_Spulenbestromung_XIX_ACTs_409_Status_XIX_Klima_LIN5:3, compu {0=Cx0_Motorspulen_unbestromt (CM_ACT409_Spulenbestromung_Cx0_Motorspulen_unbestromt), 1=Cx1_Motorspulen_bestromt (CM_ACT409_Spulenbestromung_Cx1_Motorspulen_bestromt), 2=Cx2_reserviert (CM_ACT409_Spulenbestromung_Cx2_reserviert), 3=Cx3_Fehler (CM_ACT409_Spulenbestromung_Cx3_Fehler)}, range raw 0..3, transfer-property=PENDING, to Klima(timeout 3.5 s)  # Spulenbestromung im Haltezustand des Aktuators
            signal ACT409_Positionsvorgabe_Status_XIX_ACTs_409_Status_XIX_Klima_LIN5: start 18, 2 bit, little-endian, data-type-policy=OVERRIDE, i-signal-type=PRIMITIVE, init-value=0, base-type=BT_ACT409_Positionsvorgabe_Status, invalid-value=Invalid_ACT409_Positionsvorgabe_Status_XIX_ACTs_409_Status_XIX_Klima_LIN5:3, compu {0=Cx0_Soll_Position_gueltig (CM_ACT409_Positionsvorgabe_Status_Cx0_Soll_Position_gueltig), 1=Cx1_Start_Position_gueltig (CM_ACT409_Positionsvorgabe_Status_Cx1_Start_Position_gueltig), 2=Cx2_keine_Positionsvorgabe_gueltig (CM_ACT409_Positionsvorgabe_Status_Cx2_keine_Positionsvorgabe_gueltig), 3=Cx3_Fehler (CM_ACT409_Positionsvorgabe_Status_Cx3_Fehler)}, range raw 0..3, transfer-property=PENDING, to Klima(timeout 3.5 s)  # Position des Aktuators
            signal ACT409_Geschwindigkeitsstatus_XIX_ACTs_409_Status_XIX_Klima_LIN5: start 20, 4 bit, little-endian, data-type-policy=OVERRIDE, i-signal-type=PRIMITIVE, init-value=0, base-type=BT_ACT409_Geschwindigkeitsstatus, invalid-value=Invalid_ACT409_Geschwindigkeitsstatus_XIX_ACTs_409_Status_XIX_Klima_LIN5:15, compu {0=Cx0_Motor_steht (CM_ACT409_Geschwindigkeitsstatus_Cx0_Motor_steht), 1=Cx1_Geschwindigkeitsstufe_1 (CM_ACT409_Geschwindigkeitsstatus_Cx1_Geschwindigkeitsstufe_1), 2=Cx2_Geschwindigkeitsstufe_2 (CM_ACT409_Geschwindigkeitsstatus_Cx2_Geschwindigkeitsstufe_2), 3=Cx3_Geschwindigkeitsstufe_3 (CM_ACT409_Geschwindigkeitsstatus_Cx3_Geschwindigkeitsstufe_3), 4=Cx4_Geschwindigkeitsstufe_4 (CM_ACT409_Geschwindigkeitsstatus_Cx4_Geschwindigkeitsstufe_4), 5=Cx5_Autospeed (CM_ACT409_Geschwindigkeitsstatus_Cx5_Autospeed), 15=Cxf_Fehler (CM_ACT409_Geschwindigkeitsstatus_Cxf_Fehler)}, range raw 0..15, transfer-property=PENDING, to Klima(timeout 3.5 s)  # Geschwindigkeitsstufe mit der die aktuelle Verfahrbewegung durchgeführt wird
            signal ACT409_Ist_Position_Aktuator_XIX_ACTs_409_Status_XIX_Klima_LIN5: start 24, 16 bit, little-endian, data-type-policy=OVERRIDE, i-signal-type=PRIMITIVE, init-value=32767, base-type=BT_ACT409_Ist_Position_Aktuator, invalid-value=Invalid_ACT409_Ist_Position_Aktuator_XIX_ACTs_409_Status_XIX_Klima_LIN5:65535, compu {phys=raw for raw 0..65534, 65535=Cxffff_Fehler (CM_ACT409_Ist_Position_Aktuator_Cxffff_Fehler); unit Unit_None}, range phys 0..65534 Unit_None, raw 0..65535, unit=Unit_None, transfer-property=PENDING, to Klima(timeout 3.5 s)  # IST-Position des Aktuators
            signal ACT409_Verfahrrichtung_XIX_ACTs_409_Status_XIX_Klima_LIN5: start 40, 2 bit, little-endian, data-type-policy=OVERRIDE, i-signal-type=PRIMITIVE, init-value=2, base-type=BT_ACT409_Verfahrrichtung, invalid-value=Invalid_ACT409_Verfahrrichtung_XIX_ACTs_409_Status_XIX_Klima_LIN5:3, compu {0=Cx0_Richtung_kl_Schrittpositionen (CM_ACT409_Verfahrrichtung_Cx0_Richtung_kl_Schrittpositionen), 1=Cx1_Richtung_gr_Schrittpositionen (CM_ACT409_Verfahrrichtung_Cx1_Richtung_gr_Schrittpositionen), 2=Cx2_Init (CM_ACT409_Verfahrrichtung_Cx2_Init), 3=Cx3_Fehler (CM_ACT409_Verfahrrichtung_Cx3_Fehler)}, range raw 0..3, transfer-property=PENDING, to Klima(timeout 3.5 s)  # Verfahrrichtung der aktuellen oder zuletzt stattgefundenen Bewegung des Aktuators
            signal ACT409_Selbsthaltemoment_XIX_ACTs_409_Status_XIX_Klima_LIN5: start 42, 2 bit, little-endian, data-type-policy=OVERRIDE, i-signal-type=PRIMITIVE, init-value=0, base-type=BT_ACT409_Selbsthaltemoment, invalid-value=Invalid_ACT409_Selbsthaltemoment_XIX_ACTs_409_Status_XIX_Klima_LIN5:3, compu {0=Cx0_ohne_Selbsthaltemoment (CM_ACT409_Selbsthaltemoment_Cx0_ohne_Selbsthaltemoment), 1=Cx1_mit_Selbsthaltemoment (CM_ACT409_Selbsthaltemoment_Cx1_mit_Selbsthaltemoment), 2=Cx2_reserviert (CM_ACT409_Selbsthaltemoment_Cx2_reserviert), 3=Cx3_Fehler (CM_ACT409_Selbsthaltemoment_Cx3_Fehler)}, range raw 0..3, transfer-property=PENDING, to Klima(timeout 3.5 s)  # Das Signal gibt an ob ein selbsthemmendes Getriebe verbaut ist oder die SHB eingeschaltet ist
            signal ACT409_Sonderfunktionen_XIX_ACTs_409_Status_XIX_Klima_LIN5: start 44, 2 bit, little-endian, data-type-policy=OVERRIDE, i-signal-type=PRIMITIVE, init-value=0, base-type=BT_ACT409_Sonderfunktionen, invalid-value=Invalid_ACT409_Sonderfunktionen_XIX_ACTs_409_Status_XIX_Klima_LIN5:3, compu {0=Cx0_Keine_Sonderfunktion_aktiv (CM_ACT409_Sonderfunktionen_Cx0_Keine_Sonderfunktion_aktiv), 1=Cx1_Sonderfunktion1_aktiv (CM_ACT409_Sonderfunktionen_Cx1_Sonderfunktion1_aktiv), 2=Cx2_Sonderfunktion2_aktiv (CM_ACT409_Sonderfunktionen_Cx2_Sonderfunktion2_aktiv), 3=Cx3_Fehler (CM_ACT409_Sonderfunktionen_Cx3_Fehler)}, range raw 0..3, transfer-property=PENDING, to Klima(timeout 3.5 s)  # Funktionen des Aktuators
            signal ACT409_Variante_XIX_ACTs_409_Status_XIX_Klima_LIN5: start 46, 2 bit, little-endian, data-type-policy=OVERRIDE, i-signal-type=PRIMITIVE, init-value=0, base-type=BT_ACT409_Variante, compu {0=Cx0_Variante_1 (CM_ACT409_Variante_Cx0_Variante_1), 1=Cx1_Variante_2 (CM_ACT409_Variante_Cx1_Variante_2), 2=Cx2_Variante_3 (CM_ACT409_Variante_Cx2_Variante_3), 3=Cx3_Fehler_oder_nicht_umgesetzt (CM_ACT409_Variante_Cx3_Fehler_oder_nicht_umgesetzt)}, range raw 0..3, transfer-property=PENDING, to Klima(timeout 3.5 s)  # Das Signal gibt an welche Variante des Stellmotors verbaut ist
            signal ACT409_Adresse_Aktuator_XIX_ACTs_409_Status_XIX_Klima_LIN5: start 48, 8 bit, little-endian, data-type-policy=OVERRIDE, i-signal-type=PRIMITIVE, init-value=255, base-type=BT_ACT409_Adresse_Aktuator, compu {255=Cxff_Init (CM_ACT409_Adresse_Aktuator_Cxff_Init)}, range raw 255, transfer-property=PENDING, to Klima(timeout 3.5 s)  # Adresse Aktuator
            signal ACT409_Notlauffreigabe_XIX_ACTs_409_Status_XIX_Klima_LIN5: start 56, 2 bit, little-endian, data-type-policy=OVERRIDE, i-signal-type=PRIMITIVE, init-value=0, base-type=BT_ACT409_Notlauffreigabe, invalid-value=Invalid_ACT409_Notlauffreigabe_XIX_ACTs_409_Status_XIX_Klima_LIN5:3, compu {0=Cx0_Notlauf_aus (CM_ACT409_Notlauffreigabe_Cx0_Notlauf_aus), 1=Cx1_Notlauf_ein (CM_ACT409_Notlauffreigabe_Cx1_Notlauf_ein), 2=Cx2_reserviert (CM_ACT409_Notlauffreigabe_Cx2_reserviert), 3=Cx3_Fehler (CM_ACT409_Notlauffreigabe_Cx3_Fehler)}, range raw 0..3, transfer-property=PENDING, to Klima(timeout 3.5 s)  # Freigabe der Notlauffunktion des Aktuators
            signal ACT409_Notlaufposition_XIX_ACTs_409_Status_XIX_Klima_LIN5: start 58, 2 bit, little-endian, data-type-policy=OVERRIDE, i-signal-type=PRIMITIVE, init-value=0, base-type=BT_ACT409_Notlaufposition, invalid-value=Invalid_ACT409_Notlaufposition_XIX_ACTs_409_Status_XIX_Klima_LIN5:3, compu {0=Cx0_unterer_Anschlag (CM_ACT409_Notlaufposition_Cx0_unterer_Anschlag), 1=Cx1_oberer_Anschlag (CM_ACT409_Notlaufposition_Cx1_oberer_Anschlag), 2=Cx2_reserviert (CM_ACT409_Notlaufposition_Cx2_reserviert), 3=Cx3_Fehler (CM_ACT409_Notlaufposition_Cx3_Fehler)}, range raw 0..3, transfer-property=PENDING, to Klima(timeout 3.5 s)  # Positionsvorgabe des Aktuators
            signal ACT409_Drehrichtung_XIX_ACTs_409_Status_XIX_Klima_LIN5: start 60, 2 bit, little-endian, data-type-policy=OVERRIDE, i-signal-type=PRIMITIVE, init-value=0, base-type=BT_ACT409_Drehrichtung, invalid-value=Invalid_ACT409_Drehrichtung_XIX_ACTs_409_Status_XIX_Klima_LIN5:3, compu {0=Cx0_Bewegung_in_Richtung_CW (CM_ACT409_Drehrichtung_Cx0_Bewegung_in_Richtung_CW), 1=Cx1_Bewegung_in_Richtung_CCW (CM_ACT409_Drehrichtung_Cx1_Bewegung_in_Richtung_CCW), 2=Cx2_reserviert (CM_ACT409_Drehrichtung_Cx2_reserviert), 3=Cx3_Fehler (CM_ACT409_Drehrichtung_Cx3_Fehler)}, range raw 0..3, transfer-property=PENDING, to Klima(timeout 3.5 s)  # Drehrichtung des Aktuators
            signal ACT409_Stopmodus_XIX_ACTs_409_Status_XIX_Klima_LIN5: start 62, 2 bit, little-endian, data-type-policy=OVERRIDE, i-signal-type=PRIMITIVE, init-value=0, base-type=BT_ACT409_Stopmodus, invalid-value=Invalid_ACT409_Stopmodus_XIX_ACTs_409_Status_XIX_Klima_LIN5:3, compu {0=Cx0_Normal_Mode (CM_ACT409_Stopmodus_Cx0_Normal_Mode), 1=Cx1_Stop_Mode (CM_ACT409_Stopmodus_Cx1_Stop_Mode), 2=Cx2_reserviert (CM_ACT409_Stopmodus_Cx2_reserviert), 3=Cx3_Fehler (CM_ACT409_Stopmodus_Cx3_Fehler)}, range raw 0..3, transfer-property=PENDING, to Klima(timeout 3.5 s)  # Modus des Aktuators
        frame ACTs_410_Status_XIX_Klima_LIN5: id 0x29, to Klima, frame-length=8, lin-checksum=ENHANCED
          pdu ACTs_410_Status_XIX_Klima_LIN5: length=8, unused-bit-pattern=0
            signal ACT410_ResponseError_XIX_ACTs_410_Status_XIX_Klima_LIN5: start 0, 1 bit, little-endian, data-type-policy=OVERRIDE, i-signal-type=PRIMITIVE, init-value=0, base-type=BT_ACT410_ResponseError, invalid-value=Invalid_ACT410_ResponseError_XIX_ACTs_410_Status_XIX_Klima_LIN5:1, compu {0=Cx0_normal (CM_ACT410_ResponseError_Cx0_normal), 1=Cx1_Fehler (CM_ACT410_ResponseError_Cx1_Fehler)}, range raw 0..1, transfer-property=PENDING, to Klima(timeout 3.5 s)  # siehe LIN2.0-Specification (Darf nicht über ein Fehlergueltigkeitsbit abgesichtert werden!)
            signal ACT410_Uebertemperatur_XIX_ACTs_410_Status_XIX_Klima_LIN5: start 2, 2 bit, little-endian, data-type-policy=OVERRIDE, i-signal-type=PRIMITIVE, init-value=0, base-type=BT_ACT410_Uebertemperatur, invalid-value=Invalid_ACT410_Uebertemperatur_XIX_ACTs_410_Status_XIX_Klima_LIN5:3, compu {0=Cx0_keine_Uebertemperatur (CM_ACT410_Uebertemperatur_Cx0_keine_Uebertemperatur), 1=Cx1_Uebertemperatur (CM_ACT410_Uebertemperatur_Cx1_Uebertemperatur), 2=Cx2_reserviert (CM_ACT410_Uebertemperatur_Cx2_reserviert), 3=Cx3_Fehler (CM_ACT410_Uebertemperatur_Cx3_Fehler)}, range raw 0..3, transfer-property=PENDING, to Klima(timeout 3.5 s)  # Anzeige einer Übertemperatur im Stellmotoren-ASIC
            signal ACT410_Elektr_Defekt_XIX_ACTs_410_Status_XIX_Klima_LIN5: start 4, 2 bit, little-endian, data-type-policy=OVERRIDE, i-signal-type=PRIMITIVE, init-value=0, base-type=BT_ACT410_Elektr_Defekt, invalid-value=Invalid_ACT410_Elektr_Defekt_XIX_ACTs_410_Status_XIX_Klima_LIN5:3, compu {0=Cx0_kein_Fehler (CM_ACT410_Elektr_Defekt_Cx0_kein_Fehler), 1=Cx1_Elektrischer_Fehler_vorhanden (CM_ACT410_Elektr_Defekt_Cx1_Elektrischer_Fehler_vorhanden), 2=Cx2_Permanent_elekt_Fehler_vorhanden (CM_ACT410_Elektr_Defekt_Cx2_Permanent_elekt_Fehler_vorhanden), 3=Cx3_Fehler (CM_ACT410_Elektr_Defekt_Cx3_Fehler)}, range raw 0..3, transfer-property=PENDING, to Klima(timeout 3.5 s)  # Anzeige für einen elektrischen Fehler oder einen permanent el. Fehler im Stellmotor
            signal ACT410_Versorgungsspannung_XIX_ACTs_410_Status_XIX_Klima_LIN5: start 6, 2 bit, little-endian, data-type-policy=OVERRIDE, i-signal-type=PRIMITIVE, init-value=0, base-type=BT_ACT410_Versorgungsspannung, invalid-value=Invalid_ACT410_Versorgungsspannung_XIX_ACTs_410_Status_XIX_Klima_LIN5:3, compu {0=Cx0_Spannung_im_zulaessigen_Bereich (CM_ACT410_Versorgungsspannung_Cx0_Spannung_im_zulaessigen_Bereich), 1=Cx1_Unterspannung (CM_ACT410_Versorgungsspannung_Cx1_Unterspannung), 2=Cx2_Ueberspanung (CM_ACT410_Versorgungsspannung_Cx2_Ueberspanung), 3=Cx3_Fehler (CM_ACT410_Versorgungsspannung_Cx3_Fehler)}, range raw 0..3, transfer-property=PENDING, to Klima(timeout 3.5 s)  # Versorgungsspannung des Aktuators
            signal ACT410_Notlauf_aufgetreten_XIX_ACTs_410_Status_XIX_Klima_LIN5: start 8, 2 bit, little-endian, data-type-policy=OVERRIDE, i-signal-type=PRIMITIVE, init-value=0, base-type=BT_ACT410_Notlauf_aufgetreten, invalid-value=Invalid_ACT410_Notlauf_aufgetreten_XIX_ACTs_410_Status_XIX_Klima_LIN5:3, compu {0=Cx0_kein_Notlauf_aufgetreten (CM_ACT410_Notlauf_aufgetreten_Cx0_kein_Notlauf_aufgetreten), 1=Cx1_Notlauf_aufgetreten (CM_ACT410_Notlauf_aufgetreten_Cx1_Notlauf_aufgetreten), 2=Cx2_reserviert (CM_ACT410_Notlauf_aufgetreten_Cx2_reserviert), 3=Cx3_Fehler (CM_ACT410_Notlauf_aufgetreten_Cx3_Fehler)}, range raw 0..3, transfer-property=PENDING, to Klima(timeout 3.5 s)  # Anzeige eines aufgetretenen Notlaufs seit dem letzten Reset oder "Clear Notlauf aufgetreten"
            signal ACT410_Freigabe_Blockiererkennung_XIX_ACTs_410_Status_XIX_Klima_LIN5: start 10, 2 bit, little-endian, data-type-policy=OVERRIDE, i-signal-type=PRIMITIVE, init-value=0, base-type=BT_ACT410_Freigabe_Blockiererkennung, invalid-value=Invalid_ACT410_Freigabe_Blockiererkennung_XIX_ACTs_410_Status_XIX_Klima_LIN5:3, compu {0=Cx0_Blockiererkennung_aus (CM_ACT410_Freigabe_Blockiererkennung_Cx0_Blockiererkennung_aus), 1=Cx1_Blockiererkennung_ein (CM_ACT410_Freigabe_Blockiererkennung_Cx1_Blockiererkennung_ein), 2=Cx2_reserviert (CM_ACT410_Freigabe_Blockiererkennung_Cx2_reserviert), 3=Cx3_Fehler (CM_ACT410_Freigabe_Blockiererkennung_Cx3_Fehler)}, range raw 0..3, transfer-property=PENDING, to Klima(timeout 3.5 s)  # Aktivierung der Blockiererkennung im Aktuator
            signal ACT410_Blockierung_aufgetreten_XIX_ACTs_410_Status_XIX_Klima_LIN5: start 12, 2 bit, little-endian, data-type-policy=OVERRIDE, i-signal-type=PRIMITIVE, init-value=0, base-type=BT_ACT410_Blockierung_aufgetreten, invalid-value=Invalid_ACT410_Blockierung_aufgetreten_XIX_ACTs_410_Status_XIX_Klima_LIN5:3, compu {0=Cx0_keine_Blockierung (CM_ACT410_Blockierung_aufgetreten_Cx0_keine_Blockierung), 1=Cx1_Blockierung_erkannt (CM_ACT410_Blockierung_aufgetreten_Cx1_Blockierung_erkannt), 2=Cx2_reserviert (CM_ACT410_Blockierung_aufgetreten_Cx2_reserviert), 3=Cx3_Fehler (CM_ACT410_Blockierung_aufgetreten_Cx3_Fehler)}, range raw 0..3, transfer-property=PENDING, to Klima(timeout 3.5 s)  # Anzeige einer aufgetretenen Blockierung seit dem letzten Reset oder "Clear Blockierung aufgetreten"
            signal ACT410_Reset_XIX_ACTs_410_Status_XIX_Klima_LIN5: start 14, 2 bit, little-endian, data-type-policy=OVERRIDE, i-signal-type=PRIMITIVE, init-value=0, base-type=BT_ACT410_Reset, invalid-value=Invalid_ACT410_Reset_XIX_ACTs_410_Status_XIX_Klima_LIN5:3, compu {0=Cx0_kein_Reset (CM_ACT410_Reset_Cx0_kein_Reset), 1=Cx1_Reset_durchgefuehrt (CM_ACT410_Reset_Cx1_Reset_durchgefuehrt), 2=Cx2_reserviert (CM_ACT410_Reset_Cx2_reserviert), 3=Cx3_Fehler (CM_ACT410_Reset_Cx3_Fehler)}, range raw 0..3, transfer-property=PENDING, to Klima(timeout 3.5 s)  # Anzeige eines aufgetretenen Reset seit dem letzten ¿Clear Reset"
            signal ACT410_Spulenbestromung_XIX_ACTs_410_Status_XIX_Klima_LIN5: start 16, 2 bit, little-endian, data-type-policy=OVERRIDE, i-signal-type=PRIMITIVE, init-value=0, base-type=BT_ACT410_Spulenbestromung, invalid-value=Invalid_ACT410_Spulenbestromung_XIX_ACTs_410_Status_XIX_Klima_LIN5:3, compu {0=Cx0_Motorspulen_unbestromt (CM_ACT410_Spulenbestromung_Cx0_Motorspulen_unbestromt), 1=Cx1_Motorspulen_bestromt (CM_ACT410_Spulenbestromung_Cx1_Motorspulen_bestromt), 2=Cx2_reserviert (CM_ACT410_Spulenbestromung_Cx2_reserviert), 3=Cx3_Fehler (CM_ACT410_Spulenbestromung_Cx3_Fehler)}, range raw 0..3, transfer-property=PENDING, to Klima(timeout 3.5 s)  # Spulenbestromung im Haltezustand des Aktuators
            signal ACT410_Positionsvorgabe_Status_XIX_ACTs_410_Status_XIX_Klima_LIN5: start 18, 2 bit, little-endian, data-type-policy=OVERRIDE, i-signal-type=PRIMITIVE, init-value=0, base-type=BT_ACT410_Positionsvorgabe_Status, invalid-value=Invalid_ACT410_Positionsvorgabe_Status_XIX_ACTs_410_Status_XIX_Klima_LIN5:3, compu {0=Cx0_Soll_Position_gueltig (CM_ACT410_Positionsvorgabe_Status_Cx0_Soll_Position_gueltig), 1=Cx1_Start_Position_gueltig (CM_ACT410_Positionsvorgabe_Status_Cx1_Start_Position_gueltig), 2=Cx2_keine_Positionsvorgabe_gueltig (CM_ACT410_Positionsvorgabe_Status_Cx2_keine_Positionsvorgabe_gueltig), 3=Cx3_Fehler (CM_ACT410_Positionsvorgabe_Status_Cx3_Fehler)}, range raw 0..3, transfer-property=PENDING, to Klima(timeout 3.5 s)  # Position des Aktuators
            signal ACT410_Geschwindigkeitsstatus_XIX_ACTs_410_Status_XIX_Klima_LIN5: start 20, 4 bit, little-endian, data-type-policy=OVERRIDE, i-signal-type=PRIMITIVE, init-value=0, base-type=BT_ACT410_Geschwindigkeitsstatus, invalid-value=Invalid_ACT410_Geschwindigkeitsstatus_XIX_ACTs_410_Status_XIX_Klima_LIN5:15, compu {0=Cx0_Motor_steht (CM_ACT410_Geschwindigkeitsstatus_Cx0_Motor_steht), 1=Cx1_Geschwindigkeitsstufe_1 (CM_ACT410_Geschwindigkeitsstatus_Cx1_Geschwindigkeitsstufe_1), 2=Cx2_Geschwindigkeitsstufe_2 (CM_ACT410_Geschwindigkeitsstatus_Cx2_Geschwindigkeitsstufe_2), 3=Cx3_Geschwindigkeitsstufe_3 (CM_ACT410_Geschwindigkeitsstatus_Cx3_Geschwindigkeitsstufe_3), 4=Cx4_Geschwindigkeitsstufe_4 (CM_ACT410_Geschwindigkeitsstatus_Cx4_Geschwindigkeitsstufe_4), 5=Cx5_Autospeed (CM_ACT410_Geschwindigkeitsstatus_Cx5_Autospeed), 15=Cxf_Fehler (CM_ACT410_Geschwindigkeitsstatus_Cxf_Fehler)}, range raw 0..15, transfer-property=PENDING, to Klima(timeout 3.5 s)  # Geschwindigkeitsstufe mit der die aktuelle Verfahrbewegung durchgeführt wird
            signal ACT410_Ist_Position_Aktuator_XIX_ACTs_410_Status_XIX_Klima_LIN5: start 24, 16 bit, little-endian, data-type-policy=OVERRIDE, i-signal-type=PRIMITIVE, init-value=32767, base-type=BT_ACT410_Ist_Position_Aktuator, invalid-value=Invalid_ACT410_Ist_Position_Aktuator_XIX_ACTs_410_Status_XIX_Klima_LIN5:65535, compu {phys=raw for raw 0..65534, 65535=Cxffff_Fehler (CM_ACT410_Ist_Position_Aktuator_Cxffff_Fehler); unit Unit_None}, range phys 0..65534 Unit_None, raw 0..65535, unit=Unit_None, transfer-property=PENDING, to Klima(timeout 3.5 s)  # IST-Position des Aktuators
            signal ACT410_Verfahrrichtung_XIX_ACTs_410_Status_XIX_Klima_LIN5: start 40, 2 bit, little-endian, data-type-policy=OVERRIDE, i-signal-type=PRIMITIVE, init-value=2, base-type=BT_ACT410_Verfahrrichtung, invalid-value=Invalid_ACT410_Verfahrrichtung_XIX_ACTs_410_Status_XIX_Klima_LIN5:3, compu {0=Cx0_Richtung_kl_Schrittpositionen (CM_ACT410_Verfahrrichtung_Cx0_Richtung_kl_Schrittpositionen), 1=Cx1_Richtung_gr_Schrittpositionen (CM_ACT410_Verfahrrichtung_Cx1_Richtung_gr_Schrittpositionen), 2=Cx2_Init (CM_ACT410_Verfahrrichtung_Cx2_Init), 3=Cx3_Fehler (CM_ACT410_Verfahrrichtung_Cx3_Fehler)}, range raw 0..3, transfer-property=PENDING, to Klima(timeout 3.5 s)  # Verfahrrichtung der aktuellen oder zuletzt stattgefundenen Bewegung des Aktuators
            signal ACT410_Selbsthaltemoment_XIX_ACTs_410_Status_XIX_Klima_LIN5: start 42, 2 bit, little-endian, data-type-policy=OVERRIDE, i-signal-type=PRIMITIVE, init-value=0, base-type=BT_ACT410_Selbsthaltemoment, invalid-value=Invalid_ACT410_Selbsthaltemoment_XIX_ACTs_410_Status_XIX_Klima_LIN5:3, compu {0=Cx0_ohne_Selbsthaltemoment (CM_ACT410_Selbsthaltemoment_Cx0_ohne_Selbsthaltemoment), 1=Cx1_mit_Selbsthaltemoment (CM_ACT410_Selbsthaltemoment_Cx1_mit_Selbsthaltemoment), 2=Cx2_reserviert (CM_ACT410_Selbsthaltemoment_Cx2_reserviert), 3=Cx3_Fehler (CM_ACT410_Selbsthaltemoment_Cx3_Fehler)}, range raw 0..3, transfer-property=PENDING, to Klima(timeout 3.5 s)  # Das Signal gibt an ob ein selbsthemmendes Getriebe verbaut ist oder die SHB eingeschaltet ist
            signal ACT410_Sonderfunktionen_XIX_ACTs_410_Status_XIX_Klima_LIN5: start 44, 2 bit, little-endian, data-type-policy=OVERRIDE, i-signal-type=PRIMITIVE, init-value=0, base-type=BT_ACT410_Sonderfunktionen, invalid-value=Invalid_ACT410_Sonderfunktionen_XIX_ACTs_410_Status_XIX_Klima_LIN5:3, compu {0=Cx0_Keine_Sonderfunktion_aktiv (CM_ACT410_Sonderfunktionen_Cx0_Keine_Sonderfunktion_aktiv), 1=Cx1_Sonderfunktion1_aktiv (CM_ACT410_Sonderfunktionen_Cx1_Sonderfunktion1_aktiv), 2=Cx2_Sonderfunktion2_aktiv (CM_ACT410_Sonderfunktionen_Cx2_Sonderfunktion2_aktiv), 3=Cx3_Fehler (CM_ACT410_Sonderfunktionen_Cx3_Fehler)}, range raw 0..3, transfer-property=PENDING, to Klima(timeout 3.5 s)  # Funktionen des Aktuators
            signal ACT410_Variante_XIX_ACTs_410_Status_XIX_Klima_LIN5: start 46, 2 bit, little-endian, data-type-policy=OVERRIDE, i-signal-type=PRIMITIVE, init-value=0, base-type=BT_ACT410_Variante, compu {0=Cx0_Variante_1 (CM_ACT410_Variante_Cx0_Variante_1), 1=Cx1_Variante_2 (CM_ACT410_Variante_Cx1_Variante_2), 2=Cx2_Variante_3 (CM_ACT410_Variante_Cx2_Variante_3), 3=Cx3_Fehler_oder_nicht_umgesetzt (CM_ACT410_Variante_Cx3_Fehler_oder_nicht_umgesetzt)}, range raw 0..3, transfer-property=PENDING, to Klima(timeout 3.5 s)  # Das Signal gibt an welche Variante des Stellmotors verbaut ist
            signal ACT410_Adresse_Aktuator_XIX_ACTs_410_Status_XIX_Klima_LIN5: start 48, 8 bit, little-endian, data-type-policy=OVERRIDE, i-signal-type=PRIMITIVE, init-value=255, base-type=BT_ACT410_Adresse_Aktuator, compu {255=Cxff_Init (CM_ACT410_Adresse_Aktuator_Cxff_Init)}, range raw 255, transfer-property=PENDING, to Klima(timeout 3.5 s)  # Adresse Aktuator
            signal ACT410_Notlauffreigabe_XIX_ACTs_410_Status_XIX_Klima_LIN5: start 56, 2 bit, little-endian, data-type-policy=OVERRIDE, i-signal-type=PRIMITIVE, init-value=0, base-type=BT_ACT410_Notlauffreigabe, invalid-value=Invalid_ACT410_Notlauffreigabe_XIX_ACTs_410_Status_XIX_Klima_LIN5:3, compu {0=Cx0_Notlauf_aus (CM_ACT410_Notlauffreigabe_Cx0_Notlauf_aus), 1=Cx1_Notlauf_ein (CM_ACT410_Notlauffreigabe_Cx1_Notlauf_ein), 2=Cx2_reserviert (CM_ACT410_Notlauffreigabe_Cx2_reserviert), 3=Cx3_Fehler (CM_ACT410_Notlauffreigabe_Cx3_Fehler)}, range raw 0..3, transfer-property=PENDING, to Klima(timeout 3.5 s)  # Freigabe der Notlauffunktion des Aktuators
            signal ACT410_Notlaufposition_XIX_ACTs_410_Status_XIX_Klima_LIN5: start 58, 2 bit, little-endian, data-type-policy=OVERRIDE, i-signal-type=PRIMITIVE, init-value=0, base-type=BT_ACT410_Notlaufposition, invalid-value=Invalid_ACT410_Notlaufposition_XIX_ACTs_410_Status_XIX_Klima_LIN5:3, compu {0=Cx0_unterer_Anschlag (CM_ACT410_Notlaufposition_Cx0_unterer_Anschlag), 1=Cx1_oberer_Anschlag (CM_ACT410_Notlaufposition_Cx1_oberer_Anschlag), 2=Cx2_reserviert (CM_ACT410_Notlaufposition_Cx2_reserviert), 3=Cx3_Fehler (CM_ACT410_Notlaufposition_Cx3_Fehler)}, range raw 0..3, transfer-property=PENDING, to Klima(timeout 3.5 s)  # Positionsvorgabe des Aktuators
            signal ACT410_Drehrichtung_XIX_ACTs_410_Status_XIX_Klima_LIN5: start 60, 2 bit, little-endian, data-type-policy=OVERRIDE, i-signal-type=PRIMITIVE, init-value=0, base-type=BT_ACT410_Drehrichtung, invalid-value=Invalid_ACT410_Drehrichtung_XIX_ACTs_410_Status_XIX_Klima_LIN5:3, compu {0=Cx0_Bewegung_in_Richtung_CW (CM_ACT410_Drehrichtung_Cx0_Bewegung_in_Richtung_CW), 1=Cx1_Bewegung_in_Richtung_CCW (CM_ACT410_Drehrichtung_Cx1_Bewegung_in_Richtung_CCW), 2=Cx2_reserviert (CM_ACT410_Drehrichtung_Cx2_reserviert), 3=Cx3_Fehler (CM_ACT410_Drehrichtung_Cx3_Fehler)}, range raw 0..3, transfer-property=PENDING, to Klima(timeout 3.5 s)  # Drehrichtung des Aktuators
            signal ACT410_Stopmodus_XIX_ACTs_410_Status_XIX_Klima_LIN5: start 62, 2 bit, little-endian, data-type-policy=OVERRIDE, i-signal-type=PRIMITIVE, init-value=0, base-type=BT_ACT410_Stopmodus, invalid-value=Invalid_ACT410_Stopmodus_XIX_ACTs_410_Status_XIX_Klima_LIN5:3, compu {0=Cx0_Normal_Mode (CM_ACT410_Stopmodus_Cx0_Normal_Mode), 1=Cx1_Stop_Mode (CM_ACT410_Stopmodus_Cx1_Stop_Mode), 2=Cx2_reserviert (CM_ACT410_Stopmodus_Cx2_reserviert), 3=Cx3_Fehler (CM_ACT410_Stopmodus_Cx3_Fehler)}, range raw 0..3, transfer-property=PENDING, to Klima(timeout 3.5 s)  # Modus des Aktuators
        frame ACTs_411_Status_XIX_Klima_LIN5: id 0x2E, to Klima, frame-length=8, lin-checksum=ENHANCED
          pdu ACTs_411_Status_XIX_Klima_LIN5: length=8, unused-bit-pattern=0
            signal ACT411_ResponseError_XIX_ACTs_411_Status_XIX_Klima_LIN5: start 0, 1 bit, little-endian, data-type-policy=OVERRIDE, i-signal-type=PRIMITIVE, init-value=0, base-type=BT_ACT411_ResponseError, invalid-value=Invalid_ACT411_ResponseError_XIX_ACTs_411_Status_XIX_Klima_LIN5:1, compu {0=Cx0_normal (CM_ACT411_ResponseError_Cx0_normal), 1=Cx1_Fehler (CM_ACT411_ResponseError_Cx1_Fehler)}, range raw 0..1, transfer-property=PENDING, to Klima(timeout 3.5 s)  # siehe LIN2.0-Specification (Darf nicht über ein Fehlergueltigkeitsbit abgesichtert werden!)
            signal ACT411_Uebertemperatur_XIX_ACTs_411_Status_XIX_Klima_LIN5: start 2, 2 bit, little-endian, data-type-policy=OVERRIDE, i-signal-type=PRIMITIVE, init-value=0, base-type=BT_ACT411_Uebertemperatur, invalid-value=Invalid_ACT411_Uebertemperatur_XIX_ACTs_411_Status_XIX_Klima_LIN5:3, compu {0=Cx0_keine_Uebertemperatur (CM_ACT411_Uebertemperatur_Cx0_keine_Uebertemperatur), 1=Cx1_Uebertemperatur (CM_ACT411_Uebertemperatur_Cx1_Uebertemperatur), 2=Cx2_reserviert (CM_ACT411_Uebertemperatur_Cx2_reserviert), 3=Cx3_Fehler (CM_ACT411_Uebertemperatur_Cx3_Fehler)}, range raw 0..3, transfer-property=PENDING, to Klima(timeout 3.5 s)  # Anzeige einer Übertemperatur im Stellmotoren-ASIC
            signal ACT411_Elektr_Defekt_XIX_ACTs_411_Status_XIX_Klima_LIN5: start 4, 2 bit, little-endian, data-type-policy=OVERRIDE, i-signal-type=PRIMITIVE, init-value=0, base-type=BT_ACT411_Elektr_Defekt, invalid-value=Invalid_ACT411_Elektr_Defekt_XIX_ACTs_411_Status_XIX_Klima_LIN5:3, compu {0=Cx0_kein_Fehler (CM_ACT411_Elektr_Defekt_Cx0_kein_Fehler), 1=Cx1_Elektrischer_Fehler_vorhanden (CM_ACT411_Elektr_Defekt_Cx1_Elektrischer_Fehler_vorhanden), 2=Cx2_Permanent_elekt_Fehler_vorhanden (CM_ACT411_Elektr_Defekt_Cx2_Permanent_elekt_Fehler_vorhanden), 3=Cx3_Fehler (CM_ACT411_Elektr_Defekt_Cx3_Fehler)}, range raw 0..3, transfer-property=PENDING, to Klima(timeout 3.5 s)  # Anzeige für einen elektrischen Fehler oder einen permanent el. Fehler im Stellmotor
            signal ACT411_Versorgungsspannung_XIX_ACTs_411_Status_XIX_Klima_LIN5: start 6, 2 bit, little-endian, data-type-policy=OVERRIDE, i-signal-type=PRIMITIVE, init-value=0, base-type=BT_ACT411_Versorgungsspannung, invalid-value=Invalid_ACT411_Versorgungsspannung_XIX_ACTs_411_Status_XIX_Klima_LIN5:3, compu {0=Cx0_Spannung_im_zulaessigen_Bereich (CM_ACT411_Versorgungsspannung_Cx0_Spannung_im_zulaessigen_Bereich), 1=Cx1_Unterspannung (CM_ACT411_Versorgungsspannung_Cx1_Unterspannung), 2=Cx2_Ueberspanung (CM_ACT411_Versorgungsspannung_Cx2_Ueberspanung), 3=Cx3_Fehler (CM_ACT411_Versorgungsspannung_Cx3_Fehler)}, range raw 0..3, transfer-property=PENDING, to Klima(timeout 3.5 s)  # Versorgungsspannung des Aktuators
            signal ACT411_Notlauf_aufgetreten_XIX_ACTs_411_Status_XIX_Klima_LIN5: start 8, 2 bit, little-endian, data-type-policy=OVERRIDE, i-signal-type=PRIMITIVE, init-value=0, base-type=BT_ACT411_Notlauf_aufgetreten, invalid-value=Invalid_ACT411_Notlauf_aufgetreten_XIX_ACTs_411_Status_XIX_Klima_LIN5:3, compu {0=Cx0_kein_Notlauf_aufgetreten (CM_ACT411_Notlauf_aufgetreten_Cx0_kein_Notlauf_aufgetreten), 1=Cx1_Notlauf_aufgetreten (CM_ACT411_Notlauf_aufgetreten_Cx1_Notlauf_aufgetreten), 2=Cx2_reserviert (CM_ACT411_Notlauf_aufgetreten_Cx2_reserviert), 3=Cx3_Fehler (CM_ACT411_Notlauf_aufgetreten_Cx3_Fehler)}, range raw 0..3, transfer-property=PENDING, to Klima(timeout 3.5 s)  # Anzeige eines aufgetretenen Notlaufs seit dem letzten Reset oder "Clear Notlauf aufgetreten"
            signal ACT411_Freigabe_Blockiererkennung_XIX_ACTs_411_Status_XIX_Klima_LIN5: start 10, 2 bit, little-endian, data-type-policy=OVERRIDE, i-signal-type=PRIMITIVE, init-value=0, base-type=BT_ACT411_Freigabe_Blockiererkennung, invalid-value=Invalid_ACT411_Freigabe_Blockiererkennung_XIX_ACTs_411_Status_XIX_Klima_LIN5:3, compu {0=Cx0_Blockiererkennung_aus (CM_ACT411_Freigabe_Blockiererkennung_Cx0_Blockiererkennung_aus), 1=Cx1_Blockiererkennung_ein (CM_ACT411_Freigabe_Blockiererkennung_Cx1_Blockiererkennung_ein), 2=Cx2_reserviert (CM_ACT411_Freigabe_Blockiererkennung_Cx2_reserviert), 3=Cx3_Fehler (CM_ACT411_Freigabe_Blockiererkennung_Cx3_Fehler)}, range raw 0..3, transfer-property=PENDING, to Klima(timeout 3.5 s)  # Aktivierung der Blockiererkennung im Aktuator
            signal ACT411_Blockierung_aufgetreten_XIX_ACTs_411_Status_XIX_Klima_LIN5: start 12, 2 bit, little-endian, data-type-policy=OVERRIDE, i-signal-type=PRIMITIVE, init-value=0, base-type=BT_ACT411_Blockierung_aufgetreten, invalid-value=Invalid_ACT411_Blockierung_aufgetreten_XIX_ACTs_411_Status_XIX_Klima_LIN5:3, compu {0=Cx0_keine_Blockierung (CM_ACT411_Blockierung_aufgetreten_Cx0_keine_Blockierung), 1=Cx1_Blockierung_erkannt (CM_ACT411_Blockierung_aufgetreten_Cx1_Blockierung_erkannt), 2=Cx2_reserviert (CM_ACT411_Blockierung_aufgetreten_Cx2_reserviert), 3=Cx3_Fehler (CM_ACT411_Blockierung_aufgetreten_Cx3_Fehler)}, range raw 0..3, transfer-property=PENDING, to Klima(timeout 3.5 s)  # Anzeige einer aufgetretenen Blockierung seit dem letzten Reset oder "Clear Blockierung aufgetreten"
            signal ACT411_Reset_XIX_ACTs_411_Status_XIX_Klima_LIN5: start 14, 2 bit, little-endian, data-type-policy=OVERRIDE, i-signal-type=PRIMITIVE, init-value=0, base-type=BT_ACT411_Reset, invalid-value=Invalid_ACT411_Reset_XIX_ACTs_411_Status_XIX_Klima_LIN5:3, compu {0=Cx0_kein_Reset (CM_ACT411_Reset_Cx0_kein_Reset), 1=Cx1_Reset_durchgefuehrt (CM_ACT411_Reset_Cx1_Reset_durchgefuehrt), 2=Cx2_reserviert (CM_ACT411_Reset_Cx2_reserviert), 3=Cx3_Fehler (CM_ACT411_Reset_Cx3_Fehler)}, range raw 0..3, transfer-property=PENDING, to Klima(timeout 3.5 s)  # Anzeige eines aufgetretenen Reset seit dem letzten ¿Clear Reset"
            signal ACT411_Spulenbestromung_XIX_ACTs_411_Status_XIX_Klima_LIN5: start 16, 2 bit, little-endian, data-type-policy=OVERRIDE, i-signal-type=PRIMITIVE, init-value=0, base-type=BT_ACT411_Spulenbestromung, invalid-value=Invalid_ACT411_Spulenbestromung_XIX_ACTs_411_Status_XIX_Klima_LIN5:3, compu {0=Cx0_Motorspulen_unbestromt (CM_ACT411_Spulenbestromung_Cx0_Motorspulen_unbestromt), 1=Cx1_Motorspulen_bestromt (CM_ACT411_Spulenbestromung_Cx1_Motorspulen_bestromt), 2=Cx2_reserviert (CM_ACT411_Spulenbestromung_Cx2_reserviert), 3=Cx3_Fehler (CM_ACT411_Spulenbestromung_Cx3_Fehler)}, range raw 0..3, transfer-property=PENDING, to Klima(timeout 3.5 s)  # Spulenbestromung im Haltezustand des Aktuators
            signal ACT411_Positionsvorgabe_Status_XIX_ACTs_411_Status_XIX_Klima_LIN5: start 18, 2 bit, little-endian, data-type-policy=OVERRIDE, i-signal-type=PRIMITIVE, init-value=0, base-type=BT_ACT411_Positionsvorgabe_Status, invalid-value=Invalid_ACT411_Positionsvorgabe_Status_XIX_ACTs_411_Status_XIX_Klima_LIN5:3, compu {0=Cx0_Soll_Position_gueltig (CM_ACT411_Positionsvorgabe_Status_Cx0_Soll_Position_gueltig), 1=Cx1_Start_Position_gueltig (CM_ACT411_Positionsvorgabe_Status_Cx1_Start_Position_gueltig), 2=Cx2_keine_Positionsvorgabe_gueltig (CM_ACT411_Positionsvorgabe_Status_Cx2_keine_Positionsvorgabe_gueltig), 3=Cx3_Fehler (CM_ACT411_Positionsvorgabe_Status_Cx3_Fehler)}, range raw 0..3, transfer-property=PENDING, to Klima(timeout 3.5 s)  # Position des Aktuators
            signal ACT411_Geschwindigkeitsstatus_XIX_ACTs_411_Status_XIX_Klima_LIN5: start 20, 4 bit, little-endian, data-type-policy=OVERRIDE, i-signal-type=PRIMITIVE, init-value=0, base-type=BT_ACT411_Geschwindigkeitsstatus, invalid-value=Invalid_ACT411_Geschwindigkeitsstatus_XIX_ACTs_411_Status_XIX_Klima_LIN5:15, compu {0=Cx0_Motor_steht (CM_ACT411_Geschwindigkeitsstatus_Cx0_Motor_steht), 1=Cx1_Geschwindigkeitsstufe_1 (CM_ACT411_Geschwindigkeitsstatus_Cx1_Geschwindigkeitsstufe_1), 2=Cx2_Geschwindigkeitsstufe_2 (CM_ACT411_Geschwindigkeitsstatus_Cx2_Geschwindigkeitsstufe_2), 3=Cx3_Geschwindigkeitsstufe_3 (CM_ACT411_Geschwindigkeitsstatus_Cx3_Geschwindigkeitsstufe_3), 4=Cx4_Geschwindigkeitsstufe_4 (CM_ACT411_Geschwindigkeitsstatus_Cx4_Geschwindigkeitsstufe_4), 5=Cx5_Autospeed (CM_ACT411_Geschwindigkeitsstatus_Cx5_Autospeed), 15=Cxf_Fehler (CM_ACT411_Geschwindigkeitsstatus_Cxf_Fehler)}, range raw 0..15, transfer-property=PENDING, to Klima(timeout 3.5 s)  # Geschwindigkeitsstufe mit der die aktuelle Verfahrbewegung durchgeführt wird
            signal ACT411_Ist_Position_Aktuator_XIX_ACTs_411_Status_XIX_Klima_LIN5: start 24, 16 bit, little-endian, data-type-policy=OVERRIDE, i-signal-type=PRIMITIVE, init-value=32767, base-type=BT_ACT411_Ist_Position_Aktuator, invalid-value=Invalid_ACT411_Ist_Position_Aktuator_XIX_ACTs_411_Status_XIX_Klima_LIN5:65535, compu {phys=raw for raw 0..65534, 65535=Cxffff_Fehler (CM_ACT411_Ist_Position_Aktuator_Cxffff_Fehler); unit Unit_None}, range phys 0..65534 Unit_None, raw 0..65535, unit=Unit_None, transfer-property=PENDING, to Klima(timeout 3.5 s)  # IST-Position des Aktuators
            signal ACT411_Verfahrrichtung_XIX_ACTs_411_Status_XIX_Klima_LIN5: start 40, 2 bit, little-endian, data-type-policy=OVERRIDE, i-signal-type=PRIMITIVE, init-value=2, base-type=BT_ACT411_Verfahrrichtung, invalid-value=Invalid_ACT411_Verfahrrichtung_XIX_ACTs_411_Status_XIX_Klima_LIN5:3, compu {0=Cx0_Richtung_kl_Schrittpositionen (CM_ACT411_Verfahrrichtung_Cx0_Richtung_kl_Schrittpositionen), 1=Cx1_Richtung_gr_Schrittpositionen (CM_ACT411_Verfahrrichtung_Cx1_Richtung_gr_Schrittpositionen), 2=Cx2_Init (CM_ACT411_Verfahrrichtung_Cx2_Init), 3=Cx3_Fehler (CM_ACT411_Verfahrrichtung_Cx3_Fehler)}, range raw 0..3, transfer-property=PENDING, to Klima(timeout 3.5 s)  # Verfahrrichtung der aktuellen oder zuletzt stattgefundenen Bewegung des Aktuators
            signal ACT411_Selbsthaltemoment_XIX_ACTs_411_Status_XIX_Klima_LIN5: start 42, 2 bit, little-endian, data-type-policy=OVERRIDE, i-signal-type=PRIMITIVE, init-value=0, base-type=BT_ACT411_Selbsthaltemoment, invalid-value=Invalid_ACT411_Selbsthaltemoment_XIX_ACTs_411_Status_XIX_Klima_LIN5:3, compu {0=Cx0_ohne_Selbsthaltemoment (CM_ACT411_Selbsthaltemoment_Cx0_ohne_Selbsthaltemoment), 1=Cx1_mit_Selbsthaltemoment (CM_ACT411_Selbsthaltemoment_Cx1_mit_Selbsthaltemoment), 2=Cx2_reserviert (CM_ACT411_Selbsthaltemoment_Cx2_reserviert), 3=Cx3_Fehler (CM_ACT411_Selbsthaltemoment_Cx3_Fehler)}, range raw 0..3, transfer-property=PENDING, to Klima(timeout 3.5 s)  # Das Signal gibt an ob ein selbsthemmendes Getriebe verbaut ist oder die SHB eingeschaltet ist
            signal ACT411_Sonderfunktionen_XIX_ACTs_411_Status_XIX_Klima_LIN5: start 44, 2 bit, little-endian, data-type-policy=OVERRIDE, i-signal-type=PRIMITIVE, init-value=0, base-type=BT_ACT411_Sonderfunktionen, invalid-value=Invalid_ACT411_Sonderfunktionen_XIX_ACTs_411_Status_XIX_Klima_LIN5:3, compu {0=Cx0_Keine_Sonderfunktion_aktiv (CM_ACT411_Sonderfunktionen_Cx0_Keine_Sonderfunktion_aktiv), 1=Cx1_Sonderfunktion1_aktiv (CM_ACT411_Sonderfunktionen_Cx1_Sonderfunktion1_aktiv), 2=Cx2_Sonderfunktion2_aktiv (CM_ACT411_Sonderfunktionen_Cx2_Sonderfunktion2_aktiv), 3=Cx3_Fehler (CM_ACT411_Sonderfunktionen_Cx3_Fehler)}, range raw 0..3, transfer-property=PENDING, to Klima(timeout 3.5 s)  # Funktionen des Aktuators
            signal ACT411_Variante_XIX_ACTs_411_Status_XIX_Klima_LIN5: start 46, 2 bit, little-endian, data-type-policy=OVERRIDE, i-signal-type=PRIMITIVE, init-value=0, base-type=BT_ACT411_Variante, compu {0=Cx0_Variante_1 (CM_ACT411_Variante_Cx0_Variante_1), 1=Cx1_Variante_2 (CM_ACT411_Variante_Cx1_Variante_2), 2=Cx2_Variante_3 (CM_ACT411_Variante_Cx2_Variante_3), 3=Cx3_Fehler_oder_nicht_umgesetzt (CM_ACT411_Variante_Cx3_Fehler_oder_nicht_umgesetzt)}, range raw 0..3, transfer-property=PENDING, to Klima(timeout 3.5 s)  # Das Signal gibt an welche Variante des Stellmotors verbaut ist
            signal ACT411_Adresse_Aktuator_XIX_ACTs_411_Status_XIX_Klima_LIN5: start 48, 8 bit, little-endian, data-type-policy=OVERRIDE, i-signal-type=PRIMITIVE, init-value=255, base-type=BT_ACT411_Adresse_Aktuator, compu {255=Cxff_Init (CM_ACT411_Adresse_Aktuator_Cxff_Init)}, range raw 255, transfer-property=PENDING, to Klima(timeout 3.5 s)  # Adresse Aktuator
            signal ACT411_Notlauffreigabe_XIX_ACTs_411_Status_XIX_Klima_LIN5: start 56, 2 bit, little-endian, data-type-policy=OVERRIDE, i-signal-type=PRIMITIVE, init-value=0, base-type=BT_ACT411_Notlauffreigabe, invalid-value=Invalid_ACT411_Notlauffreigabe_XIX_ACTs_411_Status_XIX_Klima_LIN5:3, compu {0=Cx0_Notlauf_aus (CM_ACT411_Notlauffreigabe_Cx0_Notlauf_aus), 1=Cx1_Notlauf_ein (CM_ACT411_Notlauffreigabe_Cx1_Notlauf_ein), 2=Cx2_reserviert (CM_ACT411_Notlauffreigabe_Cx2_reserviert), 3=Cx3_Fehler (CM_ACT411_Notlauffreigabe_Cx3_Fehler)}, range raw 0..3, transfer-property=PENDING, to Klima(timeout 3.5 s)  # Freigabe der Notlauffunktion des Aktuators
            signal ACT411_Notlaufposition_XIX_ACTs_411_Status_XIX_Klima_LIN5: start 58, 2 bit, little-endian, data-type-policy=OVERRIDE, i-signal-type=PRIMITIVE, init-value=0, base-type=BT_ACT411_Notlaufposition, invalid-value=Invalid_ACT411_Notlaufposition_XIX_ACTs_411_Status_XIX_Klima_LIN5:3, compu {0=Cx0_unterer_Anschlag (CM_ACT411_Notlaufposition_Cx0_unterer_Anschlag), 1=Cx1_oberer_Anschlag (CM_ACT411_Notlaufposition_Cx1_oberer_Anschlag), 2=Cx2_reserviert (CM_ACT411_Notlaufposition_Cx2_reserviert), 3=Cx3_Fehler (CM_ACT411_Notlaufposition_Cx3_Fehler)}, range raw 0..3, transfer-property=PENDING, to Klima(timeout 3.5 s)  # Positionsvorgabe des Aktuators
            signal ACT411_Drehrichtung_XIX_ACTs_411_Status_XIX_Klima_LIN5: start 60, 2 bit, little-endian, data-type-policy=OVERRIDE, i-signal-type=PRIMITIVE, init-value=0, base-type=BT_ACT411_Drehrichtung, invalid-value=Invalid_ACT411_Drehrichtung_XIX_ACTs_411_Status_XIX_Klima_LIN5:3, compu {0=Cx0_Bewegung_in_Richtung_CW (CM_ACT411_Drehrichtung_Cx0_Bewegung_in_Richtung_CW), 1=Cx1_Bewegung_in_Richtung_CCW (CM_ACT411_Drehrichtung_Cx1_Bewegung_in_Richtung_CCW), 2=Cx2_reserviert (CM_ACT411_Drehrichtung_Cx2_reserviert), 3=Cx3_Fehler (CM_ACT411_Drehrichtung_Cx3_Fehler)}, range raw 0..3, transfer-property=PENDING, to Klima(timeout 3.5 s)  # Drehrichtung des Aktuators
            signal ACT411_Stopmodus_XIX_ACTs_411_Status_XIX_Klima_LIN5: start 62, 2 bit, little-endian, data-type-policy=OVERRIDE, i-signal-type=PRIMITIVE, init-value=0, base-type=BT_ACT411_Stopmodus, invalid-value=Invalid_ACT411_Stopmodus_XIX_ACTs_411_Status_XIX_Klima_LIN5:3, compu {0=Cx0_Normal_Mode (CM_ACT411_Stopmodus_Cx0_Normal_Mode), 1=Cx1_Stop_Mode (CM_ACT411_Stopmodus_Cx1_Stop_Mode), 2=Cx2_reserviert (CM_ACT411_Stopmodus_Cx2_reserviert), 3=Cx3_Fehler (CM_ACT411_Stopmodus_Cx3_Fehler)}, range raw 0..3, transfer-property=PENDING, to Klima(timeout 3.5 s)  # Modus des Aktuators
        frame ACTs_412_Status_XIX_Klima_LIN5: id 0x35, to Klima, frame-length=8, lin-checksum=ENHANCED
          pdu ACTs_412_Status_XIX_Klima_LIN5: length=8, unused-bit-pattern=0
            signal ACT412_ResponseError_XIX_ACTs_412_Status_XIX_Klima_LIN5: start 0, 1 bit, little-endian, data-type-policy=OVERRIDE, i-signal-type=PRIMITIVE, init-value=0, base-type=BT_ACT412_ResponseError, invalid-value=Invalid_ACT412_ResponseError_XIX_ACTs_412_Status_XIX_Klima_LIN5:1, compu {0=Cx0_normal (CM_ACT412_ResponseError_Cx0_normal), 1=Cx1_Fehler (CM_ACT412_ResponseError_Cx1_Fehler)}, range raw 0..1, transfer-property=PENDING, to Klima(timeout 3.5 s)  # siehe LIN2.0-Specification (Darf nicht über ein Fehlergueltigkeitsbit abgesichtert werden!)
            signal ACT412_Uebertemperatur_XIX_ACTs_412_Status_XIX_Klima_LIN5: start 2, 2 bit, little-endian, data-type-policy=OVERRIDE, i-signal-type=PRIMITIVE, init-value=0, base-type=BT_ACT412_Uebertemperatur, invalid-value=Invalid_ACT412_Uebertemperatur_XIX_ACTs_412_Status_XIX_Klima_LIN5:3, compu {0=Cx0_keine_Uebertemperatur (CM_ACT412_Uebertemperatur_Cx0_keine_Uebertemperatur), 1=Cx1_Uebertemperatur (CM_ACT412_Uebertemperatur_Cx1_Uebertemperatur), 2=Cx2_reserviert (CM_ACT412_Uebertemperatur_Cx2_reserviert), 3=Cx3_Fehler (CM_ACT412_Uebertemperatur_Cx3_Fehler)}, range raw 0..3, transfer-property=PENDING, to Klima(timeout 3.5 s)  # Anzeige einer Übertemperatur im Stellmotoren-ASIC
            signal ACT412_Elektr_Defekt_XIX_ACTs_412_Status_XIX_Klima_LIN5: start 4, 2 bit, little-endian, data-type-policy=OVERRIDE, i-signal-type=PRIMITIVE, init-value=0, base-type=BT_ACT412_Elektr_Defekt, invalid-value=Invalid_ACT412_Elektr_Defekt_XIX_ACTs_412_Status_XIX_Klima_LIN5:3, compu {0=Cx0_kein_Fehler (CM_ACT412_Elektr_Defekt_Cx0_kein_Fehler), 1=Cx1_Elektrischer_Fehler_vorhanden (CM_ACT412_Elektr_Defekt_Cx1_Elektrischer_Fehler_vorhanden), 2=Cx2_Permanent_elekt_Fehler_vorhanden (CM_ACT412_Elektr_Defekt_Cx2_Permanent_elekt_Fehler_vorhanden), 3=Cx3_Fehler (CM_ACT412_Elektr_Defekt_Cx3_Fehler)}, range raw 0..3, transfer-property=PENDING, to Klima(timeout 3.5 s)  # Anzeige für einen elektrischen Fehler oder einen permanent el. Fehler im Stellmotor
            signal ACT412_Versorgungsspannung_XIX_ACTs_412_Status_XIX_Klima_LIN5: start 6, 2 bit, little-endian, data-type-policy=OVERRIDE, i-signal-type=PRIMITIVE, init-value=0, base-type=BT_ACT412_Versorgungsspannung, invalid-value=Invalid_ACT412_Versorgungsspannung_XIX_ACTs_412_Status_XIX_Klima_LIN5:3, compu {0=Cx0_Spannung_im_zulaessigen_Bereich (CM_ACT412_Versorgungsspannung_Cx0_Spannung_im_zulaessigen_Bereich), 1=Cx1_Unterspannung (CM_ACT412_Versorgungsspannung_Cx1_Unterspannung), 2=Cx2_Ueberspanung (CM_ACT412_Versorgungsspannung_Cx2_Ueberspanung), 3=Cx3_Fehler (CM_ACT412_Versorgungsspannung_Cx3_Fehler)}, range raw 0..3, transfer-property=PENDING, to Klima(timeout 3.5 s)  # Versorgungsspannung des Aktuators
            signal ACT412_Notlauf_aufgetreten_XIX_ACTs_412_Status_XIX_Klima_LIN5: start 8, 2 bit, little-endian, data-type-policy=OVERRIDE, i-signal-type=PRIMITIVE, init-value=0, base-type=BT_ACT412_Notlauf_aufgetreten, invalid-value=Invalid_ACT412_Notlauf_aufgetreten_XIX_ACTs_412_Status_XIX_Klima_LIN5:3, compu {0=Cx0_kein_Notlauf_aufgetreten (CM_ACT412_Notlauf_aufgetreten_Cx0_kein_Notlauf_aufgetreten), 1=Cx1_Notlauf_aufgetreten (CM_ACT412_Notlauf_aufgetreten_Cx1_Notlauf_aufgetreten), 2=Cx2_reserviert (CM_ACT412_Notlauf_aufgetreten_Cx2_reserviert), 3=Cx3_Fehler (CM_ACT412_Notlauf_aufgetreten_Cx3_Fehler)}, range raw 0..3, transfer-property=PENDING, to Klima(timeout 3.5 s)  # Anzeige eines aufgetretenen Notlaufs seit dem letzten Reset oder "Clear Notlauf aufgetreten"
            signal ACT412_Freigabe_Blockiererkennung_XIX_ACTs_412_Status_XIX_Klima_LIN5: start 10, 2 bit, little-endian, data-type-policy=OVERRIDE, i-signal-type=PRIMITIVE, init-value=0, base-type=BT_ACT412_Freigabe_Blockiererkennung, invalid-value=Invalid_ACT412_Freigabe_Blockiererkennung_XIX_ACTs_412_Status_XIX_Klima_LIN5:3, compu {0=Cx0_Blockiererkennung_aus (CM_ACT412_Freigabe_Blockiererkennung_Cx0_Blockiererkennung_aus), 1=Cx1_Blockiererkennung_ein (CM_ACT412_Freigabe_Blockiererkennung_Cx1_Blockiererkennung_ein), 2=Cx2_reserviert (CM_ACT412_Freigabe_Blockiererkennung_Cx2_reserviert), 3=Cx3_Fehler (CM_ACT412_Freigabe_Blockiererkennung_Cx3_Fehler)}, range raw 0..3, transfer-property=PENDING, to Klima(timeout 3.5 s)  # Aktivierung der Blockiererkennung im Aktuator
            signal ACT412_Blockierung_aufgetreten_XIX_ACTs_412_Status_XIX_Klima_LIN5: start 12, 2 bit, little-endian, data-type-policy=OVERRIDE, i-signal-type=PRIMITIVE, init-value=0, base-type=BT_ACT412_Blockierung_aufgetreten, invalid-value=Invalid_ACT412_Blockierung_aufgetreten_XIX_ACTs_412_Status_XIX_Klima_LIN5:3, compu {0=Cx0_keine_Blockierung (CM_ACT412_Blockierung_aufgetreten_Cx0_keine_Blockierung), 1=Cx1_Blockierung_erkannt (CM_ACT412_Blockierung_aufgetreten_Cx1_Blockierung_erkannt), 2=Cx2_reserviert (CM_ACT412_Blockierung_aufgetreten_Cx2_reserviert), 3=Cx3_Fehler (CM_ACT412_Blockierung_aufgetreten_Cx3_Fehler)}, range raw 0..3, transfer-property=PENDING, to Klima(timeout 3.5 s)  # Anzeige einer aufgetretenen Blockierung seit dem letzten Reset oder "Clear Blockierung aufgetreten"
            signal ACT412_Reset_XIX_ACTs_412_Status_XIX_Klima_LIN5: start 14, 2 bit, little-endian, data-type-policy=OVERRIDE, i-signal-type=PRIMITIVE, init-value=0, base-type=BT_ACT412_Reset, invalid-value=Invalid_ACT412_Reset_XIX_ACTs_412_Status_XIX_Klima_LIN5:3, compu {0=Cx0_kein_Reset (CM_ACT412_Reset_Cx0_kein_Reset), 1=Cx1_Reset_durchgefuehrt (CM_ACT412_Reset_Cx1_Reset_durchgefuehrt), 2=Cx2_reserviert (CM_ACT412_Reset_Cx2_reserviert), 3=Cx3_Fehler (CM_ACT412_Reset_Cx3_Fehler)}, range raw 0..3, transfer-property=PENDING, to Klima(timeout 3.5 s)  # Anzeige eines aufgetretenen Reset seit dem letzten ¿Clear Reset"
            signal ACT412_Spulenbestromung_XIX_ACTs_412_Status_XIX_Klima_LIN5: start 16, 2 bit, little-endian, data-type-policy=OVERRIDE, i-signal-type=PRIMITIVE, init-value=0, base-type=BT_ACT412_Spulenbestromung, invalid-value=Invalid_ACT412_Spulenbestromung_XIX_ACTs_412_Status_XIX_Klima_LIN5:3, compu {0=Cx0_Motorspulen_unbestromt (CM_ACT412_Spulenbestromung_Cx0_Motorspulen_unbestromt), 1=Cx1_Motorspulen_bestromt (CM_ACT412_Spulenbestromung_Cx1_Motorspulen_bestromt), 2=Cx2_reserviert (CM_ACT412_Spulenbestromung_Cx2_reserviert), 3=Cx3_Fehler (CM_ACT412_Spulenbestromung_Cx3_Fehler)}, range raw 0..3, transfer-property=PENDING, to Klima(timeout 3.5 s)  # Spulenbestromung im Haltezustand des Aktuators
            signal ACT412_Positionsvorgabe_Status_XIX_ACTs_412_Status_XIX_Klima_LIN5: start 18, 2 bit, little-endian, data-type-policy=OVERRIDE, i-signal-type=PRIMITIVE, init-value=0, base-type=BT_ACT412_Positionsvorgabe_Status, invalid-value=Invalid_ACT412_Positionsvorgabe_Status_XIX_ACTs_412_Status_XIX_Klima_LIN5:3, compu {0=Cx0_Soll_Position_gueltig (CM_ACT412_Positionsvorgabe_Status_Cx0_Soll_Position_gueltig), 1=Cx1_Start_Position_gueltig (CM_ACT412_Positionsvorgabe_Status_Cx1_Start_Position_gueltig), 2=Cx2_keine_Positionsvorgabe_gueltig (CM_ACT412_Positionsvorgabe_Status_Cx2_keine_Positionsvorgabe_gueltig), 3=Cx3_Fehler (CM_ACT412_Positionsvorgabe_Status_Cx3_Fehler)}, range raw 0..3, transfer-property=PENDING, to Klima(timeout 3.5 s)  # Position des Aktuators
            signal ACT412_Geschwindigkeitsstatus_XIX_ACTs_412_Status_XIX_Klima_LIN5: start 20, 4 bit, little-endian, data-type-policy=OVERRIDE, i-signal-type=PRIMITIVE, init-value=0, base-type=BT_ACT412_Geschwindigkeitsstatus, invalid-value=Invalid_ACT412_Geschwindigkeitsstatus_XIX_ACTs_412_Status_XIX_Klima_LIN5:15, compu {0=Cx0_Motor_steht (CM_ACT412_Geschwindigkeitsstatus_Cx0_Motor_steht), 1=Cx1_Geschwindigkeitsstufe_1 (CM_ACT412_Geschwindigkeitsstatus_Cx1_Geschwindigkeitsstufe_1), 2=Cx2_Geschwindigkeitsstufe_2 (CM_ACT412_Geschwindigkeitsstatus_Cx2_Geschwindigkeitsstufe_2), 3=Cx3_Geschwindigkeitsstufe_3 (CM_ACT412_Geschwindigkeitsstatus_Cx3_Geschwindigkeitsstufe_3), 4=Cx4_Geschwindigkeitsstufe_4 (CM_ACT412_Geschwindigkeitsstatus_Cx4_Geschwindigkeitsstufe_4), 5=Cx5_Autospeed (CM_ACT412_Geschwindigkeitsstatus_Cx5_Autospeed), 15=Cxf_Fehler (CM_ACT412_Geschwindigkeitsstatus_Cxf_Fehler)}, range raw 0..15, transfer-property=PENDING, to Klima(timeout 3.5 s)  # Geschwindigkeitsstufe mit der die aktuelle Verfahrbewegung durchgeführt wird
            signal ACT412_Ist_Position_Aktuator_XIX_ACTs_412_Status_XIX_Klima_LIN5: start 24, 16 bit, little-endian, data-type-policy=OVERRIDE, i-signal-type=PRIMITIVE, init-value=32767, base-type=BT_ACT412_Ist_Position_Aktuator, invalid-value=Invalid_ACT412_Ist_Position_Aktuator_XIX_ACTs_412_Status_XIX_Klima_LIN5:65535, compu {phys=raw for raw 0..65534, 65535=Cxffff_Fehler (CM_ACT412_Ist_Position_Aktuator_Cxffff_Fehler); unit Unit_None}, range phys 0..65534 Unit_None, raw 0..65535, unit=Unit_None, transfer-property=PENDING, to Klima(timeout 3.5 s)  # IST-Position des Aktuators
            signal ACT412_Verfahrrichtung_XIX_ACTs_412_Status_XIX_Klima_LIN5: start 40, 2 bit, little-endian, data-type-policy=OVERRIDE, i-signal-type=PRIMITIVE, init-value=2, base-type=BT_ACT412_Verfahrrichtung, invalid-value=Invalid_ACT412_Verfahrrichtung_XIX_ACTs_412_Status_XIX_Klima_LIN5:3, compu {0=Cx0_Richtung_kl_Schrittpositionen (CM_ACT412_Verfahrrichtung_Cx0_Richtung_kl_Schrittpositionen), 1=Cx1_Richtung_gr_Schrittpositionen (CM_ACT412_Verfahrrichtung_Cx1_Richtung_gr_Schrittpositionen), 2=Cx2_Init (CM_ACT412_Verfahrrichtung_Cx2_Init), 3=Cx3_Fehler (CM_ACT412_Verfahrrichtung_Cx3_Fehler)}, range raw 0..3, transfer-property=PENDING, to Klima(timeout 3.5 s)  # Verfahrrichtung der aktuellen oder zuletzt stattgefundenen Bewegung des Aktuators
            signal ACT412_Selbsthaltemoment_XIX_ACTs_412_Status_XIX_Klima_LIN5: start 42, 2 bit, little-endian, data-type-policy=OVERRIDE, i-signal-type=PRIMITIVE, init-value=0, base-type=BT_ACT412_Selbsthaltemoment, invalid-value=Invalid_ACT412_Selbsthaltemoment_XIX_ACTs_412_Status_XIX_Klima_LIN5:3, compu {0=Cx0_ohne_Selbsthaltemoment (CM_ACT412_Selbsthaltemoment_Cx0_ohne_Selbsthaltemoment), 1=Cx1_mit_Selbsthaltemoment (CM_ACT412_Selbsthaltemoment_Cx1_mit_Selbsthaltemoment), 2=Cx2_reserviert (CM_ACT412_Selbsthaltemoment_Cx2_reserviert), 3=Cx3_Fehler (CM_ACT412_Selbsthaltemoment_Cx3_Fehler)}, range raw 0..3, transfer-property=PENDING, to Klima(timeout 3.5 s)  # Das Signal gibt an ob ein selbsthemmendes Getriebe verbaut ist oder die SHB eingeschaltet ist
            signal ACT412_Sonderfunktionen_XIX_ACTs_412_Status_XIX_Klima_LIN5: start 44, 2 bit, little-endian, data-type-policy=OVERRIDE, i-signal-type=PRIMITIVE, init-value=0, base-type=BT_ACT412_Sonderfunktionen, invalid-value=Invalid_ACT412_Sonderfunktionen_XIX_ACTs_412_Status_XIX_Klima_LIN5:3, compu {0=Cx0_Keine_Sonderfunktion_aktiv (CM_ACT412_Sonderfunktionen_Cx0_Keine_Sonderfunktion_aktiv), 1=Cx1_Sonderfunktion1_aktiv (CM_ACT412_Sonderfunktionen_Cx1_Sonderfunktion1_aktiv), 2=Cx2_Sonderfunktion2_aktiv (CM_ACT412_Sonderfunktionen_Cx2_Sonderfunktion2_aktiv), 3=Cx3_Fehler (CM_ACT412_Sonderfunktionen_Cx3_Fehler)}, range raw 0..3, transfer-property=PENDING, to Klima(timeout 3.5 s)  # Funktionen des Aktuators
            signal ACT412_Variante_XIX_ACTs_412_Status_XIX_Klima_LIN5: start 46, 2 bit, little-endian, data-type-policy=OVERRIDE, i-signal-type=PRIMITIVE, init-value=0, base-type=BT_ACT412_Variante, compu {0=Cx0_Variante_1 (CM_ACT412_Variante_Cx0_Variante_1), 1=Cx1_Variante_2 (CM_ACT412_Variante_Cx1_Variante_2), 2=Cx2_Variante_3 (CM_ACT412_Variante_Cx2_Variante_3), 3=Cx3_Fehler_oder_nicht_umgesetzt (CM_ACT412_Variante_Cx3_Fehler_oder_nicht_umgesetzt)}, range raw 0..3, transfer-property=PENDING, to Klima(timeout 3.5 s)  # Das Signal gibt an welche Variante des Stellmotors verbaut ist
            signal ACT412_Adresse_Aktuator_XIX_ACTs_412_Status_XIX_Klima_LIN5: start 48, 8 bit, little-endian, data-type-policy=OVERRIDE, i-signal-type=PRIMITIVE, init-value=255, base-type=BT_ACT412_Adresse_Aktuator, compu {255=Cxff_Init (CM_ACT412_Adresse_Aktuator_Cxff_Init)}, range raw 255, transfer-property=PENDING, to Klima(timeout 3.5 s)  # Adresse Aktuator
            signal ACT412_Notlauffreigabe_XIX_ACTs_412_Status_XIX_Klima_LIN5: start 56, 2 bit, little-endian, data-type-policy=OVERRIDE, i-signal-type=PRIMITIVE, init-value=0, base-type=BT_ACT412_Notlauffreigabe, invalid-value=Invalid_ACT412_Notlauffreigabe_XIX_ACTs_412_Status_XIX_Klima_LIN5:3, compu {0=Cx0_Notlauf_aus (CM_ACT412_Notlauffreigabe_Cx0_Notlauf_aus), 1=Cx1_Notlauf_ein (CM_ACT412_Notlauffreigabe_Cx1_Notlauf_ein), 2=Cx2_reserviert (CM_ACT412_Notlauffreigabe_Cx2_reserviert), 3=Cx3_Fehler (CM_ACT412_Notlauffreigabe_Cx3_Fehler)}, range raw 0..3, transfer-property=PENDING, to Klima(timeout 3.5 s)  # Freigabe der Notlauffunktion des Aktuators
            signal ACT412_Notlaufposition_XIX_ACTs_412_Status_XIX_Klima_LIN5: start 58, 2 bit, little-endian, data-type-policy=OVERRIDE, i-signal-type=PRIMITIVE, init-value=0, base-type=BT_ACT412_Notlaufposition, invalid-value=Invalid_ACT412_Notlaufposition_XIX_ACTs_412_Status_XIX_Klima_LIN5:3, compu {0=Cx0_unterer_Anschlag (CM_ACT412_Notlaufposition_Cx0_unterer_Anschlag), 1=Cx1_oberer_Anschlag (CM_ACT412_Notlaufposition_Cx1_oberer_Anschlag), 2=Cx2_reserviert (CM_ACT412_Notlaufposition_Cx2_reserviert), 3=Cx3_Fehler (CM_ACT412_Notlaufposition_Cx3_Fehler)}, range raw 0..3, transfer-property=PENDING, to Klima(timeout 3.5 s)  # Positionsvorgabe des Aktuators
            signal ACT412_Drehrichtung_XIX_ACTs_412_Status_XIX_Klima_LIN5: start 60, 2 bit, little-endian, data-type-policy=OVERRIDE, i-signal-type=PRIMITIVE, init-value=0, base-type=BT_ACT412_Drehrichtung, invalid-value=Invalid_ACT412_Drehrichtung_XIX_ACTs_412_Status_XIX_Klima_LIN5:3, compu {0=Cx0_Bewegung_in_Richtung_CW (CM_ACT412_Drehrichtung_Cx0_Bewegung_in_Richtung_CW), 1=Cx1_Bewegung_in_Richtung_CCW (CM_ACT412_Drehrichtung_Cx1_Bewegung_in_Richtung_CCW), 2=Cx2_reserviert (CM_ACT412_Drehrichtung_Cx2_reserviert), 3=Cx3_Fehler (CM_ACT412_Drehrichtung_Cx3_Fehler)}, range raw 0..3, transfer-property=PENDING, to Klima(timeout 3.5 s)  # Drehrichtung des Aktuators
            signal ACT412_Stopmodus_XIX_ACTs_412_Status_XIX_Klima_LIN5: start 62, 2 bit, little-endian, data-type-policy=OVERRIDE, i-signal-type=PRIMITIVE, init-value=0, base-type=BT_ACT412_Stopmodus, invalid-value=Invalid_ACT412_Stopmodus_XIX_ACTs_412_Status_XIX_Klima_LIN5:3, compu {0=Cx0_Normal_Mode (CM_ACT412_Stopmodus_Cx0_Normal_Mode), 1=Cx1_Stop_Mode (CM_ACT412_Stopmodus_Cx1_Stop_Mode), 2=Cx2_reserviert (CM_ACT412_Stopmodus_Cx2_reserviert), 3=Cx3_Fehler (CM_ACT412_Stopmodus_Cx3_Fehler)}, range raw 0..3, transfer-property=PENDING, to Klima(timeout 3.5 s)  # Modus des Aktuators
        frame MasterReq_XIX_Klima_LIN5: id 0x3C, from Klima, frame-length=8, lin-checksum=CLASSIC
          n pdu MasterReq_XIX_Klima_LIN5: length=8
        frame SlaveResp_XIX_Klima_LIN5: id 0x3D, to Klima, frame-length=8, lin-checksum=CLASSIC
          n pdu SlaveResp_XIX_Klima_LIN5: length=8
        pdu triggering PT_Klima_LIN5_XIX_TPCHType_LIN_Diagnose_XIX_0x0_XIX_0x{20..27}_XIX_Physical: pdu=DCM_Klima_LIN5_XIX_TPCHType_LIN_Diagnose_XIX_0x0_XIX_0x{20..27}_XIX_Physical, from Klima
        pdu triggering PT_Klima_LIN5_XIX_TPCHType_LIN_Diagnose_XIX_0x{20..27}_XIX_0x0_XIX_Physical: pdu=DCM_Klima_LIN5_XIX_TPCHType_LIN_Diagnose_XIX_0x{20..27}_XIX_0x0_XIX_Physical, to Klima
        4 x lin schedule table, all with resume-position=CONTINUE-AT-IT-POSITION:
          DiagRequest: run-mode=RUN-ONCE, application-entry{delay=0.01, position-in-table=0, frame-triggering=CHNL/FT_MasterReq}
          DiagResponse: run-mode=RUN-ONCE, application-entry{delay=0.01, position-in-table=0, frame-triggering=CHNL/FT_SlaveResp}
          st_main_1: run-mode=RUN-CONTINUOUS
            table-entrys:
              delay=0.01, position-in-table=0, frame-triggering=FT_ACTe_400_Control
              delay=0.01, position-in-table=1, frame-triggering=FT_ACTs_401_Status
              delay=0.01, position-in-table=2, frame-triggering=FT_ACTe_400_Control
              delay=0.01, position-in-table=3, frame-triggering=FT_ACTs_402_Status
              delay=0.01, position-in-table=4, frame-triggering=FT_ACTe_400_Control
              delay=0.01, position-in-table=5, frame-triggering=FT_ACTs_403_Status
              delay=0.01, position-in-table=6, frame-triggering=FT_ACTe_400_Control
              delay=0.01, position-in-table=7, frame-triggering=FT_ACTs_404_Status
              delay=0.01, position-in-table=8, frame-triggering=FT_ACTe_400_Control
              delay=0.01, position-in-table=9, frame-triggering=FT_ACTs_405_Status
              delay=0.01, position-in-table=10, frame-triggering=FT_ACTe_400_Control
              delay=0.01, position-in-table=11, frame-triggering=FT_ACTs_406_Status
              delay=0.01, position-in-table=12, frame-triggering=FT_ACTe_400_Control
              delay=0.01, position-in-table=13, frame-triggering=FT_ACTs_407_Status
              delay=0.01, position-in-table=14, frame-triggering=FT_ACTe_400_Control
              delay=0.01, position-in-table=15, frame-triggering=FT_ACTs_408_Status
          st_main_2: run-mode=RUN-CONTINUOUS
            table-entrys:
              delay=0.01, position-in-table=0, frame-triggering=FT_ACTe_400_Control
              delay=0.01, position-in-table=1, frame-triggering=FT_ACTs_401_Status
              delay=0.01, position-in-table=2, frame-triggering=FT_ACTe_400_Control
              delay=0.01, position-in-table=3, frame-triggering=FT_ACTs_402_Status
              delay=0.01, position-in-table=4, frame-triggering=FT_ACTe_400_Control
              delay=0.01, position-in-table=5, frame-triggering=FT_ACTs_403_Status
              delay=0.01, position-in-table=6, frame-triggering=FT_ACTe_400_Control
              delay=0.01, position-in-table=7, frame-triggering=FT_ACTs_404_Status
              delay=0.01, position-in-table=8, frame-triggering=FT_ACTe_400_Control
              delay=0.01, position-in-table=9, frame-triggering=FT_ACTs_405_Status
              delay=0.01, position-in-table=10, frame-triggering=FT_ACTe_400_Control
              delay=0.01, position-in-table=11, frame-triggering=FT_ACTs_406_Status
              delay=0.01, position-in-table=12, frame-triggering=FT_ACTe_400_Control
              delay=0.01, position-in-table=13, frame-triggering=FT_ACTs_407_Status
              delay=0.01, position-in-table=14, frame-triggering=FT_ACTe_400_Control
              delay=0.01, position-in-table=15, frame-triggering=FT_ACTs_408_Status
              delay=0.01, position-in-table=16, frame-triggering=FT_ACTe_400_Control
              delay=0.01, position-in-table=17, frame-triggering=FT_ACTs_409_Status
              delay=0.01, position-in-table=18, frame-triggering=FT_ACTe_400_Control
              delay=0.01, position-in-table=19, frame-triggering=FT_ACTs_410_Status
              delay=0.01, position-in-table=20, frame-triggering=FT_ACTe_400_Control
              delay=0.01, position-in-table=21, frame-triggering=FT_ACTs_411_Status
              delay=0.01, position-in-table=22, frame-triggering=FT_ACTe_400_Control
              delay=0.01, position-in-table=23, frame-triggering=FT_ACTs_412_Status
package /NmConfig
  nm config NmConfig: can-nm-cluster-coupling{coupled-cluster=NmCluster_E3V_EVCANFD, nm-busload-reduction-enabled=false, nm-immediate-restart-enabled=false}
    can nm cluster NmCluster_E3V_EVCANFD: communication-cluster=E3V_EVCANFD, nm-channel-sleep-master=false, nm-synchronizing-network=false, nm-busload-reduction-active=false, nm-cbv-position=1, nm-immediate-nm-cycle-time=0.01, nm-immediate-nm-transmissions=10, nm-message-timeout-time=0.1, nm-msg-cycle-time=0.2, nm-network-timeout=1.0, nm-nid-position=0, nm-remote-sleep-indication-time=0, nm-repeat-message-time=4.0, nm-wait-bus-sleep-time=0.75
      can nm node NmNode_Klima_XIX_E3V_EVCANFD: controller=CT_E3V_EVCANFD, nm-if-ecu=NmEcu_Klima, nm-passive-mode-enabled=false, rx-nm-pdu=[NMH_DCDC_NV_XIX_E3V_EVCANFD, NMH_Gateway_XIX_E3V_EVCANFD, NMH_Hybrid_01_XIX_E3V_EVCANFD, NMH_Ladegeraet_XIX_E3V_EVCANFD], tx-nm-pdu=NMH_Klima_XIX_E3V_EVCANFD, nm-car-wake-up-rx-enabled=false, nm-msg-cycle-offset=0
    nm-if-ecus:
      nm ecu NmEcu_Klima: ecu-instance=Klima, nm-bus-synchronization-enabled=false, nm-com-control-enabled=false, nm-node-detection-enabled=false, nm-node-id-enabled=false, nm-pdu-rx-indication-enabled=true, nm-remote-sleep-ind-enabled=false, nm-repeat-msg-ind-enabled=false, nm-state-change-ind-enabled=true, nm-user-data-enabled=true
